VERSION ""

NS_ :

BS_:

BU_: VCM TCM OBDScanT2 ECM

BO_ 1059 VMCU_BB2_55P: 8 VCM
 SG_ BatteryCurrent : 16|16@1+ (0.05,-1600) [-1600|1676.75] "A"  ECM

BO_ 1240 VMCU_BB2_29P: 8 VCM
 SG_ FrontAxle2Load : 16|16@1+ (0.5,0) [0|32767.5] "kg"  TCM
 SG_ FrontAxle1Load : 0|16@1+ (0.5,0) [0|32767.5] "kg"  TCM

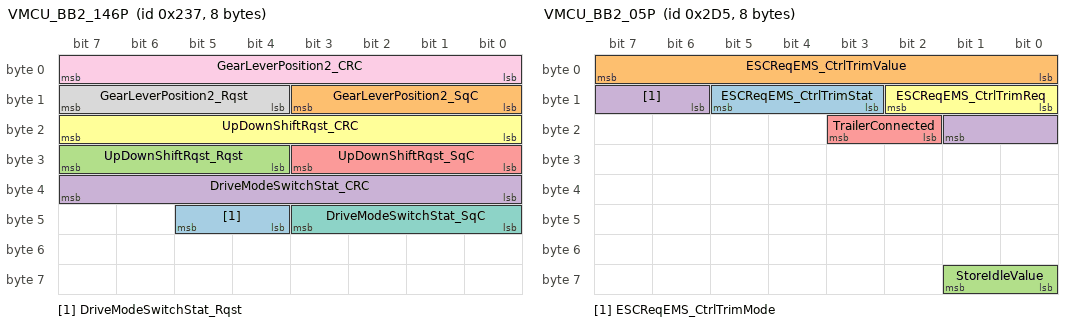
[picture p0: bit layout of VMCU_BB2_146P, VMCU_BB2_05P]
BO_ 567 VMCU_BB2_146P: 8 VCM
 SG_ DriveModeSwitchStat_Rqst : 44|2@1+ (1,0) [0|0] ""  TCM
 SG_ GearLeverPosition2_SqC : 8|4@1+ (1,0) [0|14] "NotApplicable"  TCM
 SG_ UpDownShiftRqst_Rqst : 28|4@1+ (1,0) [0|0] ""  TCM
 SG_ DriveModeSwitchStat_CRC : 32|8@1+ (1,0) [0|255] ""  TCM
 SG_ UpDownShiftRqst_SqC : 24|4@1+ (1,0) [0|14] "NotApplicable"  TCM
 SG_ UpDownShiftRqst_CRC : 16|8@1+ (1,0) [0|255] ""  TCM
 SG_ DriveModeSwitchStat_SqC : 40|4@1+ (1,0) [0|14] "NotApplicable"  TCM
 SG_ GearLeverPosition2_Rqst : 12|4@1+ (1,0) [0|0] ""  TCM
 SG_ GearLeverPosition2_CRC : 0|8@1+ (1,0) [0|255] ""  TCM

BO_ 725 VMCU_BB2_05P: 8 VCM
 SG_ ESCReqEMS_CtrlTrimStat : 11|3@1+ (1,0) [0|0] ""  ECM,TCM
 SG_ ESCReqEMS_CtrlTrimValue : 0|8@1+ (10,0) [0|2550] ""  ECM,TCM
 SG_ StoreIdleValue : 56|2@1+ (1,0) [0|0] ""  ECM
 SG_ ESCReqEMS_CtrlTrimMode : 14|4@1+ (1,0) [0|0] ""  TCM,ECM
 SG_ TrailerConnected : 18|2@1+ (1,0) [0|0] ""  ECM,TCM
 SG_ ESCReqEMS_CtrlTrimReq : 8|3@1+ (1,0) [0|0] ""  ECM,TCM

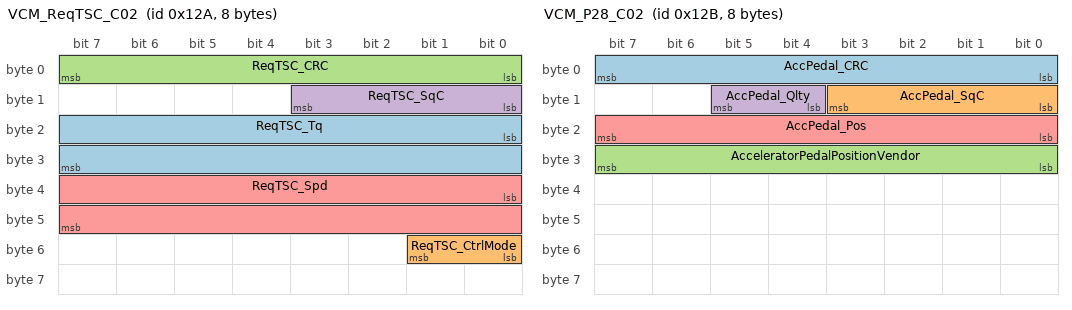
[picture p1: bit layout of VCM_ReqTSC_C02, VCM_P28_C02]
BO_ 298 VCM_ReqTSC_C02: 8 VCM
 SG_ ReqTSC_Tq : 16|16@1+ (1,-32128) [-32128|33407] "Nm"  TCM,ECM
 SG_ ReqTSC_CtrlMode : 48|2@1+ (1,0) [0|0] ""  ECM,TCM
 SG_ ReqTSC_CRC : 0|8@1+ (1,0) [0|255] ""  ECM,TCM
 SG_ ReqTSC_SqC : 8|4@1+ (1,0) [0|14] "NotApplicable"  TCM,ECM
 SG_ ReqTSC_Spd : 32|16@1+ (0.5,-16024) [-16024|16743.5] "rpm"  ECM,TCM

BO_ 299 VCM_P28_C02: 8 VCM
 SG_ AccPedal_CRC : 0|8@1+ (1,0) [0|255] ""  TCM,ECM
 SG_ AccPedal_SqC : 8|4@1+ (1,0) [0|14] "NotApplicable"  ECM,TCM
 SG_ AcceleratorPedalPositionVendor : 24|8@1+ (0.4,0) [0|102] "Percent"  TCM
 SG_ AccPedal_Qlty : 12|2@1+ (1,0) [0|0] ""  TCM,ECM
 SG_ AccPedal_Pos : 16|8@1+ (0.4,0) [0|102] "Percent"  ECM,TCM

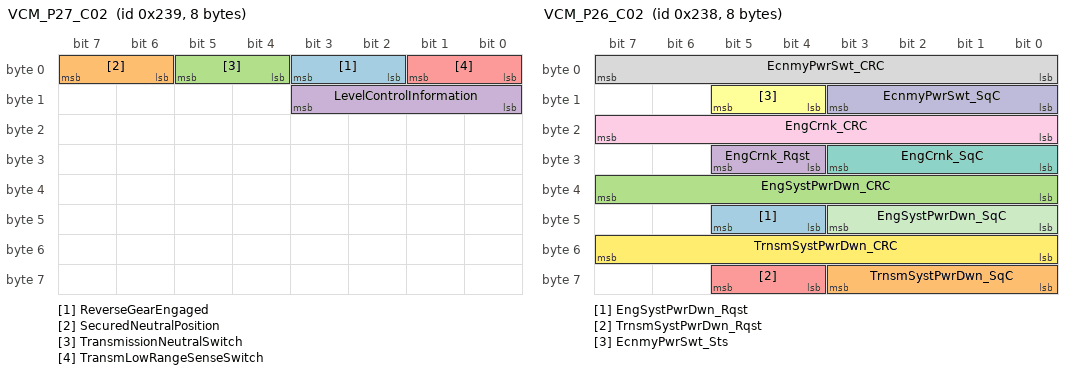
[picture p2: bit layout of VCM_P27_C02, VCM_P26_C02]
BO_ 569 VCM_P27_C02: 8 VCM
 SG_ ReverseGearEngaged : 2|2@1+ (1,0) [0|0] ""  ECM
 SG_ SecuredNeutralPosition : 6|2@1+ (1,0) [0|0] ""  ECM
 SG_ TransmissionNeutralSwitch : 4|2@1+ (1,0) [0|0] ""  ECM
 SG_ LevelControlInformation : 8|4@1+ (1,0) [0|0] ""  TCM
 SG_ TransmLowRangeSenseSwitch : 0|2@1+ (1,0) [0|0] ""  ECM

BO_ 568 VCM_P26_C02: 8 VCM
 SG_ EngSystPwrDwn_Rqst : 44|2@1+ (1,0) [0|0] ""  ECM
 SG_ TrnsmSystPwrDwn_SqC : 56|4@1+ (1,0) [0|14] "NotApplicable"  TCM
 SG_ EngSystPwrDwn_CRC : 32|8@1+ (1,0) [0|255] ""  ECM
 SG_ EngCrnk_Rqst : 28|2@1+ (1,0) [0|0] ""  ECM
 SG_ TrnsmSystPwrDwn_Rqst : 60|2@1+ (1,0) [0|0] ""  TCM
 SG_ EcnmyPwrSwt_Sts : 12|2@1+ (1,0) [0|0] ""  TCM
 SG_ EngCrnk_SqC : 24|4@1+ (1,0) [0|14] "NotApplicable"  ECM
 SG_ EcnmyPwrSwt_CRC : 0|8@1+ (1,0) [0|255] ""  TCM
 SG_ EngCrnk_CRC : 16|8@1+ (1,0) [0|255] ""  ECM
 SG_ EcnmyPwrSwt_SqC : 8|4@1+ (1,0) [0|14] "NotApplicable"  TCM
 SG_ EngSystPwrDwn_SqC : 40|4@1+ (1,0) [0|14] "NotApplicable"  ECM
 SG_ TrnsmSystPwrDwn_CRC : 48|8@1+ (1,0) [0|255] ""  TCM

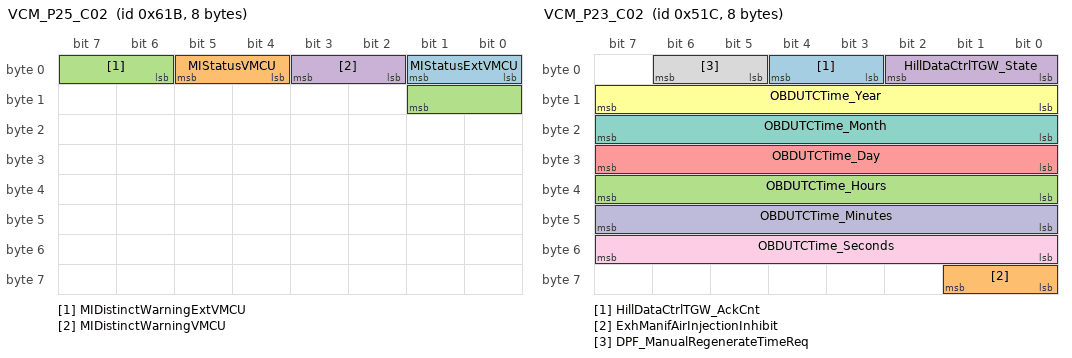
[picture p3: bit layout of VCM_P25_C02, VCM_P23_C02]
BO_ 1563 VCM_P25_C02: 8 VCM
 SG_ MIStatusExtVMCU : 0|2@1+ (1,0) [0|0] ""  ECM
 SG_ MIStatusVMCU : 4|2@1+ (1,0) [0|0] ""  ECM
 SG_ MIDistinctWarningExtVMCU : 6|4@1+ (1,0) [0|0] ""  ECM
 SG_ MIDistinctWarningVMCU : 2|2@1+ (1,0) [0|0] ""  ECM

BO_ 1310 VCM_P24_C02_FCM: 8 TCM
 SG_ VCM_P24_C02_FCS : 0|64@1+ (1,0) [0|0] ""  VCM

BO_ 1309 VCM_P24_C02: 284 VCM
 SG_ HillDataPkgTGW : 0|2272@1+ (1,0) [0|0] ""  TCM

BO_ 1308 VCM_P23_C02: 8 VCM
 SG_ HillDataCtrlTGW_AckCnt : 3|2@1+ (1,0) [0|3] ""  TCM
 SG_ ExhManifAirInjectionInhibit : 56|2@1+ (1,0) [0|0] ""  ECM
 SG_ OBDUTCTime_Hours : 32|8@1+ (1,0) [0|255] "h"  ECM
 SG_ HillDataCtrlTGW_State : 0|3@1+ (1,0) [0|0] ""  TCM
 SG_ OBDUTCTime_Day : 24|8@1+ (0.25,0) [0|63.75] "Days"  ECM
 SG_ OBDUTCTime_Year : 8|8@1+ (1,1985) [1985|2240] "Years"  ECM
 SG_ OBDUTCTime_Month : 16|8@1+ (1,0) [0|255] "Months"  ECM
 SG_ DPF_ManualRegenerateTimeReq : 5|2@1+ (1,0) [0|0] ""  ECM
 SG_ OBDUTCTime_Seconds : 48|8@1+ (0.25,0) [0|63.75] "s"  ECM
 SG_ OBDUTCTime_Minutes : 40|8@1+ (1,0) [0|255] "min"  ECM

BO_ 1307 VCM_P22_C02: 8 VCM
 SG_ OBD_Timestamp : 0|32@1+ (1,0) [0|4294967295] "s"  ECM

BO_ 1241 VCM_P21_C02: 8 VCM
 SG_ PwtCCUnderSpeedRequest : 8|16@1+ (0.00390625,0) [0|255.99609375] "Km_per_h"  TCM
 SG_ StarterMotorReset_rqst : 0|2@1+ (1,0) [0|0] ""  ECM

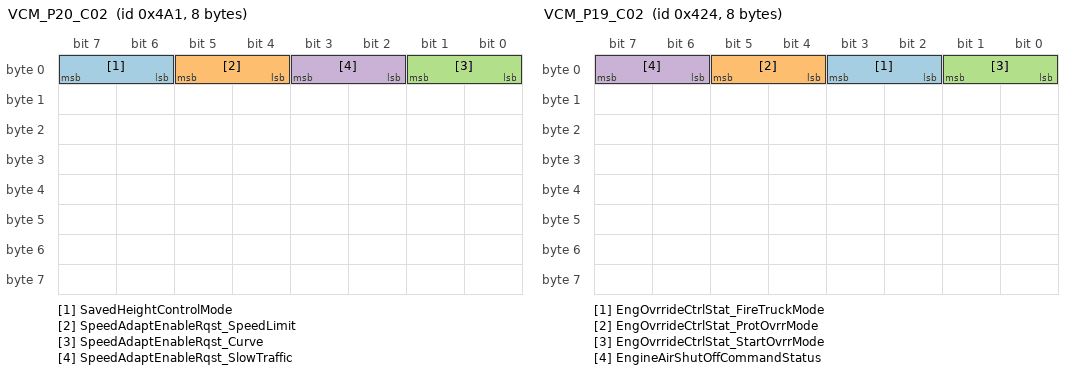
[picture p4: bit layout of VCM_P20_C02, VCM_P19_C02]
BO_ 1185 VCM_P20_C02: 8 VCM
 SG_ SavedHeightControlMode : 6|2@1+ (1,0) [0|0] ""  TCM
 SG_ SpeedAdaptEnableRqst_SpeedLimit : 4|2@1+ (1,0) [0|0] ""  TCM
 SG_ SpeedAdaptEnableRqst_Curve : 0|2@1+ (1,0) [0|0] ""  TCM
 SG_ SpeedAdaptEnableRqst_SlowTraffic : 2|2@1+ (1,0) [0|0] ""  TCM

BO_ 1060 VCM_P19_C02: 8 VCM
 SG_ EngOvrrideCtrlStat_FireTruckMode : 2|2@1+ (1,0) [0|0] ""  ECM
 SG_ EngOvrrideCtrlStat_ProtOvrrMode : 4|2@1+ (1,0) [0|0] ""  ECM
 SG_ EngOvrrideCtrlStat_StartOvrrMode : 0|2@1+ (1,0) [0|0] ""  ECM
 SG_ EngineAirShutOffCommandStatus : 6|2@1+ (1,0) [0|0] ""  ECM

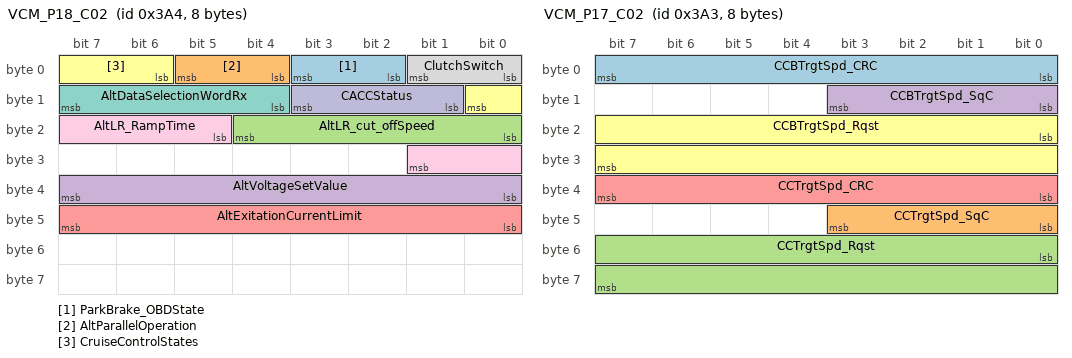
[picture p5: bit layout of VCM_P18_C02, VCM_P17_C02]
BO_ 932 VCM_P18_C02: 8 VCM
 SG_ ParkBrake_OBDState : 2|2@1+ (1,0) [0|0] ""  ECM
 SG_ AltParallelOperation : 4|2@1+ (1,0) [0|0] ""  ECM
 SG_ AltLR_cut_offSpeed : 16|5@1+ (1,0) [0|0] ""  ECM
 SG_ AltVoltageSetValue : 32|8@1+ (0.1,22) [22|47.5] "V"  ECM
 SG_ AltExitationCurrentLimit : 40|8@1+ (0.1,0) [0|25.5] "A"  ECM
 SG_ CruiseControlStates : 6|3@1+ (1,0) [0|0] ""  ECM,TCM
 SG_ AltDataSelectionWordRx : 12|4@1+ (1,0) [0|0] ""  ECM
 SG_ ClutchSwitch : 0|2@1+ (1,0) [0|0] ""  ECM
 SG_ AltLR_RampTime : 21|5@1+ (1,0) [0|0] ""  ECM
 SG_ CACCStatus : 9|3@1+ (1,0) [0|0] ""  TCM

BO_ 931 VCM_P17_C02: 8 VCM
 SG_ CCBTrgtSpd_CRC : 0|8@1+ (1,0) [0|255] ""  ECM,TCM
 SG_ CCTrgtSpd_SqC : 40|4@1+ (1,0) [0|14] "NotApplicable"  ECM,TCM
 SG_ CCTrgtSpd_Rqst : 48|16@1+ (0.00390625,0) [0|255.99609375] "Km_per_h"  ECM,TCM
 SG_ CCBTrgtSpd_SqC : 8|4@1+ (1,0) [0|14] "NotApplicable"  ECM,TCM
 SG_ CCTrgtSpd_CRC : 32|8@1+ (1,0) [0|255] ""  ECM,TCM
 SG_ CCBTrgtSpd_Rqst : 16|16@1+ (0.00390625,0) [0|255.99609375] "Km_per_h"  TCM,ECM

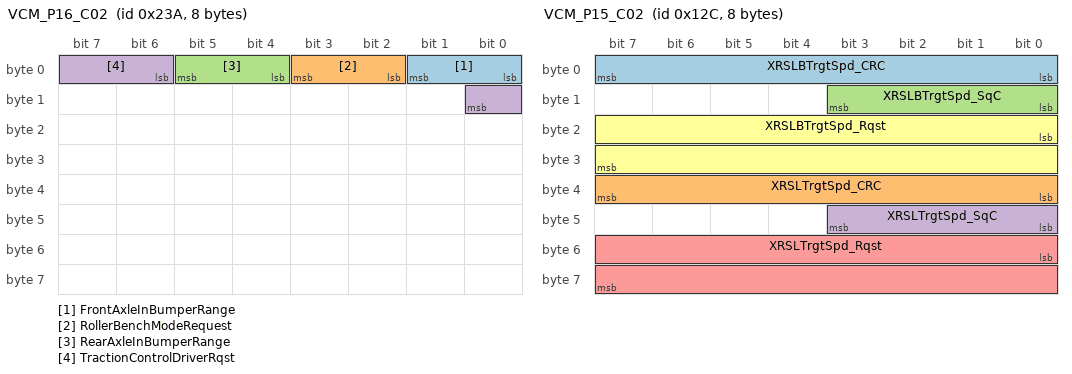
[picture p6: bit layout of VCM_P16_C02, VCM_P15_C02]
BO_ 570 VCM_P16_C02: 8 VCM
 SG_ FrontAxleInBumperRange : 0|2@1+ (1,0) [0|0] ""  TCM
 SG_ RollerBenchModeRequest : 2|2@1+ (1,0) [0|0] ""  ECM
 SG_ RearAxleInBumperRange : 4|2@1+ (1,0) [0|0] ""  TCM
 SG_ TractionControlDriverRqst : 6|3@1+ (1,0) [0|0] ""  ECM

BO_ 300 VCM_P15_C02: 8 VCM
 SG_ XRSLBTrgtSpd_CRC : 0|8@1+ (1,0) [0|255] ""  TCM,ECM
 SG_ XRSLTrgtSpd_CRC : 32|8@1+ (1,0) [0|255] ""  ECM
 SG_ XRSLBTrgtSpd_SqC : 8|4@1+ (1,0) [0|14] "NotApplicable"  TCM,ECM
 SG_ XRSLTrgtSpd_SqC : 40|4@1+ (1,0) [0|14] "NotApplicable"  ECM
 SG_ XRSLTrgtSpd_Rqst : 48|16@1+ (0.00390625,0) [0|255.99609375] "Km_per_h"  ECM
 SG_ XRSLBTrgtSpd_Rqst : 16|16@1+ (0.00390625,0) [0|255.99609375] "Km_per_h"  ECM,TCM

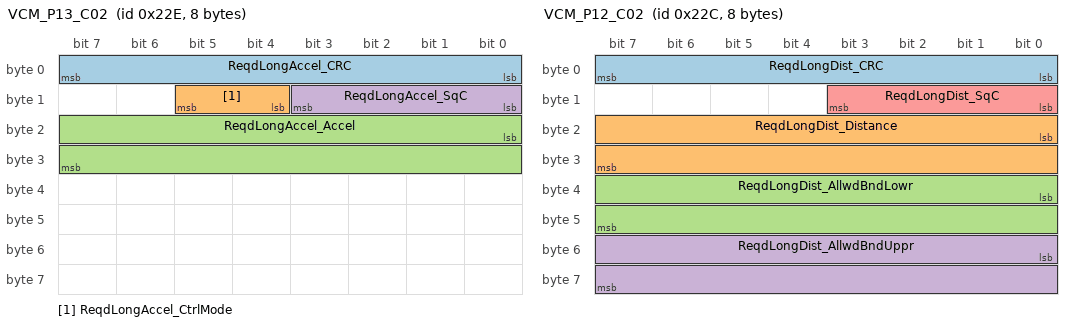
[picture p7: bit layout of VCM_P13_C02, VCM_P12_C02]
BO_ 558 VCM_P13_C02: 8 VCM
 SG_ ReqdLongAccel_CRC : 0|8@1+ (1,0) [0|255] ""  ECM,TCM
 SG_ ReqdLongAccel_CtrlMode : 12|2@1+ (1,0) [0|0] ""  TCM,ECM
 SG_ ReqdLongAccel_Accel : 16|16@1+ (0.00048828125,-15.687) [-15.687|16.31251171875] "m_per_s_squared"  ECM,TCM
 SG_ ReqdLongAccel_SqC : 8|4@1+ (1,0) [0|14] "NotApplicable"  TCM,ECM

BO_ 556 VCM_P12_C02: 8 VCM
 SG_ ReqdLongDist_CRC : 0|8@1+ (1,0) [0|255] ""  TCM
 SG_ ReqdLongDist_Distance : 16|16@1+ (0.01,0) [0|655.35] "m"  TCM
 SG_ ReqdLongDist_AllwdBndLowr : 32|16@1+ (0.01,0) [0|655.35] "m"  TCM
 SG_ ReqdLongDist_AllwdBndUppr : 48|16@1+ (0.01,0) [0|655.35] "m"  TCM
 SG_ ReqdLongDist_SqC : 8|4@1+ (1,0) [0|14] "NotApplicable"  TCM

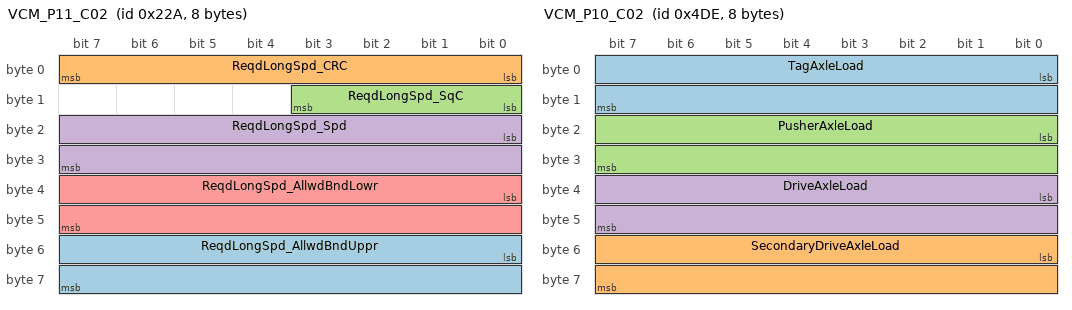
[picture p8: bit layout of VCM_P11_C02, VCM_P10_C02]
BO_ 554 VCM_P11_C02: 8 VCM
 SG_ ReqdLongSpd_AllwdBndUppr : 48|16@1+ (0.00390625,0) [0|255.99609375] "Km_per_h"  ECM,TCM
 SG_ ReqdLongSpd_CRC : 0|8@1+ (1,0) [0|255] ""  TCM,ECM
 SG_ ReqdLongSpd_SqC : 8|4@1+ (1,0) [0|14] "NotApplicable"  TCM,ECM
 SG_ ReqdLongSpd_Spd : 16|16@1+ (0.00390625,0) [0|255.99609375] "Km_per_h"  TCM,ECM
 SG_ ReqdLongSpd_AllwdBndLowr : 32|16@1+ (0.00390625,0) [0|255.99609375] "Km_per_h"  TCM,ECM

BO_ 1246 VCM_P10_C02: 8 VCM
 SG_ TagAxleLoad : 0|16@1+ (0.5,0) [0|32767.5] "kg"  TCM
 SG_ SecondaryDriveAxleLoad : 48|16@1+ (0.5,0) [0|32767.5] "kg"  ECM,TCM
 SG_ PusherAxleLoad : 16|16@1+ (0.5,0) [0|32767.5] "kg"  TCM
 SG_ DriveAxleLoad : 32|16@1+ (0.5,0) [0|32767.5] "kg"  TCM

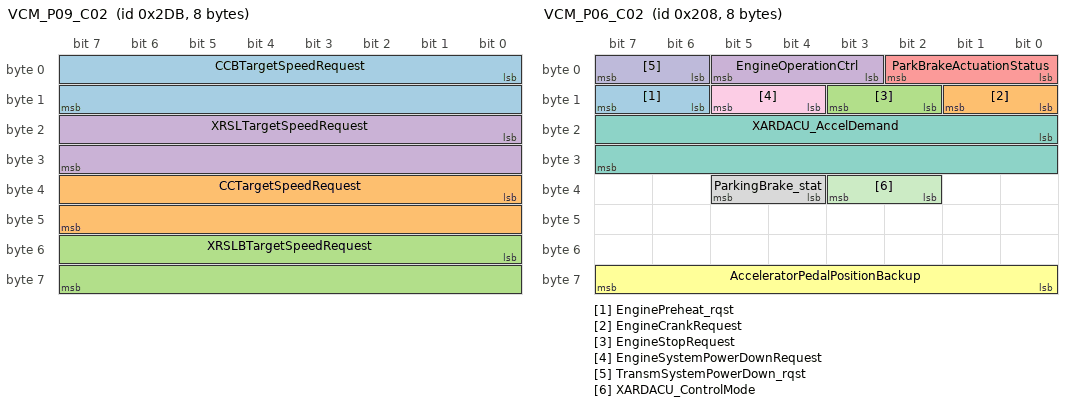
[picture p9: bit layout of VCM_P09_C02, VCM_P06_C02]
BO_ 731 VCM_P09_C02: 8 VCM
 SG_ CCBTargetSpeedRequest : 0|16@1+ (0.00390625,0) [0|255.99609375] "Km_per_h"  TCM,ECM
 SG_ CCTargetSpeedRequest : 32|16@1+ (0.00390625,0) [0|255.99609375] "Km_per_h"  TCM,ECM
 SG_ XRSLBTargetSpeedRequest : 48|16@1+ (0.00390625,0) [0|255.99609375] "Km_per_h"  TCM,ECM
 SG_ XRSLTargetSpeedRequest : 16|16@1+ (0.00390625,0) [0|255.99609375] "Km_per_h"  ECM

BO_ 742 VCM_P08_C02: 8 VCM
 SG_ CCBSetSpeed : 0|16@1+ (0.00390625,0) [0|255.99609375] "Km_per_h"  TCM
 SG_ CCSetSpeed : 16|16@1+ (0.00390625,0) [0|255.99609375] "Km_per_h"  TCM

BO_ 746 VCM_P07_C02: 8 VCM
 SG_ Pto1ConsentRequest : 24|2@1+ (1,0) [0|0] ""  TCM
 SG_ SecondThrottle : 34|2@1+ (1,0) [0|0] ""  ECM
 SG_ TransferCaseOrSplitboxPTOMode : 26|2@1+ (1,0) [0|0] ""  TCM
 SG_ PtosStatus : 36|2@1+ (1,0) [0|0] ""  ECM
 SG_ ConstructionSwitch_stat : 4|2@1+ (1,0) [0|0] ""  TCM
 SG_ RegenInhibitVehicleHeight : 16|2@1+ (1,0) [0|0] ""  ECM
 SG_ PtoRequest : 18|2@1+ (1,0) [0|0] ""  ECM
 SG_ Pto2Status : 22|2@1+ (1,0) [0|0] ""  TCM
 SG_ WarmUp_Request : 42|2@1+ (1,0) [0|0] ""  ECM
 SG_ ParkBrakeReleasePossible_stat : 14|2@1+ (1,0) [0|0] ""  TCM
 SG_ AC_CompressorClutchCmd : 0|2@1+ (1,0) [0|0] ""  ECM
 SG_ Pto1Status : 20|2@1+ (1,0) [0|0] ""  TCM
 SG_ CtaGcAlternativeGearStarter : 6|2@1+ (1,0) [0|0] ""  TCM
 SG_ Pto2ConsentRequest : 32|2@1+ (1,0) [0|0] ""  TCM
 SG_ EngPtoConsumesTorque : 12|2@1+ (1,0) [0|0] ""  TCM
 SG_ TrailerABSStatus : 40|2@1+ (1,0) [0|0] ""  ECM,TCM
 SG_ CtaGcInhibitGearEngaged : 8|2@1+ (1,0) [0|0] ""  TCM
 SG_ RearEndPositionStatus : 28|3@1+ (1,0) [0|0] ""  TCM
 SG_ CtaGcReverseInhibit : 10|2@1+ (1,0) [0|0] ""  TCM
 SG_ AirCompressorStatus : 2|2@1+ (1,0) [0|0] ""  ECM

BO_ 520 VCM_P06_C02: 8 VCM
 SG_ EnginePreheat_rqst : 14|2@1+ (1,0) [0|0] ""  ECM
 SG_ EngineCrankRequest : 8|2@1+ (1,0) [0|0] ""  ECM
 SG_ EngineStopRequest : 10|2@1+ (1,0) [0|0] ""  ECM
 SG_ EngineOperationCtrl : 3|3@1+ (1,0) [0|0] ""  TCM,ECM
 SG_ ParkBrakeActuationStatus : 0|3@1+ (1,0) [0|0] ""  TCM
 SG_ AcceleratorPedalPositionBackup : 56|8@1+ (0.4,0) [0|102] "Percent"  TCM,ECM
 SG_ XARDACU_AccelDemand : 16|16@1+ (0.00048828125,-15.687) [-15.687|16.31251171875] "m_per_s_squared"  ECM,TCM
 SG_ ParkingBrake_stat : 36|2@1+ (1,0) [0|0] ""  TCM,ECM
 SG_ EngineSystemPowerDownRequest : 12|2@1+ (1,0) [0|0] ""  ECM
 SG_ TransmSystemPowerDown_rqst : 6|2@1+ (1,0) [0|0] ""  TCM
 SG_ XARDACU_ControlMode : 34|2@1+ (1,0) [0|0] ""  ECM,TCM

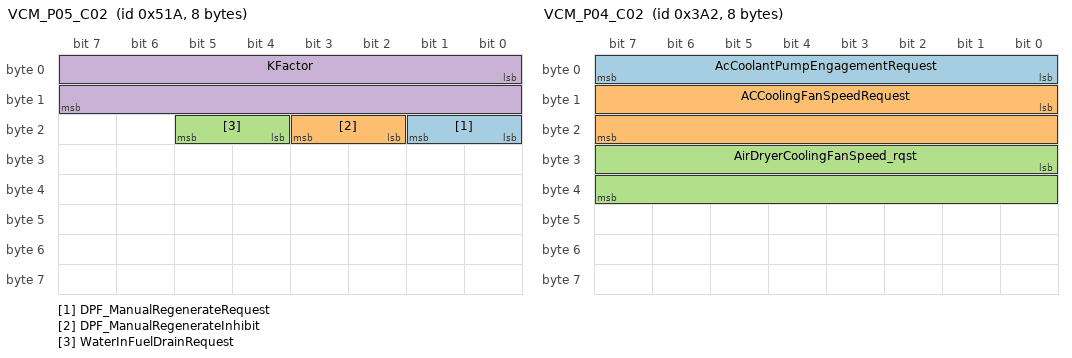
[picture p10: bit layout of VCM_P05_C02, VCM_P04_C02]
BO_ 1306 VCM_P05_C02: 8 VCM
 SG_ DPF_ManualRegenerateRequest : 16|2@1+ (1,0) [0|0] ""  ECM
 SG_ DPF_ManualRegenerateInhibit : 18|2@1+ (1,0) [0|0] ""  ECM
 SG_ WaterInFuelDrainRequest : 20|2@1+ (1,0) [0|0] ""  ECM
 SG_ KFactor : 0|16@1+ (1,0) [0|65535] "NotApplicable"  TCM,ECM

BO_ 930 VCM_P04_C02: 8 VCM
 SG_ AcCoolantPumpEngagementRequest : 0|8@1+ (0.4,0) [0|102] "Percent"  ECM
 SG_ ACCoolingFanSpeedRequest : 8|16@1+ (1,0) [0|65535] "rpm"  ECM
 SG_ AirDryerCoolingFanSpeed_rqst : 24|16@1+ (1,0) [0|65535] "rpm"  ECM

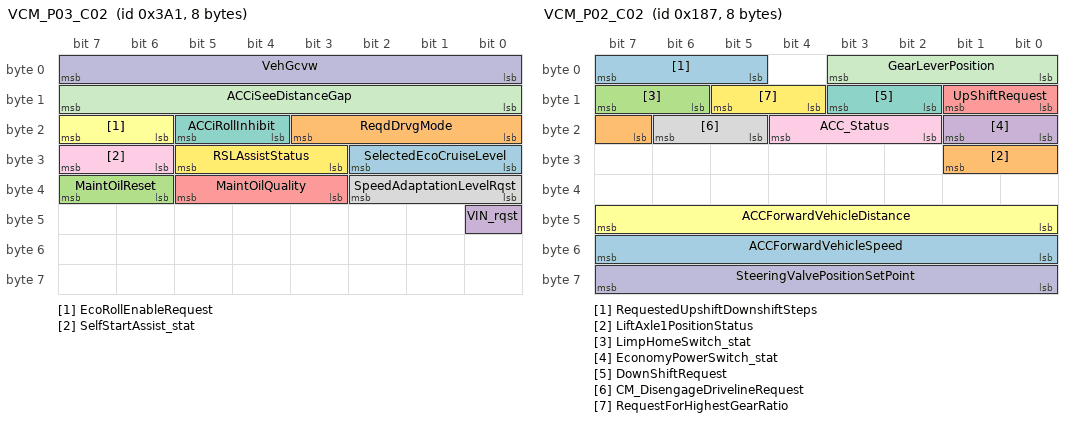
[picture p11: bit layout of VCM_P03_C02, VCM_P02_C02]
BO_ 929 VCM_P03_C02: 8 VCM
 SG_ SelectedEcoCruiseLevel : 24|3@1+ (1,0) [0|0] ""  ECM,TCM
 SG_ ReqdDrvgMode : 16|4@1+ (1,0) [0|0] ""  TCM
 SG_ MaintOilReset : 38|2@1+ (1,0) [0|0] ""  ECM
 SG_ VIN_rqst : 40|1@1+ (1,0) [0|0] ""  ECM,TCM
 SG_ MaintOilQuality : 35|3@1+ (1,0) [0|0] ""  ECM
 SG_ EcoRollEnableRequest : 22|2@1+ (1,0) [0|0] ""  TCM
 SG_ ACCiRollInhibit : 20|2@1+ (1,0) [0|0] ""  TCM
 SG_ SpeedAdaptationLevelRqst : 32|3@1+ (1,0) [0|0] ""  TCM
 SG_ SelfStartAssist_stat : 30|2@1+ (1,0) [0|0] ""  ECM
 SG_ VehGcvw : 0|8@1+ (1000,0) [0|255000] "kg"  TCM,ECM
 SG_ ACCiSeeDistanceGap : 8|8@1+ (1,-127) [-127|128] "m"  TCM
 SG_ RSLAssistStatus : 27|3@1+ (1,0) [0|0] ""  TCM

BO_ 391 VCM_P02_C02: 8 VCM
 SG_ RequestedUpshiftDownshiftSteps : 5|3@1+ (1,0) [0|0] ""  TCM
 SG_ LiftAxle1PositionStatus : 23|3@1+ (1,0) [0|0] ""  TCM
 SG_ LimpHomeSwitch_stat : 14|2@1+ (1,0) [0|0] ""  TCM
 SG_ EconomyPowerSwitch_stat : 16|2@1+ (1,0) [0|0] ""  TCM
 SG_ UpShiftRequest : 8|2@1+ (1,0) [0|0] ""  ECM,TCM
 SG_ ACCForwardVehicleDistance : 40|8@1+ (1,0) [0|255] "m"  TCM
 SG_ DownShiftRequest : 10|2@1+ (1,0) [0|0] ""  ECM,TCM
 SG_ CM_DisengageDrivelineRequest : 21|2@1+ (1,0) [0|0] ""  TCM
 SG_ ACC_Status : 18|3@1+ (1,0) [0|0] ""  TCM
 SG_ SteeringValvePositionSetPoint : 56|8@1+ (1,0) [0|255] "Percent"  ECM
 SG_ GearLeverPosition : 0|4@1+ (1,0) [0|0] ""  ECM,TCM
 SG_ RequestForHighestGearRatio : 12|2@1+ (1,0) [0|0] ""  TCM
 SG_ ACCForwardVehicleSpeed : 48|8@1+ (1,0) [0|255] "Km_per_h"  TCM

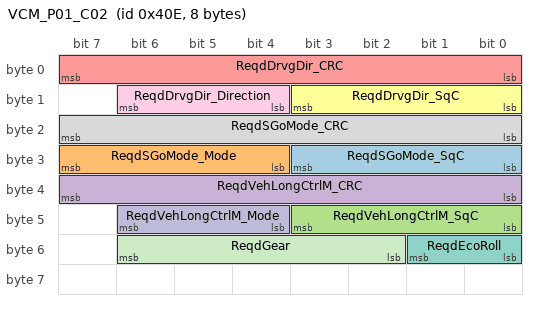
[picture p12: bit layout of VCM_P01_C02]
BO_ 1038 VCM_P01_C02: 8 VCM
 SG_ ReqdSGoMode_SqC : 24|4@1+ (1,0) [0|14] "NotApplicable"  ECM,TCM
 SG_ ReqdSGoMode_Mode : 28|4@1+ (1,0) [0|0] ""  ECM,TCM
 SG_ ReqdVehLongCtrlM_SqC : 40|4@1+ (1,0) [0|14] "NotApplicable"  ECM,TCM
 SG_ ReqdVehLongCtrlM_CRC : 32|8@1+ (1,0) [0|255] ""  TCM,ECM
 SG_ ReqdDrvgDir_CRC : 0|8@1+ (1,0) [0|255] ""  TCM
 SG_ ReqdDrvgDir_SqC : 8|4@1+ (1,0) [0|14] "NotApplicable"  TCM
 SG_ ReqdEcoRoll : 48|2@1+ (1,0) [0|0] ""  TCM
 SG_ ReqdSGoMode_CRC : 16|8@1+ (1,0) [0|255] ""  ECM,TCM
 SG_ ReqdDrvgDir_Direction : 12|3@1+ (1,0) [0|0] ""  TCM
 SG_ ReqdVehLongCtrlM_Mode : 44|3@1+ (1,0) [0|0] ""  TCM,ECM
 SG_ ReqdGear : 50|5@1+ (1,-12) [-12|19] "NotApplicable"  TCM

BO_ 531 VCM_HorizonData_C02: 8 VCM
 SG_ HorizonData : 7|64@0+ (1,0) [0|0] ""  TCM

BO_ 2671902706 TesterFuncDiagMsg_C02: 8 VCM
 SG_ FuncDiagDataTester : 0|64@1+ (1,0) [0|0] ""  TCM,ECM

BO_ 2671902708 TesterFuncDiagMsgF4_C02: 8 VCM
 SG_ FuncDiagDataIntTesterF4 : 0|64@1+ (1,0) [0|0] ""  ECM,TCM

BO_ 1252 TECU_BB2_11P_FCM: 8 VCM
 SG_ TECU_BB2_11P_FCS : 0|64@1+ (1,0) [0|0] ""  TCM

BO_ 1251 TECU_BB2_11P: 284 TCM
 SG_ HillDataPkgTECU : 0|2272@1+ (1,0) [0|0] ""  VCM

BO_ 1250 TECU_BB2_10P: 8 TCM
 SG_ HillDataCtrlTECU_State : 0|3@1+ (1,0) [0|0] ""  VCM
 SG_ HillDataCtrlTECU_AckCnt : 3|2@1+ (1,0) [0|3] ""  VCM

BO_ 1046 TECU_BB2_09P: 8 TCM
 SG_ DriveModeSwitchUserOverride : 0|3@1+ (1,0) [0|0] ""  VCM

CM_ "COM_MATRIX_T3_1.9.0";
CM_ BU_ VCM "Vehicle Control Module";
CM_ BU_ TCM "Transmission Control Module";
CM_ BU_ ECM "Engine Control Module";
CM_ SG_ 725 ESCReqEMS_CtrlTrimValue "254 Error ; 255 Not available";
CM_ SG_ 520 XARDACU_AccelDemand "65024 - 65279 Error ; 65280 - 65535 Not available";
BA_DEF_ BO_  "GenMsgStartDelayTime" INT 0 0;
BA_DEF_ BO_  "GenMsgDelayTime" INT 0 0;
BA_DEF_ BO_  "GenMsgCycleTime" INT 0 0;
BA_DEF_ BO_  "GenMsgSendType" ENUM  "Cyclic","NotUsed","NotUsed","NotUsed","NotUsed","NotUsed","NotUsed","IfActive","NoMsgSendType","NotUsed";
BA_DEF_ SG_  "GenSigStartValue" INT 0 0;
BA_DEF_ SG_  "GenSigCycleTimeActive" INT 0 0;
BA_DEF_ SG_  "GenSigCycleTime" INT 0 0;
BA_DEF_ SG_  "GenSigSendType" ENUM  "Cyclic","OnWrite","OnWriteWithRepetition","OnChange","OnChangeWithRepetition","IfActive","IfActiveWithRepetition","NoSigSendType","NotUsed","NotUsed","NotUsed","NotUsed","NotUsed";
BA_DEF_  "Baudrate" INT 0 1000000;
BA_DEF_  "NmType" STRING ;
BA_DEF_  "Manufacturer" STRING ;
BA_DEF_  "VersionYear" INT 0 99;
BA_DEF_  "VersionNumber" INT 0 99;
BA_DEF_  "VersionMonth" INT 1 12;
BA_DEF_  "VersionDay" INT 1 31;
BA_DEF_ BO_  "VFrameFormat" ENUM  "StandardCAN","ExtendedCAN","reserved","J1939PG","reserved","reserved","reserved","reserved","reserved","reserved","reserved","reserved","reserved","reserved","StandardCAN_FD","ExtendedCAN_FD";
BA_DEF_ BU_  "TpOwnSystemEcuNumber" HEX 0 255;
BA_DEF_ SG_  "SigType" ENUM  "Default","Range","RangeSigned","ASCII","Discrete","Control","ReferencePGN","DTC","StringDelimiter","StringLength","StringLengthControl";
BA_DEF_ SG_  "SeToolVersion_SIGNAL" STRING ;
BA_DEF_ SG_  "SeToolUniqueID_SIGNAL" STRING ;
BA_DEF_ SG_  "SeToolOwnerSigGroup_SIGNAL" STRING ;
BA_DEF_ SG_  "SeToolOwnerSigGroupID_SIGNAL" STRING ;
BA_DEF_ SG_  "SeToolName_SIGNAL" STRING ;
BA_DEF_ SG_  "SeToolItemID_SIGNAL" STRING ;
BA_DEF_ SG_  "SeToolAncestorID_SIGNAL" STRING ;
BA_DEF_ SG_  "Platform_VMCU1_Sig" ENUM  "No","Yes";
BA_DEF_ BU_  "NmStationAddress" INT 0 255;
BA_DEF_  "NmAsrWaitBusSleepTime" INT 0 65535;
BA_DEF_  "NmAsrTimeoutTime" INT 0 65535;
BA_DEF_  "NmAsrRepeatMessageTime" INT 0 65535;
BA_DEF_ BU_  "NmAsrNodeIdentifier" HEX 0 253;
BA_DEF_ BU_  "NmAsrNode" ENUM  "No","Yes";
BA_DEF_  "NmAsrMessageCount" INT 1 256;
BA_DEF_ BO_  "NmAsrMessage" ENUM  "No","Yes";
BA_DEF_  "NmAsrCanMsgCycleTime" INT 0 65535;
BA_DEF_  "NmAsrBaseAddress" HEX 0 536870911;
BA_DEF_ SG_  "MmAnSignal" ENUM  "No","Yes";
BA_DEF_ BU_  "IsOBDrelevant" ENUM  "No","Yes";
BA_DEF_ SG_  "GenSigMaxLatency" INT 0 65535;
BA_DEF_ SG_  "GenSigILSupport" ENUM  "Yes","No";
BA_DEF_ BO_  "GenMsgILSupport" ENUM  "No","Yes";
BA_DEF_ SG_  "E2EProfile" STRING ;
BA_DEF_  "E2EP05WindowSize" INT 0 65535;
BA_DEF_  "E2EP05ProfileName" STRING ;
BA_DEF_  "E2EP05MinOkStateValid" INT 0 65535;
BA_DEF_  "E2EP05MinOkStateInvalid" INT 0 65535;
BA_DEF_  "E2EP05MinOkStateInit" INT 0 65535;
BA_DEF_  "E2EP05MaxErrorStateValid" INT 0 65535;
BA_DEF_  "E2EP05MaxErrorStateInvalid" INT 0 65535;
BA_DEF_  "E2EP05MaxErrorStateInit" INT 0 65535;
BA_DEF_  "E2EP05MaxDeltaCounter" INT 0 65535;
BA_DEF_  "E2EP01WindowSize" INT 0 65535;
BA_DEF_  "E2EP01SyncCounterInit" INT 0 65535;
BA_DEF_  "E2EP01ProfileName" STRING ;
BA_DEF_  "E2EP01MinOkStateValid" INT 0 65535;
BA_DEF_  "E2EP01MinOkStateInvalid" INT 0 65535;
BA_DEF_  "E2EP01MinOkStateInit" INT 0 65535;
BA_DEF_  "E2EP01MaxNoNewOrRepeatedData" INT 0 65535;
BA_DEF_  "E2EP01MaxErrorStateValid" INT 0 65535;
BA_DEF_  "E2EP01MaxErrorStateInvalid" INT 0 65535;
BA_DEF_  "E2EP01MaxErrorStateInit" INT 0 65535;
BA_DEF_  "E2EP01MaxDeltaCounter" INT 0 65535;
BA_DEF_  "E2EP01DataIdMode" ENUM  "all16Bit","alternating8Bit","lower12Bit","lower8Bit";
BA_DEF_  "E2EP01CounterOffset" INT 0 65535;
BA_DEF_ SG_  "E2EDataLength" INT 0 65535;
BA_DEF_ SG_  "E2EDataId" INT 0 65535;
BA_DEF_ BU_  "DiagnosticClientAddress" HEX 0 255;
BA_DEF_ BO_  "DiagUUDTResponse" ENUM  "No","Yes";
BA_DEF_ BO_  "DiagState" ENUM  "No","Yes";
BA_DEF_ BU_  "DiagRole" ENUM  "None","OBDTester","ExternalTester","InternalTester";
BA_DEF_ BO_  "DiagResponse" ENUM  "No","Yes";
BA_DEF_ BO_  "DiagRequest" ENUM  "No","Yes";
BA_DEF_ BO_  "DiagConnection" HEX 0 65535;
BA_DEF_  "DBName" STRING ;
BA_DEF_ BO_  "CanTpFcFrameId" HEX 0 2147483647;
BA_DEF_ BO_  "CanTpBs" INT 0 255;
BA_DEF_ BO_  "CANFD_BRS" ENUM  "0","1";
BA_DEF_  "BusType" STRING ;
BA_DEF_REL_ BU_SG_REL_  "GenSigTimeoutTime" INT 0 65535;
BA_DEF_REL_ BU_SG_REL_  "GenSigFirstTimeoutTime" INT 0 65535;
BA_DEF_DEF_  "GenMsgStartDelayTime" 0;
BA_DEF_DEF_  "GenMsgDelayTime" 0;
BA_DEF_DEF_  "GenMsgCycleTime" 0;
BA_DEF_DEF_  "GenMsgSendType" "Cyclic";
BA_DEF_DEF_  "GenSigStartValue" 0;
BA_DEF_DEF_  "GenSigCycleTimeActive" 0;
BA_DEF_DEF_  "GenSigCycleTime" 0;
BA_DEF_DEF_  "GenSigSendType" "Cyclic";
BA_DEF_DEF_  "Baudrate" 500000;
BA_DEF_DEF_  "NmType" "";
BA_DEF_DEF_  "Manufacturer" "VOLVO_AB";
BA_DEF_DEF_  "VersionYear" 0;
BA_DEF_DEF_  "VersionNumber" 0;
BA_DEF_DEF_  "VersionMonth" 1;
BA_DEF_DEF_  "VersionDay" 1;
BA_DEF_DEF_  "VFrameFormat" "ExtendedCAN";
BA_DEF_DEF_  "TpOwnSystemEcuNumber" 0;
BA_DEF_DEF_  "SigType" "Default";
BA_DEF_DEF_  "SeToolVersion_SIGNAL" "";
BA_DEF_DEF_  "SeToolUniqueID_SIGNAL" "";
BA_DEF_DEF_  "SeToolOwnerSigGroup_SIGNAL" "";
BA_DEF_DEF_  "SeToolOwnerSigGroupID_SIGNAL" "";
BA_DEF_DEF_  "SeToolName_SIGNAL" "";
BA_DEF_DEF_  "SeToolItemID_SIGNAL" "";
BA_DEF_DEF_  "SeToolAncestorID_SIGNAL" "";
BA_DEF_DEF_  "Platform_VMCU1_Sig" "No";
BA_DEF_DEF_  "NmStationAddress" 254;
BA_DEF_DEF_  "NmAsrWaitBusSleepTime" 750;
BA_DEF_DEF_  "NmAsrTimeoutTime" 5000;
BA_DEF_DEF_  "NmAsrRepeatMessageTime" 300;
BA_DEF_DEF_  "NmAsrNodeIdentifier" 0;
BA_DEF_DEF_  "NmAsrNode" "Yes";
BA_DEF_DEF_  "NmAsrMessageCount" 256;
BA_DEF_DEF_  "NmAsrMessage" "No";
BA_DEF_DEF_  "NmAsrCanMsgCycleTime" 200;
BA_DEF_DEF_  "NmAsrBaseAddress" 486506496;
BA_DEF_DEF_  "MmAnSignal" "No";
BA_DEF_DEF_  "IsOBDrelevant" "No";
BA_DEF_DEF_  "GenSigMaxLatency" 0;
BA_DEF_DEF_  "GenSigILSupport" "Yes";
BA_DEF_DEF_  "GenMsgILSupport" "Yes";
BA_DEF_DEF_  "E2EProfile" "none";
BA_DEF_DEF_  "E2EP05WindowSize" 5;
BA_DEF_DEF_  "E2EP05ProfileName" "PROFILE_05";
BA_DEF_DEF_  "E2EP05MinOkStateValid" 1;
BA_DEF_DEF_  "E2EP05MinOkStateInvalid" 3;
BA_DEF_DEF_  "E2EP05MinOkStateInit" 1;
BA_DEF_DEF_  "E2EP05MaxErrorStateValid" 3;
BA_DEF_DEF_  "E2EP05MaxErrorStateInvalid" 1;
BA_DEF_DEF_  "E2EP05MaxErrorStateInit" 2;
BA_DEF_DEF_  "E2EP05MaxDeltaCounter" 1;
BA_DEF_DEF_  "E2EP01WindowSize" 5;
BA_DEF_DEF_  "E2EP01SyncCounterInit" 1;
BA_DEF_DEF_  "E2EP01ProfileName" "PROFILE_01";
BA_DEF_DEF_  "E2EP01MinOkStateValid" 1;
BA_DEF_DEF_  "E2EP01MinOkStateInvalid" 3;
BA_DEF_DEF_  "E2EP01MinOkStateInit" 1;
BA_DEF_DEF_  "E2EP01MaxNoNewOrRepeatedData" 5;
BA_DEF_DEF_  "E2EP01MaxErrorStateValid" 3;
BA_DEF_DEF_  "E2EP01MaxErrorStateInvalid" 1;
BA_DEF_DEF_  "E2EP01MaxErrorStateInit" 2;
BA_DEF_DEF_  "E2EP01MaxDeltaCounter" 1;
BA_DEF_DEF_  "E2EP01DataIdMode" "all16Bit";
BA_DEF_DEF_  "E2EP01CounterOffset" 8;
BA_DEF_DEF_  "E2EDataLength" 0;
BA_DEF_DEF_  "E2EDataId" 0;
BA_DEF_DEF_  "DiagnosticClientAddress" 0;
BA_DEF_DEF_  "DiagUUDTResponse" "No";
BA_DEF_DEF_  "DiagState" "No";
BA_DEF_DEF_  "DiagRole" "None";
BA_DEF_DEF_  "DiagResponse" "No";
BA_DEF_DEF_  "DiagRequest" "No";
BA_DEF_DEF_  "DiagConnection" 0;
BA_DEF_DEF_  "DBName" "";
BA_DEF_DEF_  "CanTpFcFrameId" 2147483647;
BA_DEF_DEF_  "CanTpBs" 255;
BA_DEF_DEF_  "CANFD_BRS" "0";
BA_DEF_DEF_  "BusType" "";
BA_DEF_DEF_REL_ "GenSigTimeoutTime" 0;
BA_DEF_DEF_REL_ "GenSigFirstTimeoutTime" 0;
BA_ "NmType" "NmAsr";
BA_ "BusType" "CAN";
BA_ "VersionDay" 24;
BA_ "VersionMonth" 2;
BA_ "VersionNumber" 1;
BA_ "VersionYear" 22;
BA_ "DBName" "CAN02";
BA_ "DiagRole" BU_ VCM 3;
BA_ "DiagnosticClientAddress" BU_ VCM 244;
BA_ "IsOBDrelevant" BU_ VCM 1;
BA_ "TpOwnSystemEcuNumber" BU_ VCM 36;
BA_ "NmAsrNodeIdentifier" BU_ VCM 36;
BA_ "TpOwnSystemEcuNumber" BU_ TCM 24;
BA_ "NmAsrNodeIdentifier" BU_ TCM 24;
BA_ "NmAsrNode" BU_ OBDScanT2 0;
BA_ "IsOBDrelevant" BU_ ECM 1;
BA_ "TpOwnSystemEcuNumber" BU_ ECM 16;
BA_ "NmAsrNodeIdentifier" BU_ ECM 16;
BA_ "VFrameFormat" BO_ 1059 0;
BA_ "GenMsgCycleTime" BO_ 1059 150;
BA_ "GenMsgStartDelayTime" BO_ 1059 95;
BA_ "VFrameFormat" BO_ 1240 0;
BA_ "GenMsgCycleTime" BO_ 1240 250;
BA_ "GenMsgStartDelayTime" BO_ 1240 25;
BA_ "VFrameFormat" BO_ 567 0;
BA_ "GenMsgCycleTime" BO_ 567 20;
BA_ "GenMsgStartDelayTime" BO_ 567 15;
BA_ "VFrameFormat" BO_ 725 0;
BA_ "GenMsgCycleTime" BO_ 725 50;
BA_ "GenMsgStartDelayTime" BO_ 725 10;
BA_ "VFrameFormat" BO_ 298 0;
BA_ "GenMsgCycleTime" BO_ 298 10;
BA_ "VFrameFormat" BO_ 299 0;
BA_ "GenMsgCycleTime" BO_ 299 10;
BA_ "GenMsgStartDelayTime" BO_ 299 5;
BA_ "VFrameFormat" BO_ 569 0;
BA_ "GenMsgCycleTime" BO_ 569 20;
BA_ "GenMsgStartDelayTime" BO_ 569 10;
BA_ "VFrameFormat" BO_ 568 0;
BA_ "GenMsgCycleTime" BO_ 568 20;
BA_ "GenMsgStartDelayTime" BO_ 568 15;
BA_ "VFrameFormat" BO_ 1563 0;
BA_ "GenMsgCycleTime" BO_ 1563 1000;
BA_ "GenMsgStartDelayTime" BO_ 1563 50;
BA_ "GenMsgILSupport" BO_ 1310 0;
BA_ "VFrameFormat" BO_ 1310 0;
BA_ "GenMsgSendType" BO_ 1310 8;
BA_ "CanTpFcFrameId" BO_ 1309 1310;
BA_ "VFrameFormat" BO_ 1309 0;
BA_ "GenMsgSendType" BO_ 1309 8;
BA_ "GenMsgDelayTime" BO_ 1309 500;
BA_ "GenMsgStartDelayTime" BO_ 1309 50;
BA_ "VFrameFormat" BO_ 1308 0;
BA_ "GenMsgCycleTime" BO_ 1308 500;
BA_ "GenMsgStartDelayTime" BO_ 1308 205;
BA_ "VFrameFormat" BO_ 1307 0;
BA_ "GenMsgCycleTime" BO_ 1307 500;
BA_ "GenMsgStartDelayTime" BO_ 1307 280;
BA_ "VFrameFormat" BO_ 1241 0;
BA_ "GenMsgCycleTime" BO_ 1241 250;
BA_ "GenMsgStartDelayTime" BO_ 1241 50;
BA_ "VFrameFormat" BO_ 1185 0;
BA_ "GenMsgCycleTime" BO_ 1185 200;
BA_ "GenMsgStartDelayTime" BO_ 1185 25;
BA_ "VFrameFormat" BO_ 1060 0;
BA_ "GenMsgCycleTime" BO_ 1060 150;
BA_ "GenMsgStartDelayTime" BO_ 1060 50;
BA_ "VFrameFormat" BO_ 932 0;
BA_ "GenMsgCycleTime" BO_ 932 100;
BA_ "GenMsgStartDelayTime" BO_ 932 50;
BA_ "VFrameFormat" BO_ 931 0;
BA_ "GenMsgCycleTime" BO_ 931 100;
BA_ "GenMsgStartDelayTime" BO_ 931 60;
BA_ "VFrameFormat" BO_ 570 0;
BA_ "GenMsgCycleTime" BO_ 570 20;
BA_ "VFrameFormat" BO_ 300 0;
BA_ "GenMsgCycleTime" BO_ 300 10;
BA_ "VFrameFormat" BO_ 558 0;
BA_ "GenMsgCycleTime" BO_ 558 20;
BA_ "GenMsgStartDelayTime" BO_ 558 10;
BA_ "VFrameFormat" BO_ 556 0;
BA_ "GenMsgCycleTime" BO_ 556 20;
BA_ "VFrameFormat" BO_ 554 0;
BA_ "GenMsgCycleTime" BO_ 554 20;
BA_ "GenMsgStartDelayTime" BO_ 554 5;
BA_ "VFrameFormat" BO_ 1246 0;
BA_ "GenMsgCycleTime" BO_ 1246 250;
BA_ "GenMsgStartDelayTime" BO_ 1246 105;
BA_ "VFrameFormat" BO_ 731 0;
BA_ "GenMsgCycleTime" BO_ 731 50;
BA_ "GenMsgStartDelayTime" BO_ 731 5;
BA_ "VFrameFormat" BO_ 742 0;
BA_ "GenMsgCycleTime" BO_ 742 50;
BA_ "GenMsgStartDelayTime" BO_ 742 15;
BA_ "VFrameFormat" BO_ 746 0;
BA_ "GenMsgCycleTime" BO_ 746 50;
BA_ "GenMsgStartDelayTime" BO_ 746 25;
BA_ "VFrameFormat" BO_ 520 0;
BA_ "GenMsgCycleTime" BO_ 520 20;
BA_ "VFrameFormat" BO_ 1306 0;
BA_ "GenMsgCycleTime" BO_ 1306 500;
BA_ "GenMsgStartDelayTime" BO_ 1306 140;
BA_ "VFrameFormat" BO_ 930 0;
BA_ "GenMsgCycleTime" BO_ 930 100;
BA_ "GenMsgStartDelayTime" BO_ 930 40;
BA_ "VFrameFormat" BO_ 929 0;
BA_ "GenMsgCycleTime" BO_ 929 100;
BA_ "GenMsgStartDelayTime" BO_ 929 75;
BA_ "VFrameFormat" BO_ 391 0;
BA_ "GenMsgCycleTime" BO_ 391 20;
BA_ "GenMsgStartDelayTime" BO_ 391 5;
BA_ "VFrameFormat" BO_ 1038 0;
BA_ "GenMsgCycleTime" BO_ 1038 100;
BA_ "GenMsgStartDelayTime" BO_ 1038 15;
BA_ "CANFD_BRS" BO_ 531 1;
BA_ "VFrameFormat" BO_ 531 0;
BA_ "GenMsgSendType" BO_ 531 8;
BA_ "GenMsgDelayTime" BO_ 531 10;
BA_ "DiagConnection" BO_ 2671902706 61976;
BA_ "DiagState" BO_ 2671902706 1;
BA_ "GenMsgILSupport" BO_ 2671902706 0;
BA_ "GenMsgSendType" BO_ 2671902706 8;
BA_ "DiagConnection" BO_ 2671902708 62719;
BA_ "DiagState" BO_ 2671902708 1;
BA_ "GenMsgILSupport" BO_ 2671902708 0;
BA_ "GenMsgSendType" BO_ 2671902708 8;
BA_ "GenMsgILSupport" BO_ 1252 0;
BA_ "VFrameFormat" BO_ 1252 0;
BA_ "GenMsgSendType" BO_ 1252 8;
BA_ "CanTpFcFrameId" BO_ 1251 1252;
BA_ "VFrameFormat" BO_ 1251 0;
BA_ "GenMsgSendType" BO_ 1251 8;
BA_ "GenMsgDelayTime" BO_ 1251 500;
BA_ "GenMsgStartDelayTime" BO_ 1251 50;
BA_ "VFrameFormat" BO_ 1250 0;
BA_ "GenMsgCycleTime" BO_ 1250 500;
BA_ "GenMsgStartDelayTime" BO_ 1250 50;
BA_ "VFrameFormat" BO_ 1046 0;
BA_ "GenMsgCycleTime" BO_ 1046 100;
BA_ "GenMsgStartDelayTime" BO_ 1046 50;
BA_ "GenSigCycleTime" SG_ 1059 BatteryCurrent 100;
BA_ "GenSigCycleTimeActive" SG_ 1059 BatteryCurrent 100;
BA_ "GenSigStartValue" SG_ 1059 BatteryCurrent 65535;
BA_ "GenSigCycleTime" SG_ 1240 FrontAxle2Load 100;
BA_ "GenSigCycleTimeActive" SG_ 1240 FrontAxle2Load 100;
BA_ "GenSigStartValue" SG_ 1240 FrontAxle2Load 65535;
BA_ "GenSigCycleTime" SG_ 1240 FrontAxle1Load 100;
BA_ "GenSigCycleTimeActive" SG_ 1240 FrontAxle1Load 100;
BA_ "GenSigStartValue" SG_ 1240 FrontAxle1Load 65535;
BA_ "GenSigCycleTime" SG_ 567 DriveModeSwitchStat_Rqst 100;
BA_ "GenSigCycleTimeActive" SG_ 567 DriveModeSwitchStat_Rqst 100;
BA_ "GenSigStartValue" SG_ 567 DriveModeSwitchStat_Rqst 3;
BA_ "GenSigCycleTime" SG_ 567 GearLeverPosition2_SqC 100;
BA_ "GenSigCycleTimeActive" SG_ 567 GearLeverPosition2_SqC 100;
BA_ "GenSigCycleTime" SG_ 567 UpDownShiftRqst_Rqst 100;
BA_ "GenSigCycleTimeActive" SG_ 567 UpDownShiftRqst_Rqst 100;
BA_ "GenSigStartValue" SG_ 567 UpDownShiftRqst_Rqst 15;
BA_ "GenSigCycleTime" SG_ 567 DriveModeSwitchStat_CRC 100;
BA_ "GenSigCycleTimeActive" SG_ 567 DriveModeSwitchStat_CRC 100;
BA_ "E2EDataId" SG_ 567 DriveModeSwitchStat_CRC 11;
BA_ "E2EDataLength" SG_ 567 DriveModeSwitchStat_CRC 16;
BA_ "E2EProfile" SG_ 567 DriveModeSwitchStat_CRC "P01";
BA_ "GenSigCycleTime" SG_ 567 UpDownShiftRqst_SqC 100;
BA_ "GenSigCycleTimeActive" SG_ 567 UpDownShiftRqst_SqC 100;
BA_ "GenSigCycleTime" SG_ 567 UpDownShiftRqst_CRC 100;
BA_ "GenSigCycleTimeActive" SG_ 567 UpDownShiftRqst_CRC 100;
BA_ "E2EDataId" SG_ 567 UpDownShiftRqst_CRC 14;
BA_ "E2EDataLength" SG_ 567 UpDownShiftRqst_CRC 16;
BA_ "E2EProfile" SG_ 567 UpDownShiftRqst_CRC "P01";
BA_ "GenSigCycleTime" SG_ 567 DriveModeSwitchStat_SqC 100;
BA_ "GenSigCycleTimeActive" SG_ 567 DriveModeSwitchStat_SqC 100;
BA_ "GenSigCycleTime" SG_ 567 GearLeverPosition2_Rqst 100;
BA_ "GenSigCycleTimeActive" SG_ 567 GearLeverPosition2_Rqst 100;
BA_ "GenSigStartValue" SG_ 567 GearLeverPosition2_Rqst 15;
BA_ "GenSigCycleTime" SG_ 567 GearLeverPosition2_CRC 100;
BA_ "GenSigCycleTimeActive" SG_ 567 GearLeverPosition2_CRC 100;
BA_ "E2EDataId" SG_ 567 GearLeverPosition2_CRC 13;
BA_ "E2EDataLength" SG_ 567 GearLeverPosition2_CRC 16;
BA_ "E2EProfile" SG_ 567 GearLeverPosition2_CRC "P01";
BA_ "GenSigCycleTime" SG_ 725 ESCReqEMS_CtrlTrimStat 100;
BA_ "GenSigCycleTimeActive" SG_ 725 ESCReqEMS_CtrlTrimStat 100;
BA_ "GenSigStartValue" SG_ 725 ESCReqEMS_CtrlTrimStat 7;
BA_ "GenSigMaxLatency" SG_ 725 ESCReqEMS_CtrlTrimStat 50;
BA_ "SeToolAncestorID_SIGNAL" SG_ 725 ESCReqEMS_CtrlTrimStat "x0000001D042A710D";
BA_ "SeToolItemID_SIGNAL" SG_ 725 ESCReqEMS_CtrlTrimStat "x0000001D042A710D";
BA_ "SeToolName_SIGNAL" SG_ 725 ESCReqEMS_CtrlTrimStat "CtrlTrimStat";
BA_ "SeToolOwnerSigGroupID_SIGNAL" SG_ 725 ESCReqEMS_CtrlTrimStat "x0000001D043D5DDC";
BA_ "SeToolOwnerSigGroup_SIGNAL" SG_ 725 ESCReqEMS_CtrlTrimStat "ESCReqEMS";
BA_ "SeToolVersion_SIGNAL" SG_ 725 ESCReqEMS_CtrlTrimStat "1";
BA_ "GenSigCycleTime" SG_ 725 ESCReqEMS_CtrlTrimValue 100;
BA_ "GenSigCycleTimeActive" SG_ 725 ESCReqEMS_CtrlTrimValue 100;
BA_ "GenSigStartValue" SG_ 725 ESCReqEMS_CtrlTrimValue 255;
BA_ "GenSigMaxLatency" SG_ 725 ESCReqEMS_CtrlTrimValue 50;
BA_ "SeToolAncestorID_SIGNAL" SG_ 725 ESCReqEMS_CtrlTrimValue "x0000001D042A7114";
BA_ "SeToolItemID_SIGNAL" SG_ 725 ESCReqEMS_CtrlTrimValue "x0000001D042A7114";
BA_ "SeToolName_SIGNAL" SG_ 725 ESCReqEMS_CtrlTrimValue "CtrlTrimValue";
BA_ "SeToolOwnerSigGroupID_SIGNAL" SG_ 725 ESCReqEMS_CtrlTrimValue "x0000001D043D5DDC";
BA_ "SeToolOwnerSigGroup_SIGNAL" SG_ 725 ESCReqEMS_CtrlTrimValue "ESCReqEMS";
BA_ "SeToolVersion_SIGNAL" SG_ 725 ESCReqEMS_CtrlTrimValue "1";
BA_ "GenSigCycleTime" SG_ 725 StoreIdleValue 100;
BA_ "GenSigCycleTimeActive" SG_ 725 StoreIdleValue 100;
BA_ "GenSigStartValue" SG_ 725 StoreIdleValue 3;
BA_ "GenSigCycleTime" SG_ 725 ESCReqEMS_CtrlTrimMode 100;
BA_ "GenSigCycleTimeActive" SG_ 725 ESCReqEMS_CtrlTrimMode 100;
BA_ "GenSigStartValue" SG_ 725 ESCReqEMS_CtrlTrimMode 15;
BA_ "GenSigMaxLatency" SG_ 725 ESCReqEMS_CtrlTrimMode 50;
BA_ "SeToolAncestorID_SIGNAL" SG_ 725 ESCReqEMS_CtrlTrimMode "x0000001D042A710F";
BA_ "SeToolItemID_SIGNAL" SG_ 725 ESCReqEMS_CtrlTrimMode "x0000001D042A710F";
BA_ "SeToolName_SIGNAL" SG_ 725 ESCReqEMS_CtrlTrimMode "CtrlTrimMode";
BA_ "SeToolOwnerSigGroupID_SIGNAL" SG_ 725 ESCReqEMS_CtrlTrimMode "x0000001D043D5DDC";
BA_ "SeToolOwnerSigGroup_SIGNAL" SG_ 725 ESCReqEMS_CtrlTrimMode "ESCReqEMS";
BA_ "SeToolVersion_SIGNAL" SG_ 725 ESCReqEMS_CtrlTrimMode "1";
BA_ "GenSigCycleTime" SG_ 725 TrailerConnected 100;
BA_ "GenSigCycleTimeActive" SG_ 725 TrailerConnected 100;
BA_ "GenSigStartValue" SG_ 725 TrailerConnected 3;
BA_ "GenSigMaxLatency" SG_ 725 TrailerConnected 50;
BA_ "GenSigCycleTime" SG_ 725 ESCReqEMS_CtrlTrimReq 100;
BA_ "GenSigCycleTimeActive" SG_ 725 ESCReqEMS_CtrlTrimReq 100;
BA_ "GenSigStartValue" SG_ 725 ESCReqEMS_CtrlTrimReq 7;
BA_ "GenSigMaxLatency" SG_ 725 ESCReqEMS_CtrlTrimReq 50;
BA_ "SeToolAncestorID_SIGNAL" SG_ 725 ESCReqEMS_CtrlTrimReq "x0000001D042A710B";
BA_ "SeToolItemID_SIGNAL" SG_ 725 ESCReqEMS_CtrlTrimReq "x0000001D042A710B";
BA_ "SeToolName_SIGNAL" SG_ 725 ESCReqEMS_CtrlTrimReq "CtrlTrimReq";
BA_ "SeToolOwnerSigGroupID_SIGNAL" SG_ 725 ESCReqEMS_CtrlTrimReq "x0000001D043D5DDC";
BA_ "SeToolOwnerSigGroup_SIGNAL" SG_ 725 ESCReqEMS_CtrlTrimReq "ESCReqEMS";
BA_ "SeToolVersion_SIGNAL" SG_ 725 ESCReqEMS_CtrlTrimReq "1";
BA_ "GenSigCycleTime" SG_ 298 ReqTSC_Tq 100;
BA_ "GenSigCycleTimeActive" SG_ 298 ReqTSC_Tq 100;
BA_ "GenSigStartValue" SG_ 298 ReqTSC_Tq 65535;
BA_ "GenSigCycleTime" SG_ 298 ReqTSC_CtrlMode 100;
BA_ "GenSigCycleTimeActive" SG_ 298 ReqTSC_CtrlMode 100;
BA_ "GenSigCycleTime" SG_ 298 ReqTSC_CRC 100;
BA_ "GenSigCycleTimeActive" SG_ 298 ReqTSC_CRC 100;
BA_ "GenSigStartValue" SG_ 298 ReqTSC_CRC 255;
BA_ "E2EDataId" SG_ 298 ReqTSC_CRC 156;
BA_ "E2EDataLength" SG_ 298 ReqTSC_CRC 48;
BA_ "E2EProfile" SG_ 298 ReqTSC_CRC "P01";
BA_ "GenSigCycleTime" SG_ 298 ReqTSC_SqC 100;
BA_ "GenSigCycleTimeActive" SG_ 298 ReqTSC_SqC 100;
BA_ "GenSigStartValue" SG_ 298 ReqTSC_SqC 14;
BA_ "GenSigCycleTime" SG_ 298 ReqTSC_Spd 100;
BA_ "GenSigCycleTimeActive" SG_ 298 ReqTSC_Spd 100;
BA_ "GenSigStartValue" SG_ 298 ReqTSC_Spd 65535;
BA_ "GenSigCycleTime" SG_ 299 AccPedal_CRC 100;
BA_ "GenSigCycleTimeActive" SG_ 299 AccPedal_CRC 100;
BA_ "GenSigStartValue" SG_ 299 AccPedal_CRC 255;
BA_ "GenSigMaxLatency" SG_ 299 AccPedal_CRC 10;
BA_ "E2EDataId" SG_ 299 AccPedal_CRC 166;
BA_ "E2EDataLength" SG_ 299 AccPedal_CRC 24;
BA_ "E2EProfile" SG_ 299 AccPedal_CRC "P01";
BA_ "GenSigCycleTime" SG_ 299 AccPedal_SqC 100;
BA_ "GenSigCycleTimeActive" SG_ 299 AccPedal_SqC 100;
BA_ "GenSigStartValue" SG_ 299 AccPedal_SqC 14;
BA_ "GenSigMaxLatency" SG_ 299 AccPedal_SqC 10;
BA_ "GenSigCycleTime" SG_ 299 AcceleratorPedalPositionVendor 100;
BA_ "GenSigCycleTimeActive" SG_ 299 AcceleratorPedalPositionVendor 100;
BA_ "GenSigStartValue" SG_ 299 AcceleratorPedalPositionVendor 255;
BA_ "GenSigMaxLatency" SG_ 299 AcceleratorPedalPositionVendor 10;
BA_ "GenSigCycleTime" SG_ 299 AccPedal_Qlty 100;
BA_ "GenSigCycleTimeActive" SG_ 299 AccPedal_Qlty 100;
BA_ "GenSigStartValue" SG_ 299 AccPedal_Qlty 3;
BA_ "GenSigMaxLatency" SG_ 299 AccPedal_Qlty 10;
BA_ "GenSigCycleTime" SG_ 299 AccPedal_Pos 100;
BA_ "GenSigCycleTimeActive" SG_ 299 AccPedal_Pos 100;
BA_ "GenSigStartValue" SG_ 299 AccPedal_Pos 255;
BA_ "GenSigMaxLatency" SG_ 299 AccPedal_Pos 10;
BA_ "GenSigCycleTime" SG_ 569 ReverseGearEngaged 100;
BA_ "GenSigCycleTimeActive" SG_ 569 ReverseGearEngaged 100;
BA_ "GenSigStartValue" SG_ 569 ReverseGearEngaged 3;
BA_ "GenSigMaxLatency" SG_ 569 ReverseGearEngaged 20;
BA_ "GenSigCycleTime" SG_ 569 SecuredNeutralPosition 100;
BA_ "GenSigCycleTimeActive" SG_ 569 SecuredNeutralPosition 100;
BA_ "GenSigStartValue" SG_ 569 SecuredNeutralPosition 3;
BA_ "GenSigMaxLatency" SG_ 569 SecuredNeutralPosition 20;
BA_ "GenSigCycleTime" SG_ 569 TransmissionNeutralSwitch 100;
BA_ "GenSigCycleTimeActive" SG_ 569 TransmissionNeutralSwitch 100;
BA_ "GenSigStartValue" SG_ 569 TransmissionNeutralSwitch 3;
BA_ "GenSigMaxLatency" SG_ 569 TransmissionNeutralSwitch 20;
BA_ "GenSigCycleTime" SG_ 569 LevelControlInformation 100;
BA_ "GenSigCycleTimeActive" SG_ 569 LevelControlInformation 100;
BA_ "GenSigStartValue" SG_ 569 LevelControlInformation 15;
BA_ "GenSigMaxLatency" SG_ 569 LevelControlInformation 20;
BA_ "GenSigCycleTime" SG_ 569 TransmLowRangeSenseSwitch 100;
BA_ "GenSigCycleTimeActive" SG_ 569 TransmLowRangeSenseSwitch 100;
BA_ "GenSigStartValue" SG_ 569 TransmLowRangeSenseSwitch 3;
BA_ "GenSigMaxLatency" SG_ 569 TransmLowRangeSenseSwitch 20;
BA_ "GenSigCycleTime" SG_ 568 EngSystPwrDwn_Rqst 100;
BA_ "GenSigCycleTimeActive" SG_ 568 EngSystPwrDwn_Rqst 100;
BA_ "GenSigStartValue" SG_ 568 EngSystPwrDwn_Rqst 3;
BA_ "GenSigMaxLatency" SG_ 568 EngSystPwrDwn_Rqst 20;
BA_ "GenSigCycleTime" SG_ 568 TrnsmSystPwrDwn_SqC 100;
BA_ "GenSigCycleTimeActive" SG_ 568 TrnsmSystPwrDwn_SqC 100;
BA_ "GenSigStartValue" SG_ 568 TrnsmSystPwrDwn_SqC 14;
BA_ "GenSigMaxLatency" SG_ 568 TrnsmSystPwrDwn_SqC 20;
BA_ "GenSigCycleTime" SG_ 568 EngSystPwrDwn_CRC 100;
BA_ "GenSigCycleTimeActive" SG_ 568 EngSystPwrDwn_CRC 100;
BA_ "GenSigStartValue" SG_ 568 EngSystPwrDwn_CRC 255;
BA_ "GenSigMaxLatency" SG_ 568 EngSystPwrDwn_CRC 20;
BA_ "E2EDataId" SG_ 568 EngSystPwrDwn_CRC 173;
BA_ "E2EDataLength" SG_ 568 EngSystPwrDwn_CRC 16;
BA_ "E2EProfile" SG_ 568 EngSystPwrDwn_CRC "P01";
BA_ "GenSigCycleTime" SG_ 568 EngCrnk_Rqst 100;
BA_ "GenSigCycleTimeActive" SG_ 568 EngCrnk_Rqst 100;
BA_ "GenSigStartValue" SG_ 568 EngCrnk_Rqst 3;
BA_ "GenSigMaxLatency" SG_ 568 EngCrnk_Rqst 20;
BA_ "GenSigCycleTime" SG_ 568 TrnsmSystPwrDwn_Rqst 100;
BA_ "GenSigCycleTimeActive" SG_ 568 TrnsmSystPwrDwn_Rqst 100;
BA_ "GenSigStartValue" SG_ 568 TrnsmSystPwrDwn_Rqst 3;
BA_ "GenSigMaxLatency" SG_ 568 TrnsmSystPwrDwn_Rqst 20;
BA_ "GenSigCycleTime" SG_ 568 EcnmyPwrSwt_Sts 100;
BA_ "GenSigCycleTimeActive" SG_ 568 EcnmyPwrSwt_Sts 100;
BA_ "GenSigStartValue" SG_ 568 EcnmyPwrSwt_Sts 3;
BA_ "GenSigMaxLatency" SG_ 568 EcnmyPwrSwt_Sts 20;
BA_ "GenSigCycleTime" SG_ 568 EngCrnk_SqC 100;
BA_ "GenSigCycleTimeActive" SG_ 568 EngCrnk_SqC 100;
BA_ "GenSigStartValue" SG_ 568 EngCrnk_SqC 14;
BA_ "GenSigMaxLatency" SG_ 568 EngCrnk_SqC 20;
BA_ "GenSigCycleTime" SG_ 568 EcnmyPwrSwt_CRC 100;
BA_ "GenSigCycleTimeActive" SG_ 568 EcnmyPwrSwt_CRC 100;
BA_ "GenSigStartValue" SG_ 568 EcnmyPwrSwt_CRC 255;
BA_ "GenSigMaxLatency" SG_ 568 EcnmyPwrSwt_CRC 20;
BA_ "E2EDataId" SG_ 568 EcnmyPwrSwt_CRC 171;
BA_ "E2EDataLength" SG_ 568 EcnmyPwrSwt_CRC 16;
BA_ "E2EProfile" SG_ 568 EcnmyPwrSwt_CRC "P01";
BA_ "GenSigCycleTime" SG_ 568 EngCrnk_CRC 100;
BA_ "GenSigCycleTimeActive" SG_ 568 EngCrnk_CRC 100;
BA_ "GenSigStartValue" SG_ 568 EngCrnk_CRC 255;
BA_ "GenSigMaxLatency" SG_ 568 EngCrnk_CRC 20;
BA_ "E2EDataId" SG_ 568 EngCrnk_CRC 174;
BA_ "E2EDataLength" SG_ 568 EngCrnk_CRC 16;
BA_ "E2EProfile" SG_ 568 EngCrnk_CRC "P01";
BA_ "GenSigCycleTime" SG_ 568 EcnmyPwrSwt_SqC 100;
BA_ "GenSigCycleTimeActive" SG_ 568 EcnmyPwrSwt_SqC 100;
BA_ "GenSigStartValue" SG_ 568 EcnmyPwrSwt_SqC 14;
BA_ "GenSigMaxLatency" SG_ 568 EcnmyPwrSwt_SqC 20;
BA_ "GenSigCycleTime" SG_ 568 EngSystPwrDwn_SqC 100;
BA_ "GenSigCycleTimeActive" SG_ 568 EngSystPwrDwn_SqC 100;
BA_ "GenSigStartValue" SG_ 568 EngSystPwrDwn_SqC 14;
BA_ "GenSigMaxLatency" SG_ 568 EngSystPwrDwn_SqC 20;
BA_ "GenSigCycleTime" SG_ 568 TrnsmSystPwrDwn_CRC 100;
BA_ "GenSigCycleTimeActive" SG_ 568 TrnsmSystPwrDwn_CRC 100;
BA_ "GenSigStartValue" SG_ 568 TrnsmSystPwrDwn_CRC 255;
BA_ "GenSigMaxLatency" SG_ 568 TrnsmSystPwrDwn_CRC 20;
BA_ "E2EDataId" SG_ 568 TrnsmSystPwrDwn_CRC 172;
BA_ "E2EDataLength" SG_ 568 TrnsmSystPwrDwn_CRC 16;
BA_ "E2EProfile" SG_ 568 TrnsmSystPwrDwn_CRC "P01";
BA_ "GenSigCycleTime" SG_ 1563 MIStatusExtVMCU 100;
BA_ "GenSigCycleTimeActive" SG_ 1563 MIStatusExtVMCU 100;
BA_ "GenSigStartValue" SG_ 1563 MIStatusExtVMCU 3;
BA_ "GenSigMaxLatency" SG_ 1563 MIStatusExtVMCU 1000;
BA_ "GenSigCycleTime" SG_ 1563 MIStatusVMCU 100;
BA_ "GenSigCycleTimeActive" SG_ 1563 MIStatusVMCU 100;
BA_ "GenSigStartValue" SG_ 1563 MIStatusVMCU 3;
BA_ "GenSigMaxLatency" SG_ 1563 MIStatusVMCU 1000;
BA_ "GenSigCycleTime" SG_ 1563 MIDistinctWarningExtVMCU 100;
BA_ "GenSigCycleTimeActive" SG_ 1563 MIDistinctWarningExtVMCU 100;
BA_ "GenSigStartValue" SG_ 1563 MIDistinctWarningExtVMCU 15;
BA_ "GenSigMaxLatency" SG_ 1563 MIDistinctWarningExtVMCU 1000;
BA_ "GenSigCycleTime" SG_ 1563 MIDistinctWarningVMCU 100;
BA_ "GenSigCycleTimeActive" SG_ 1563 MIDistinctWarningVMCU 100;
BA_ "GenSigStartValue" SG_ 1563 MIDistinctWarningVMCU 3;
BA_ "GenSigMaxLatency" SG_ 1563 MIDistinctWarningVMCU 1000;
BA_ "GenSigSendType" SG_ 1310 VCM_P24_C02_FCS 7;
BA_ "GenSigSendType" SG_ 1309 HillDataPkgTGW 1;
BA_ "GenSigMaxLatency" SG_ 1309 HillDataPkgTGW 500;
BA_ "GenSigCycleTime" SG_ 1308 HillDataCtrlTGW_AckCnt 100;
BA_ "GenSigCycleTimeActive" SG_ 1308 HillDataCtrlTGW_AckCnt 100;
BA_ "GenSigStartValue" SG_ 1308 HillDataCtrlTGW_AckCnt 3;
BA_ "GenSigMaxLatency" SG_ 1308 HillDataCtrlTGW_AckCnt 500;
BA_ "GenSigCycleTime" SG_ 1308 ExhManifAirInjectionInhibit 100;
BA_ "GenSigCycleTimeActive" SG_ 1308 ExhManifAirInjectionInhibit 100;
BA_ "GenSigStartValue" SG_ 1308 ExhManifAirInjectionInhibit 3;
BA_ "GenSigMaxLatency" SG_ 1308 ExhManifAirInjectionInhibit 500;
BA_ "GenSigCycleTime" SG_ 1308 OBDUTCTime_Hours 100;
BA_ "GenSigCycleTimeActive" SG_ 1308 OBDUTCTime_Hours 100;
BA_ "GenSigStartValue" SG_ 1308 OBDUTCTime_Hours 255;
BA_ "GenSigMaxLatency" SG_ 1308 OBDUTCTime_Hours 500;
BA_ "GenSigCycleTime" SG_ 1308 HillDataCtrlTGW_State 100;
BA_ "GenSigCycleTimeActive" SG_ 1308 HillDataCtrlTGW_State 100;
BA_ "GenSigStartValue" SG_ 1308 HillDataCtrlTGW_State 7;
BA_ "GenSigMaxLatency" SG_ 1308 HillDataCtrlTGW_State 500;
BA_ "GenSigCycleTime" SG_ 1308 OBDUTCTime_Day 100;
BA_ "GenSigCycleTimeActive" SG_ 1308 OBDUTCTime_Day 100;
BA_ "GenSigStartValue" SG_ 1308 OBDUTCTime_Day 255;
BA_ "GenSigMaxLatency" SG_ 1308 OBDUTCTime_Day 500;
BA_ "GenSigCycleTime" SG_ 1308 OBDUTCTime_Year 100;
BA_ "GenSigCycleTimeActive" SG_ 1308 OBDUTCTime_Year 100;
BA_ "GenSigStartValue" SG_ 1308 OBDUTCTime_Year 255;
BA_ "GenSigMaxLatency" SG_ 1308 OBDUTCTime_Year 500;
BA_ "GenSigCycleTime" SG_ 1308 OBDUTCTime_Month 100;
BA_ "GenSigCycleTimeActive" SG_ 1308 OBDUTCTime_Month 100;
BA_ "GenSigStartValue" SG_ 1308 OBDUTCTime_Month 255;
BA_ "GenSigMaxLatency" SG_ 1308 OBDUTCTime_Month 500;
BA_ "GenSigCycleTime" SG_ 1308 DPF_ManualRegenerateTimeReq 100;
BA_ "GenSigCycleTimeActive" SG_ 1308 DPF_ManualRegenerateTimeReq 100;
BA_ "GenSigStartValue" SG_ 1308 DPF_ManualRegenerateTimeReq 3;
BA_ "GenSigMaxLatency" SG_ 1308 DPF_ManualRegenerateTimeReq 500;
BA_ "GenSigCycleTime" SG_ 1308 OBDUTCTime_Seconds 100;
BA_ "GenSigCycleTimeActive" SG_ 1308 OBDUTCTime_Seconds 100;
BA_ "GenSigStartValue" SG_ 1308 OBDUTCTime_Seconds 255;
BA_ "GenSigMaxLatency" SG_ 1308 OBDUTCTime_Seconds 500;
BA_ "GenSigCycleTime" SG_ 1308 OBDUTCTime_Minutes 100;
BA_ "GenSigCycleTimeActive" SG_ 1308 OBDUTCTime_Minutes 100;
BA_ "GenSigStartValue" SG_ 1308 OBDUTCTime_Minutes 255;
BA_ "GenSigMaxLatency" SG_ 1308 OBDUTCTime_Minutes 500;
BA_ "GenSigCycleTime" SG_ 1307 OBD_Timestamp 100;
BA_ "GenSigCycleTimeActive" SG_ 1307 OBD_Timestamp 100;
BA_ "GenSigStartValue" SG_ 1307 OBD_Timestamp 4294967295;
BA_ "GenSigMaxLatency" SG_ 1307 OBD_Timestamp 500;
BA_ "GenSigCycleTime" SG_ 1241 PwtCCUnderSpeedRequest 100;
BA_ "GenSigCycleTimeActive" SG_ 1241 PwtCCUnderSpeedRequest 100;
BA_ "GenSigStartValue" SG_ 1241 PwtCCUnderSpeedRequest 65535;
BA_ "GenSigMaxLatency" SG_ 1241 PwtCCUnderSpeedRequest 250;
BA_ "GenSigCycleTime" SG_ 1241 StarterMotorReset_rqst 100;
BA_ "GenSigCycleTimeActive" SG_ 1241 StarterMotorReset_rqst 100;
BA_ "GenSigStartValue" SG_ 1241 StarterMotorReset_rqst 3;
BA_ "GenSigMaxLatency" SG_ 1241 StarterMotorReset_rqst 250;
BA_ "GenSigCycleTime" SG_ 1185 SavedHeightControlMode 100;
BA_ "GenSigCycleTimeActive" SG_ 1185 SavedHeightControlMode 100;
BA_ "GenSigStartValue" SG_ 1185 SavedHeightControlMode 3;
BA_ "GenSigMaxLatency" SG_ 1185 SavedHeightControlMode 200;
BA_ "GenSigCycleTime" SG_ 1185 SpeedAdaptEnableRqst_SpeedLimit 100;
BA_ "GenSigCycleTimeActive" SG_ 1185 SpeedAdaptEnableRqst_SpeedLimit 100;
BA_ "GenSigStartValue" SG_ 1185 SpeedAdaptEnableRqst_SpeedLimit 3;
BA_ "GenSigMaxLatency" SG_ 1185 SpeedAdaptEnableRqst_SpeedLimit 200;
BA_ "GenSigCycleTime" SG_ 1185 SpeedAdaptEnableRqst_Curve 100;
BA_ "GenSigCycleTimeActive" SG_ 1185 SpeedAdaptEnableRqst_Curve 100;
BA_ "GenSigStartValue" SG_ 1185 SpeedAdaptEnableRqst_Curve 3;
BA_ "GenSigMaxLatency" SG_ 1185 SpeedAdaptEnableRqst_Curve 200;
BA_ "GenSigCycleTime" SG_ 1185 SpeedAdaptEnableRqst_SlowTraffic 100;
BA_ "GenSigCycleTimeActive" SG_ 1185 SpeedAdaptEnableRqst_SlowTraffic 100;
BA_ "GenSigStartValue" SG_ 1185 SpeedAdaptEnableRqst_SlowTraffic 3;
BA_ "GenSigMaxLatency" SG_ 1185 SpeedAdaptEnableRqst_SlowTraffic 200;
BA_ "GenSigCycleTime" SG_ 1060 EngOvrrideCtrlStat_FireTruckMode 100;
BA_ "GenSigCycleTimeActive" SG_ 1060 EngOvrrideCtrlStat_FireTruckMode 100;
BA_ "GenSigStartValue" SG_ 1060 EngOvrrideCtrlStat_FireTruckMode 3;
BA_ "GenSigMaxLatency" SG_ 1060 EngOvrrideCtrlStat_FireTruckMode 150;
BA_ "GenSigCycleTime" SG_ 1060 EngOvrrideCtrlStat_ProtOvrrMode 100;
BA_ "GenSigCycleTimeActive" SG_ 1060 EngOvrrideCtrlStat_ProtOvrrMode 100;
BA_ "GenSigStartValue" SG_ 1060 EngOvrrideCtrlStat_ProtOvrrMode 3;
BA_ "GenSigMaxLatency" SG_ 1060 EngOvrrideCtrlStat_ProtOvrrMode 150;
BA_ "GenSigCycleTime" SG_ 1060 EngOvrrideCtrlStat_StartOvrrMode 100;
BA_ "GenSigCycleTimeActive" SG_ 1060 EngOvrrideCtrlStat_StartOvrrMode 100;
BA_ "GenSigStartValue" SG_ 1060 EngOvrrideCtrlStat_StartOvrrMode 3;
BA_ "GenSigMaxLatency" SG_ 1060 EngOvrrideCtrlStat_StartOvrrMode 150;
BA_ "GenSigCycleTime" SG_ 1060 EngineAirShutOffCommandStatus 100;
BA_ "GenSigCycleTimeActive" SG_ 1060 EngineAirShutOffCommandStatus 100;
BA_ "GenSigStartValue" SG_ 1060 EngineAirShutOffCommandStatus 3;
BA_ "GenSigMaxLatency" SG_ 1060 EngineAirShutOffCommandStatus 150;
BA_ "GenSigCycleTime" SG_ 932 ParkBrake_OBDState 100;
BA_ "GenSigCycleTimeActive" SG_ 932 ParkBrake_OBDState 100;
BA_ "GenSigStartValue" SG_ 932 ParkBrake_OBDState 3;
BA_ "GenSigMaxLatency" SG_ 932 ParkBrake_OBDState 100;
BA_ "GenSigCycleTime" SG_ 932 AltParallelOperation 100;
BA_ "GenSigCycleTimeActive" SG_ 932 AltParallelOperation 100;
BA_ "GenSigStartValue" SG_ 932 AltParallelOperation 3;
BA_ "GenSigMaxLatency" SG_ 932 AltParallelOperation 100;
BA_ "GenSigCycleTime" SG_ 932 AltLR_cut_offSpeed 100;
BA_ "GenSigCycleTimeActive" SG_ 932 AltLR_cut_offSpeed 100;
BA_ "GenSigStartValue" SG_ 932 AltLR_cut_offSpeed 31;
BA_ "GenSigMaxLatency" SG_ 932 AltLR_cut_offSpeed 100;
BA_ "GenSigCycleTime" SG_ 932 AltVoltageSetValue 100;
BA_ "GenSigCycleTimeActive" SG_ 932 AltVoltageSetValue 100;
BA_ "GenSigStartValue" SG_ 932 AltVoltageSetValue 255;
BA_ "GenSigMaxLatency" SG_ 932 AltVoltageSetValue 100;
BA_ "GenSigCycleTime" SG_ 932 AltExitationCurrentLimit 100;
BA_ "GenSigCycleTimeActive" SG_ 932 AltExitationCurrentLimit 100;
BA_ "GenSigStartValue" SG_ 932 AltExitationCurrentLimit 255;
BA_ "GenSigMaxLatency" SG_ 932 AltExitationCurrentLimit 100;
BA_ "GenSigCycleTime" SG_ 932 CruiseControlStates 100;
BA_ "GenSigCycleTimeActive" SG_ 932 CruiseControlStates 100;
BA_ "GenSigStartValue" SG_ 932 CruiseControlStates 7;
BA_ "GenSigMaxLatency" SG_ 932 CruiseControlStates 100;
BA_ "GenSigCycleTime" SG_ 932 AltDataSelectionWordRx 100;
BA_ "GenSigCycleTimeActive" SG_ 932 AltDataSelectionWordRx 100;
BA_ "GenSigStartValue" SG_ 932 AltDataSelectionWordRx 15;
BA_ "GenSigMaxLatency" SG_ 932 AltDataSelectionWordRx 100;
BA_ "GenSigCycleTime" SG_ 932 ClutchSwitch 100;
BA_ "GenSigCycleTimeActive" SG_ 932 ClutchSwitch 100;
BA_ "GenSigStartValue" SG_ 932 ClutchSwitch 3;
BA_ "GenSigMaxLatency" SG_ 932 ClutchSwitch 100;
BA_ "GenSigCycleTime" SG_ 932 AltLR_RampTime 100;
BA_ "GenSigCycleTimeActive" SG_ 932 AltLR_RampTime 100;
BA_ "GenSigStartValue" SG_ 932 AltLR_RampTime 31;
BA_ "GenSigMaxLatency" SG_ 932 AltLR_RampTime 100;
BA_ "GenSigCycleTime" SG_ 932 CACCStatus 100;
BA_ "GenSigCycleTimeActive" SG_ 932 CACCStatus 100;
BA_ "GenSigStartValue" SG_ 932 CACCStatus 7;
BA_ "GenSigMaxLatency" SG_ 932 CACCStatus 100;
BA_ "GenSigCycleTime" SG_ 931 CCBTrgtSpd_CRC 100;
BA_ "GenSigCycleTimeActive" SG_ 931 CCBTrgtSpd_CRC 100;
BA_ "GenSigStartValue" SG_ 931 CCBTrgtSpd_CRC 255;
BA_ "GenSigMaxLatency" SG_ 931 CCBTrgtSpd_CRC 100;
BA_ "E2EDataId" SG_ 931 CCBTrgtSpd_CRC 168;
BA_ "E2EDataLength" SG_ 931 CCBTrgtSpd_CRC 32;
BA_ "E2EProfile" SG_ 931 CCBTrgtSpd_CRC "P01";
BA_ "GenSigCycleTime" SG_ 931 CCTrgtSpd_SqC 100;
BA_ "GenSigCycleTimeActive" SG_ 931 CCTrgtSpd_SqC 100;
BA_ "GenSigStartValue" SG_ 931 CCTrgtSpd_SqC 14;
BA_ "GenSigMaxLatency" SG_ 931 CCTrgtSpd_SqC 100;
BA_ "GenSigCycleTime" SG_ 931 CCTrgtSpd_Rqst 100;
BA_ "GenSigCycleTimeActive" SG_ 931 CCTrgtSpd_Rqst 100;
BA_ "GenSigStartValue" SG_ 931 CCTrgtSpd_Rqst 65535;
BA_ "GenSigMaxLatency" SG_ 931 CCTrgtSpd_Rqst 100;
BA_ "GenSigCycleTime" SG_ 931 CCBTrgtSpd_SqC 100;
BA_ "GenSigCycleTimeActive" SG_ 931 CCBTrgtSpd_SqC 100;
BA_ "GenSigStartValue" SG_ 931 CCBTrgtSpd_SqC 14;
BA_ "GenSigMaxLatency" SG_ 931 CCBTrgtSpd_SqC 100;
BA_ "GenSigCycleTime" SG_ 931 CCTrgtSpd_CRC 100;
BA_ "GenSigCycleTimeActive" SG_ 931 CCTrgtSpd_CRC 100;
BA_ "GenSigStartValue" SG_ 931 CCTrgtSpd_CRC 255;
BA_ "GenSigMaxLatency" SG_ 931 CCTrgtSpd_CRC 100;
BA_ "E2EDataId" SG_ 931 CCTrgtSpd_CRC 167;
BA_ "E2EDataLength" SG_ 931 CCTrgtSpd_CRC 32;
BA_ "E2EProfile" SG_ 931 CCTrgtSpd_CRC "P01";
BA_ "GenSigCycleTime" SG_ 931 CCBTrgtSpd_Rqst 100;
BA_ "GenSigCycleTimeActive" SG_ 931 CCBTrgtSpd_Rqst 100;
BA_ "GenSigStartValue" SG_ 931 CCBTrgtSpd_Rqst 65535;
BA_ "GenSigMaxLatency" SG_ 931 CCBTrgtSpd_Rqst 100;
BA_ "GenSigCycleTime" SG_ 570 FrontAxleInBumperRange 100;
BA_ "GenSigCycleTimeActive" SG_ 570 FrontAxleInBumperRange 100;
BA_ "GenSigStartValue" SG_ 570 FrontAxleInBumperRange 3;
BA_ "GenSigMaxLatency" SG_ 570 FrontAxleInBumperRange 50;
BA_ "GenSigCycleTime" SG_ 570 RollerBenchModeRequest 100;
BA_ "GenSigCycleTimeActive" SG_ 570 RollerBenchModeRequest 100;
BA_ "GenSigStartValue" SG_ 570 RollerBenchModeRequest 3;
BA_ "GenSigMaxLatency" SG_ 570 RollerBenchModeRequest 50;
BA_ "GenSigCycleTime" SG_ 570 RearAxleInBumperRange 100;
BA_ "GenSigCycleTimeActive" SG_ 570 RearAxleInBumperRange 100;
BA_ "GenSigStartValue" SG_ 570 RearAxleInBumperRange 3;
BA_ "GenSigMaxLatency" SG_ 570 RearAxleInBumperRange 50;
BA_ "GenSigCycleTime" SG_ 570 TractionControlDriverRqst 100;
BA_ "GenSigCycleTimeActive" SG_ 570 TractionControlDriverRqst 100;
BA_ "GenSigStartValue" SG_ 570 TractionControlDriverRqst 7;
BA_ "GenSigMaxLatency" SG_ 570 TractionControlDriverRqst 50;
BA_ "GenSigCycleTime" SG_ 300 XRSLBTrgtSpd_CRC 100;
BA_ "GenSigCycleTimeActive" SG_ 300 XRSLBTrgtSpd_CRC 100;
BA_ "GenSigStartValue" SG_ 300 XRSLBTrgtSpd_CRC 255;
BA_ "GenSigMaxLatency" SG_ 300 XRSLBTrgtSpd_CRC 45;
BA_ "E2EDataId" SG_ 300 XRSLBTrgtSpd_CRC 170;
BA_ "E2EDataLength" SG_ 300 XRSLBTrgtSpd_CRC 32;
BA_ "E2EProfile" SG_ 300 XRSLBTrgtSpd_CRC "P01";
BA_ "GenSigCycleTime" SG_ 300 XRSLTrgtSpd_CRC 100;
BA_ "GenSigCycleTimeActive" SG_ 300 XRSLTrgtSpd_CRC 100;
BA_ "GenSigStartValue" SG_ 300 XRSLTrgtSpd_CRC 255;
BA_ "GenSigMaxLatency" SG_ 300 XRSLTrgtSpd_CRC 45;
BA_ "E2EDataId" SG_ 300 XRSLTrgtSpd_CRC 169;
BA_ "E2EDataLength" SG_ 300 XRSLTrgtSpd_CRC 32;
BA_ "E2EProfile" SG_ 300 XRSLTrgtSpd_CRC "P01";
BA_ "GenSigCycleTime" SG_ 300 XRSLBTrgtSpd_SqC 100;
BA_ "GenSigCycleTimeActive" SG_ 300 XRSLBTrgtSpd_SqC 100;
BA_ "GenSigStartValue" SG_ 300 XRSLBTrgtSpd_SqC 14;
BA_ "GenSigMaxLatency" SG_ 300 XRSLBTrgtSpd_SqC 45;
BA_ "GenSigCycleTime" SG_ 300 XRSLTrgtSpd_SqC 100;
BA_ "GenSigCycleTimeActive" SG_ 300 XRSLTrgtSpd_SqC 100;
BA_ "GenSigStartValue" SG_ 300 XRSLTrgtSpd_SqC 14;
BA_ "GenSigMaxLatency" SG_ 300 XRSLTrgtSpd_SqC 45;
BA_ "GenSigCycleTime" SG_ 300 XRSLTrgtSpd_Rqst 100;
BA_ "GenSigCycleTimeActive" SG_ 300 XRSLTrgtSpd_Rqst 100;
BA_ "GenSigStartValue" SG_ 300 XRSLTrgtSpd_Rqst 65535;
BA_ "GenSigMaxLatency" SG_ 300 XRSLTrgtSpd_Rqst 45;
BA_ "GenSigCycleTime" SG_ 300 XRSLBTrgtSpd_Rqst 100;
BA_ "GenSigCycleTimeActive" SG_ 300 XRSLBTrgtSpd_Rqst 100;
BA_ "GenSigStartValue" SG_ 300 XRSLBTrgtSpd_Rqst 65535;
BA_ "GenSigMaxLatency" SG_ 300 XRSLBTrgtSpd_Rqst 45;
BA_ "GenSigCycleTime" SG_ 558 ReqdLongAccel_CRC 100;
BA_ "GenSigCycleTimeActive" SG_ 558 ReqdLongAccel_CRC 100;
BA_ "GenSigStartValue" SG_ 558 ReqdLongAccel_CRC 255;
BA_ "E2EDataId" SG_ 558 ReqdLongAccel_CRC 150;
BA_ "E2EDataLength" SG_ 558 ReqdLongAccel_CRC 32;
BA_ "E2EProfile" SG_ 558 ReqdLongAccel_CRC "P01";
BA_ "GenSigCycleTime" SG_ 558 ReqdLongAccel_CtrlMode 100;
BA_ "GenSigCycleTimeActive" SG_ 558 ReqdLongAccel_CtrlMode 100;
BA_ "GenSigStartValue" SG_ 558 ReqdLongAccel_CtrlMode 3;
BA_ "GenSigCycleTime" SG_ 558 ReqdLongAccel_Accel 100;
BA_ "GenSigCycleTimeActive" SG_ 558 ReqdLongAccel_Accel 100;
BA_ "GenSigStartValue" SG_ 558 ReqdLongAccel_Accel 65535;
BA_ "GenSigCycleTime" SG_ 558 ReqdLongAccel_SqC 100;
BA_ "GenSigCycleTimeActive" SG_ 558 ReqdLongAccel_SqC 100;
BA_ "GenSigStartValue" SG_ 558 ReqdLongAccel_SqC 14;
BA_ "GenSigCycleTime" SG_ 556 ReqdLongDist_CRC 100;
BA_ "GenSigCycleTimeActive" SG_ 556 ReqdLongDist_CRC 100;
BA_ "GenSigStartValue" SG_ 556 ReqdLongDist_CRC 255;
BA_ "E2EDataId" SG_ 556 ReqdLongDist_CRC 154;
BA_ "E2EDataLength" SG_ 556 ReqdLongDist_CRC 64;
BA_ "E2EProfile" SG_ 556 ReqdLongDist_CRC "P01";
BA_ "GenSigCycleTime" SG_ 556 ReqdLongDist_Distance 100;
BA_ "GenSigCycleTimeActive" SG_ 556 ReqdLongDist_Distance 100;
BA_ "GenSigStartValue" SG_ 556 ReqdLongDist_Distance 65535;
BA_ "GenSigCycleTime" SG_ 556 ReqdLongDist_AllwdBndLowr 100;
BA_ "GenSigCycleTimeActive" SG_ 556 ReqdLongDist_AllwdBndLowr 100;
BA_ "GenSigStartValue" SG_ 556 ReqdLongDist_AllwdBndLowr 65535;
BA_ "GenSigCycleTime" SG_ 556 ReqdLongDist_AllwdBndUppr 100;
BA_ "GenSigCycleTimeActive" SG_ 556 ReqdLongDist_AllwdBndUppr 100;
BA_ "GenSigStartValue" SG_ 556 ReqdLongDist_AllwdBndUppr 65535;
BA_ "GenSigCycleTime" SG_ 556 ReqdLongDist_SqC 100;
BA_ "GenSigCycleTimeActive" SG_ 556 ReqdLongDist_SqC 100;
BA_ "GenSigStartValue" SG_ 556 ReqdLongDist_SqC 14;
BA_ "GenSigCycleTime" SG_ 554 ReqdLongSpd_AllwdBndUppr 100;
BA_ "GenSigCycleTimeActive" SG_ 554 ReqdLongSpd_AllwdBndUppr 100;
BA_ "GenSigStartValue" SG_ 554 ReqdLongSpd_AllwdBndUppr 65535;
BA_ "GenSigCycleTime" SG_ 554 ReqdLongSpd_CRC 100;
BA_ "GenSigCycleTimeActive" SG_ 554 ReqdLongSpd_CRC 100;
BA_ "GenSigStartValue" SG_ 554 ReqdLongSpd_CRC 255;
BA_ "E2EDataId" SG_ 554 ReqdLongSpd_CRC 153;
BA_ "E2EDataLength" SG_ 554 ReqdLongSpd_CRC 64;
BA_ "E2EProfile" SG_ 554 ReqdLongSpd_CRC "P01";
BA_ "GenSigCycleTime" SG_ 554 ReqdLongSpd_SqC 100;
BA_ "GenSigCycleTimeActive" SG_ 554 ReqdLongSpd_SqC 100;
BA_ "GenSigStartValue" SG_ 554 ReqdLongSpd_SqC 14;
BA_ "GenSigCycleTime" SG_ 554 ReqdLongSpd_Spd 100;
BA_ "GenSigCycleTimeActive" SG_ 554 ReqdLongSpd_Spd 100;
BA_ "GenSigStartValue" SG_ 554 ReqdLongSpd_Spd 65535;
BA_ "GenSigCycleTime" SG_ 554 ReqdLongSpd_AllwdBndLowr 100;
BA_ "GenSigCycleTimeActive" SG_ 554 ReqdLongSpd_AllwdBndLowr 100;
BA_ "GenSigStartValue" SG_ 554 ReqdLongSpd_AllwdBndLowr 65535;
BA_ "GenSigCycleTime" SG_ 1246 TagAxleLoad 100;
BA_ "GenSigCycleTimeActive" SG_ 1246 TagAxleLoad 100;
BA_ "GenSigStartValue" SG_ 1246 TagAxleLoad 65535;
BA_ "GenSigMaxLatency" SG_ 1246 TagAxleLoad 250;
BA_ "GenSigCycleTime" SG_ 1246 SecondaryDriveAxleLoad 100;
BA_ "GenSigCycleTimeActive" SG_ 1246 SecondaryDriveAxleLoad 100;
BA_ "GenSigStartValue" SG_ 1246 SecondaryDriveAxleLoad 65535;
BA_ "GenSigMaxLatency" SG_ 1246 SecondaryDriveAxleLoad 250;
BA_ "GenSigCycleTime" SG_ 1246 PusherAxleLoad 100;
BA_ "GenSigCycleTimeActive" SG_ 1246 PusherAxleLoad 100;
BA_ "GenSigStartValue" SG_ 1246 PusherAxleLoad 65535;
BA_ "GenSigMaxLatency" SG_ 1246 PusherAxleLoad 250;
BA_ "GenSigCycleTime" SG_ 1246 DriveAxleLoad 100;
BA_ "GenSigCycleTimeActive" SG_ 1246 DriveAxleLoad 100;
BA_ "GenSigStartValue" SG_ 1246 DriveAxleLoad 65535;
BA_ "GenSigMaxLatency" SG_ 1246 DriveAxleLoad 250;
BA_ "GenSigCycleTime" SG_ 731 CCBTargetSpeedRequest 100;
BA_ "GenSigCycleTimeActive" SG_ 731 CCBTargetSpeedRequest 100;
BA_ "GenSigStartValue" SG_ 731 CCBTargetSpeedRequest 65535;
BA_ "GenSigMaxLatency" SG_ 731 CCBTargetSpeedRequest 50;
BA_ "GenSigCycleTime" SG_ 731 CCTargetSpeedRequest 100;
BA_ "GenSigCycleTimeActive" SG_ 731 CCTargetSpeedRequest 100;
BA_ "GenSigStartValue" SG_ 731 CCTargetSpeedRequest 65535;
BA_ "GenSigMaxLatency" SG_ 731 CCTargetSpeedRequest 50;
BA_ "GenSigCycleTime" SG_ 731 XRSLBTargetSpeedRequest 100;
BA_ "GenSigCycleTimeActive" SG_ 731 XRSLBTargetSpeedRequest 100;
BA_ "GenSigStartValue" SG_ 731 XRSLBTargetSpeedRequest 65535;
BA_ "GenSigMaxLatency" SG_ 731 XRSLBTargetSpeedRequest 150;
BA_ "GenSigCycleTime" SG_ 731 XRSLTargetSpeedRequest 100;
BA_ "GenSigCycleTimeActive" SG_ 731 XRSLTargetSpeedRequest 100;
BA_ "GenSigStartValue" SG_ 731 XRSLTargetSpeedRequest 65535;
BA_ "GenSigMaxLatency" SG_ 731 XRSLTargetSpeedRequest 50;
BA_ "GenSigCycleTime" SG_ 742 CCBSetSpeed 100;
BA_ "GenSigCycleTimeActive" SG_ 742 CCBSetSpeed 100;
BA_ "GenSigStartValue" SG_ 742 CCBSetSpeed 65535;
BA_ "GenSigMaxLatency" SG_ 742 CCBSetSpeed 30;
BA_ "GenSigCycleTime" SG_ 742 CCSetSpeed 100;
BA_ "GenSigCycleTimeActive" SG_ 742 CCSetSpeed 100;
BA_ "GenSigStartValue" SG_ 742 CCSetSpeed 65535;
BA_ "GenSigMaxLatency" SG_ 742 CCSetSpeed 35;
BA_ "GenSigCycleTime" SG_ 746 Pto1ConsentRequest 100;
BA_ "GenSigCycleTimeActive" SG_ 746 Pto1ConsentRequest 100;
BA_ "GenSigStartValue" SG_ 746 Pto1ConsentRequest 3;
BA_ "GenSigMaxLatency" SG_ 746 Pto1ConsentRequest 75;
BA_ "GenSigCycleTime" SG_ 746 SecondThrottle 100;
BA_ "GenSigCycleTimeActive" SG_ 746 SecondThrottle 100;
BA_ "GenSigStartValue" SG_ 746 SecondThrottle 3;
BA_ "GenSigMaxLatency" SG_ 746 SecondThrottle 50;
BA_ "GenSigCycleTime" SG_ 746 TransferCaseOrSplitboxPTOMode 100;
BA_ "GenSigCycleTimeActive" SG_ 746 TransferCaseOrSplitboxPTOMode 100;
BA_ "GenSigStartValue" SG_ 746 TransferCaseOrSplitboxPTOMode 3;
BA_ "GenSigMaxLatency" SG_ 746 TransferCaseOrSplitboxPTOMode 75;
BA_ "GenSigCycleTime" SG_ 746 PtosStatus 100;
BA_ "GenSigCycleTimeActive" SG_ 746 PtosStatus 100;
BA_ "GenSigStartValue" SG_ 746 PtosStatus 3;
BA_ "GenSigMaxLatency" SG_ 746 PtosStatus 75;
BA_ "GenSigCycleTime" SG_ 746 ConstructionSwitch_stat 100;
BA_ "GenSigCycleTimeActive" SG_ 746 ConstructionSwitch_stat 100;
BA_ "GenSigStartValue" SG_ 746 ConstructionSwitch_stat 3;
BA_ "GenSigMaxLatency" SG_ 746 ConstructionSwitch_stat 50;
BA_ "GenSigCycleTime" SG_ 746 RegenInhibitVehicleHeight 100;
BA_ "GenSigCycleTimeActive" SG_ 746 RegenInhibitVehicleHeight 100;
BA_ "GenSigStartValue" SG_ 746 RegenInhibitVehicleHeight 3;
BA_ "GenSigMaxLatency" SG_ 746 RegenInhibitVehicleHeight 50;
BA_ "GenSigCycleTime" SG_ 746 PtoRequest 100;
BA_ "GenSigCycleTimeActive" SG_ 746 PtoRequest 100;
BA_ "GenSigStartValue" SG_ 746 PtoRequest 3;
BA_ "GenSigMaxLatency" SG_ 746 PtoRequest 75;
BA_ "GenSigCycleTime" SG_ 746 Pto2Status 100;
BA_ "GenSigCycleTimeActive" SG_ 746 Pto2Status 100;
BA_ "GenSigStartValue" SG_ 746 Pto2Status 3;
BA_ "GenSigMaxLatency" SG_ 746 Pto2Status 75;
BA_ "GenSigCycleTime" SG_ 746 WarmUp_Request 100;
BA_ "GenSigCycleTimeActive" SG_ 746 WarmUp_Request 100;
BA_ "GenSigStartValue" SG_ 746 WarmUp_Request 3;
BA_ "GenSigMaxLatency" SG_ 746 WarmUp_Request 50;
BA_ "GenSigCycleTime" SG_ 746 ParkBrakeReleasePossible_stat 100;
BA_ "GenSigCycleTimeActive" SG_ 746 ParkBrakeReleasePossible_stat 100;
BA_ "GenSigStartValue" SG_ 746 ParkBrakeReleasePossible_stat 3;
BA_ "GenSigMaxLatency" SG_ 746 ParkBrakeReleasePossible_stat 50;
BA_ "GenSigCycleTime" SG_ 746 AC_CompressorClutchCmd 100;
BA_ "GenSigCycleTimeActive" SG_ 746 AC_CompressorClutchCmd 100;
BA_ "GenSigStartValue" SG_ 746 AC_CompressorClutchCmd 3;
BA_ "GenSigMaxLatency" SG_ 746 AC_CompressorClutchCmd 50;
BA_ "GenSigCycleTime" SG_ 746 Pto1Status 100;
BA_ "GenSigCycleTimeActive" SG_ 746 Pto1Status 100;
BA_ "GenSigStartValue" SG_ 746 Pto1Status 3;
BA_ "GenSigMaxLatency" SG_ 746 Pto1Status 75;
BA_ "GenSigCycleTime" SG_ 746 CtaGcAlternativeGearStarter 100;
BA_ "GenSigCycleTimeActive" SG_ 746 CtaGcAlternativeGearStarter 100;
BA_ "GenSigStartValue" SG_ 746 CtaGcAlternativeGearStarter 3;
BA_ "GenSigMaxLatency" SG_ 746 CtaGcAlternativeGearStarter 50;
BA_ "GenSigCycleTime" SG_ 746 Pto2ConsentRequest 100;
BA_ "GenSigCycleTimeActive" SG_ 746 Pto2ConsentRequest 100;
BA_ "GenSigStartValue" SG_ 746 Pto2ConsentRequest 3;
BA_ "GenSigMaxLatency" SG_ 746 Pto2ConsentRequest 75;
BA_ "GenSigCycleTime" SG_ 746 EngPtoConsumesTorque 100;
BA_ "GenSigCycleTimeActive" SG_ 746 EngPtoConsumesTorque 100;
BA_ "GenSigStartValue" SG_ 746 EngPtoConsumesTorque 3;
BA_ "GenSigMaxLatency" SG_ 746 EngPtoConsumesTorque 50;
BA_ "GenSigCycleTime" SG_ 746 TrailerABSStatus 100;
BA_ "GenSigCycleTimeActive" SG_ 746 TrailerABSStatus 100;
BA_ "GenSigStartValue" SG_ 746 TrailerABSStatus 3;
BA_ "GenSigMaxLatency" SG_ 746 TrailerABSStatus 50;
BA_ "GenSigCycleTime" SG_ 746 CtaGcInhibitGearEngaged 100;
BA_ "GenSigCycleTimeActive" SG_ 746 CtaGcInhibitGearEngaged 100;
BA_ "GenSigStartValue" SG_ 746 CtaGcInhibitGearEngaged 3;
BA_ "GenSigMaxLatency" SG_ 746 CtaGcInhibitGearEngaged 50;
BA_ "GenSigCycleTime" SG_ 746 RearEndPositionStatus 100;
BA_ "GenSigCycleTimeActive" SG_ 746 RearEndPositionStatus 100;
BA_ "GenSigStartValue" SG_ 746 RearEndPositionStatus 7;
BA_ "GenSigMaxLatency" SG_ 746 RearEndPositionStatus 50;
BA_ "GenSigCycleTime" SG_ 746 CtaGcReverseInhibit 100;
BA_ "GenSigCycleTimeActive" SG_ 746 CtaGcReverseInhibit 100;
BA_ "GenSigStartValue" SG_ 746 CtaGcReverseInhibit 3;
BA_ "GenSigMaxLatency" SG_ 746 CtaGcReverseInhibit 50;
BA_ "GenSigCycleTime" SG_ 746 AirCompressorStatus 100;
BA_ "GenSigCycleTimeActive" SG_ 746 AirCompressorStatus 100;
BA_ "GenSigStartValue" SG_ 746 AirCompressorStatus 3;
BA_ "GenSigMaxLatency" SG_ 746 AirCompressorStatus 50;
BA_ "GenSigCycleTime" SG_ 520 EnginePreheat_rqst 100;
BA_ "GenSigCycleTimeActive" SG_ 520 EnginePreheat_rqst 100;
BA_ "GenSigStartValue" SG_ 520 EnginePreheat_rqst 3;
BA_ "GenSigMaxLatency" SG_ 520 EnginePreheat_rqst 20;
BA_ "GenSigCycleTime" SG_ 520 EngineCrankRequest 100;
BA_ "GenSigCycleTimeActive" SG_ 520 EngineCrankRequest 100;
BA_ "GenSigStartValue" SG_ 520 EngineCrankRequest 3;
BA_ "GenSigMaxLatency" SG_ 520 EngineCrankRequest 20;
BA_ "GenSigCycleTime" SG_ 520 EngineStopRequest 100;
BA_ "GenSigCycleTimeActive" SG_ 520 EngineStopRequest 100;
BA_ "GenSigStartValue" SG_ 520 EngineStopRequest 3;
BA_ "GenSigMaxLatency" SG_ 520 EngineStopRequest 20;
BA_ "GenSigCycleTime" SG_ 520 EngineOperationCtrl 100;
BA_ "GenSigCycleTimeActive" SG_ 520 EngineOperationCtrl 100;
BA_ "GenSigStartValue" SG_ 520 EngineOperationCtrl 7;
BA_ "GenSigCycleTime" SG_ 520 ParkBrakeActuationStatus 100;
BA_ "GenSigCycleTimeActive" SG_ 520 ParkBrakeActuationStatus 100;
BA_ "GenSigStartValue" SG_ 520 ParkBrakeActuationStatus 7;
BA_ "GenSigCycleTime" SG_ 520 AcceleratorPedalPositionBackup 100;
BA_ "GenSigCycleTimeActive" SG_ 520 AcceleratorPedalPositionBackup 100;
BA_ "GenSigStartValue" SG_ 520 AcceleratorPedalPositionBackup 255;
BA_ "GenSigCycleTime" SG_ 520 XARDACU_AccelDemand 100;
BA_ "GenSigCycleTimeActive" SG_ 520 XARDACU_AccelDemand 100;
BA_ "GenSigStartValue" SG_ 520 XARDACU_AccelDemand 65535;
BA_ "GenSigMaxLatency" SG_ 520 XARDACU_AccelDemand 40;
BA_ "SeToolAncestorID_SIGNAL" SG_ 520 XARDACU_AccelDemand "x0000001D04254042";
BA_ "SeToolItemID_SIGNAL" SG_ 520 XARDACU_AccelDemand "x0000001D04254042";
BA_ "SeToolName_SIGNAL" SG_ 520 XARDACU_AccelDemand "AccelDemand";
BA_ "SeToolOwnerSigGroupID_SIGNAL" SG_ 520 XARDACU_AccelDemand "x0000001D043FB722";
BA_ "SeToolOwnerSigGroup_SIGNAL" SG_ 520 XARDACU_AccelDemand "XARDACU";
BA_ "SeToolVersion_SIGNAL" SG_ 520 XARDACU_AccelDemand "1";
BA_ "GenSigCycleTime" SG_ 520 ParkingBrake_stat 100;
BA_ "GenSigCycleTimeActive" SG_ 520 ParkingBrake_stat 100;
BA_ "GenSigStartValue" SG_ 520 ParkingBrake_stat 3;
BA_ "GenSigMaxLatency" SG_ 520 ParkingBrake_stat 25;
BA_ "GenSigCycleTime" SG_ 520 EngineSystemPowerDownRequest 100;
BA_ "GenSigCycleTimeActive" SG_ 520 EngineSystemPowerDownRequest 100;
BA_ "GenSigStartValue" SG_ 520 EngineSystemPowerDownRequest 3;
BA_ "GenSigMaxLatency" SG_ 520 EngineSystemPowerDownRequest 20;
BA_ "GenSigCycleTime" SG_ 520 TransmSystemPowerDown_rqst 100;
BA_ "GenSigCycleTimeActive" SG_ 520 TransmSystemPowerDown_rqst 100;
BA_ "GenSigStartValue" SG_ 520 TransmSystemPowerDown_rqst 3;
BA_ "GenSigMaxLatency" SG_ 520 TransmSystemPowerDown_rqst 20;
BA_ "GenSigCycleTime" SG_ 520 XARDACU_ControlMode 100;
BA_ "GenSigCycleTimeActive" SG_ 520 XARDACU_ControlMode 100;
BA_ "GenSigStartValue" SG_ 520 XARDACU_ControlMode 3;
BA_ "GenSigMaxLatency" SG_ 520 XARDACU_ControlMode 40;
BA_ "SeToolAncestorID_SIGNAL" SG_ 520 XARDACU_ControlMode "x0000001D0425403E";
BA_ "SeToolItemID_SIGNAL" SG_ 520 XARDACU_ControlMode "x0000001D0425403E";
BA_ "SeToolName_SIGNAL" SG_ 520 XARDACU_ControlMode "ControlMode";
BA_ "SeToolOwnerSigGroupID_SIGNAL" SG_ 520 XARDACU_ControlMode "x0000001D043FB722";
BA_ "SeToolOwnerSigGroup_SIGNAL" SG_ 520 XARDACU_ControlMode "XARDACU";
BA_ "SeToolVersion_SIGNAL" SG_ 520 XARDACU_ControlMode "1";
BA_ "GenSigCycleTime" SG_ 1306 DPF_ManualRegenerateRequest 100;
BA_ "GenSigCycleTimeActive" SG_ 1306 DPF_ManualRegenerateRequest 100;
BA_ "GenSigStartValue" SG_ 1306 DPF_ManualRegenerateRequest 3;
BA_ "GenSigMaxLatency" SG_ 1306 DPF_ManualRegenerateRequest 500;
BA_ "GenSigCycleTime" SG_ 1306 DPF_ManualRegenerateInhibit 100;
BA_ "GenSigCycleTimeActive" SG_ 1306 DPF_ManualRegenerateInhibit 100;
BA_ "GenSigStartValue" SG_ 1306 DPF_ManualRegenerateInhibit 3;
BA_ "GenSigMaxLatency" SG_ 1306 DPF_ManualRegenerateInhibit 500;
BA_ "GenSigCycleTime" SG_ 1306 WaterInFuelDrainRequest 100;
BA_ "GenSigCycleTimeActive" SG_ 1306 WaterInFuelDrainRequest 100;
BA_ "GenSigStartValue" SG_ 1306 WaterInFuelDrainRequest 3;
BA_ "GenSigMaxLatency" SG_ 1306 WaterInFuelDrainRequest 200;
BA_ "GenSigCycleTime" SG_ 1306 KFactor 100;
BA_ "GenSigCycleTimeActive" SG_ 1306 KFactor 100;
BA_ "GenSigStartValue" SG_ 1306 KFactor 65535;
BA_ "GenSigMaxLatency" SG_ 1306 KFactor 500;
BA_ "GenSigCycleTime" SG_ 930 AcCoolantPumpEngagementRequest 100;
BA_ "GenSigCycleTimeActive" SG_ 930 AcCoolantPumpEngagementRequest 100;
BA_ "GenSigStartValue" SG_ 930 AcCoolantPumpEngagementRequest 255;
BA_ "GenSigMaxLatency" SG_ 930 AcCoolantPumpEngagementRequest 100;
BA_ "GenSigCycleTime" SG_ 930 ACCoolingFanSpeedRequest 100;
BA_ "GenSigCycleTimeActive" SG_ 930 ACCoolingFanSpeedRequest 100;
BA_ "GenSigStartValue" SG_ 930 ACCoolingFanSpeedRequest 65535;
BA_ "GenSigMaxLatency" SG_ 930 ACCoolingFanSpeedRequest 100;
BA_ "GenSigCycleTime" SG_ 930 AirDryerCoolingFanSpeed_rqst 100;
BA_ "GenSigCycleTimeActive" SG_ 930 AirDryerCoolingFanSpeed_rqst 100;
BA_ "GenSigStartValue" SG_ 930 AirDryerCoolingFanSpeed_rqst 65535;
BA_ "GenSigMaxLatency" SG_ 930 AirDryerCoolingFanSpeed_rqst 100;
BA_ "GenSigCycleTime" SG_ 929 SelectedEcoCruiseLevel 100;
BA_ "GenSigCycleTimeActive" SG_ 929 SelectedEcoCruiseLevel 100;
BA_ "GenSigStartValue" SG_ 929 SelectedEcoCruiseLevel 7;
BA_ "GenSigMaxLatency" SG_ 929 SelectedEcoCruiseLevel 200;
BA_ "GenSigCycleTime" SG_ 929 ReqdDrvgMode 100;
BA_ "GenSigCycleTimeActive" SG_ 929 ReqdDrvgMode 100;
BA_ "GenSigStartValue" SG_ 929 ReqdDrvgMode 15;
BA_ "GenSigCycleTime" SG_ 929 MaintOilReset 100;
BA_ "GenSigCycleTimeActive" SG_ 929 MaintOilReset 100;
BA_ "GenSigStartValue" SG_ 929 MaintOilReset 3;
BA_ "GenSigMaxLatency" SG_ 929 MaintOilReset 100;
BA_ "GenSigCycleTime" SG_ 929 VIN_rqst 100;
BA_ "GenSigCycleTimeActive" SG_ 929 VIN_rqst 100;
BA_ "GenSigMaxLatency" SG_ 929 VIN_rqst 100;
BA_ "GenSigCycleTime" SG_ 929 MaintOilQuality 100;
BA_ "GenSigCycleTimeActive" SG_ 929 MaintOilQuality 100;
BA_ "GenSigStartValue" SG_ 929 MaintOilQuality 7;
BA_ "GenSigMaxLatency" SG_ 929 MaintOilQuality 100;
BA_ "GenSigCycleTime" SG_ 929 EcoRollEnableRequest 100;
BA_ "GenSigCycleTimeActive" SG_ 929 EcoRollEnableRequest 100;
BA_ "GenSigStartValue" SG_ 929 EcoRollEnableRequest 3;
BA_ "GenSigMaxLatency" SG_ 929 EcoRollEnableRequest 200;
BA_ "GenSigCycleTime" SG_ 929 ACCiRollInhibit 100;
BA_ "GenSigCycleTimeActive" SG_ 929 ACCiRollInhibit 100;
BA_ "GenSigStartValue" SG_ 929 ACCiRollInhibit 3;
BA_ "GenSigMaxLatency" SG_ 929 ACCiRollInhibit 40;
BA_ "GenSigCycleTime" SG_ 929 SpeedAdaptationLevelRqst 100;
BA_ "GenSigCycleTimeActive" SG_ 929 SpeedAdaptationLevelRqst 100;
BA_ "GenSigStartValue" SG_ 929 SpeedAdaptationLevelRqst 7;
BA_ "GenSigMaxLatency" SG_ 929 SpeedAdaptationLevelRqst 200;
BA_ "GenSigCycleTime" SG_ 929 SelfStartAssist_stat 100;
BA_ "GenSigCycleTimeActive" SG_ 929 SelfStartAssist_stat 100;
BA_ "GenSigStartValue" SG_ 929 SelfStartAssist_stat 3;
BA_ "GenSigMaxLatency" SG_ 929 SelfStartAssist_stat 250;
BA_ "GenSigCycleTime" SG_ 929 VehGcvw 100;
BA_ "GenSigCycleTimeActive" SG_ 929 VehGcvw 100;
BA_ "GenSigStartValue" SG_ 929 VehGcvw 255;
BA_ "GenSigCycleTime" SG_ 929 ACCiSeeDistanceGap 100;
BA_ "GenSigCycleTimeActive" SG_ 929 ACCiSeeDistanceGap 100;
BA_ "GenSigStartValue" SG_ 929 ACCiSeeDistanceGap 255;
BA_ "GenSigMaxLatency" SG_ 929 ACCiSeeDistanceGap 100;
BA_ "GenSigCycleTime" SG_ 929 RSLAssistStatus 100;
BA_ "GenSigCycleTimeActive" SG_ 929 RSLAssistStatus 100;
BA_ "GenSigStartValue" SG_ 929 RSLAssistStatus 7;
BA_ "GenSigMaxLatency" SG_ 929 RSLAssistStatus 250;
BA_ "GenSigCycleTime" SG_ 391 RequestedUpshiftDownshiftSteps 100;
BA_ "GenSigCycleTimeActive" SG_ 391 RequestedUpshiftDownshiftSteps 100;
BA_ "GenSigStartValue" SG_ 391 RequestedUpshiftDownshiftSteps 7;
BA_ "GenSigMaxLatency" SG_ 391 RequestedUpshiftDownshiftSteps 20;
BA_ "GenSigCycleTime" SG_ 391 LiftAxle1PositionStatus 100;
BA_ "GenSigCycleTimeActive" SG_ 391 LiftAxle1PositionStatus 100;
BA_ "GenSigStartValue" SG_ 391 LiftAxle1PositionStatus 7;
BA_ "GenSigMaxLatency" SG_ 391 LiftAxle1PositionStatus 25;
BA_ "GenSigCycleTime" SG_ 391 LimpHomeSwitch_stat 100;
BA_ "GenSigCycleTimeActive" SG_ 391 LimpHomeSwitch_stat 100;
BA_ "GenSigStartValue" SG_ 391 LimpHomeSwitch_stat 3;
BA_ "GenSigMaxLatency" SG_ 391 LimpHomeSwitch_stat 20;
BA_ "GenSigCycleTime" SG_ 391 EconomyPowerSwitch_stat 100;
BA_ "GenSigCycleTimeActive" SG_ 391 EconomyPowerSwitch_stat 100;
BA_ "GenSigStartValue" SG_ 391 EconomyPowerSwitch_stat 3;
BA_ "GenSigMaxLatency" SG_ 391 EconomyPowerSwitch_stat 20;
BA_ "GenSigCycleTime" SG_ 391 UpShiftRequest 100;
BA_ "GenSigCycleTimeActive" SG_ 391 UpShiftRequest 100;
BA_ "GenSigStartValue" SG_ 391 UpShiftRequest 3;
BA_ "GenSigMaxLatency" SG_ 391 UpShiftRequest 20;
BA_ "GenSigCycleTime" SG_ 391 ACCForwardVehicleDistance 100;
BA_ "GenSigCycleTimeActive" SG_ 391 ACCForwardVehicleDistance 100;
BA_ "GenSigStartValue" SG_ 391 ACCForwardVehicleDistance 255;
BA_ "GenSigMaxLatency" SG_ 391 ACCForwardVehicleDistance 20;
BA_ "GenSigCycleTime" SG_ 391 DownShiftRequest 100;
BA_ "GenSigCycleTimeActive" SG_ 391 DownShiftRequest 100;
BA_ "GenSigStartValue" SG_ 391 DownShiftRequest 3;
BA_ "GenSigMaxLatency" SG_ 391 DownShiftRequest 20;
BA_ "GenSigCycleTime" SG_ 391 CM_DisengageDrivelineRequest 100;
BA_ "GenSigCycleTimeActive" SG_ 391 CM_DisengageDrivelineRequest 100;
BA_ "GenSigStartValue" SG_ 391 CM_DisengageDrivelineRequest 3;
BA_ "GenSigMaxLatency" SG_ 391 CM_DisengageDrivelineRequest 20;
BA_ "GenSigCycleTime" SG_ 391 ACC_Status 100;
BA_ "GenSigCycleTimeActive" SG_ 391 ACC_Status 100;
BA_ "GenSigStartValue" SG_ 391 ACC_Status 7;
BA_ "GenSigMaxLatency" SG_ 391 ACC_Status 20;
BA_ "GenSigCycleTime" SG_ 391 SteeringValvePositionSetPoint 100;
BA_ "GenSigCycleTimeActive" SG_ 391 SteeringValvePositionSetPoint 100;
BA_ "GenSigStartValue" SG_ 391 SteeringValvePositionSetPoint 255;
BA_ "GenSigMaxLatency" SG_ 391 SteeringValvePositionSetPoint 20;
BA_ "GenSigCycleTime" SG_ 391 GearLeverPosition 100;
BA_ "GenSigCycleTimeActive" SG_ 391 GearLeverPosition 100;
BA_ "GenSigStartValue" SG_ 391 GearLeverPosition 15;
BA_ "GenSigMaxLatency" SG_ 391 GearLeverPosition 20;
BA_ "GenSigCycleTime" SG_ 391 RequestForHighestGearRatio 100;
BA_ "GenSigCycleTimeActive" SG_ 391 RequestForHighestGearRatio 100;
BA_ "GenSigStartValue" SG_ 391 RequestForHighestGearRatio 3;
BA_ "GenSigMaxLatency" SG_ 391 RequestForHighestGearRatio 20;
BA_ "GenSigCycleTime" SG_ 391 ACCForwardVehicleSpeed 100;
BA_ "GenSigCycleTimeActive" SG_ 391 ACCForwardVehicleSpeed 100;
BA_ "GenSigStartValue" SG_ 391 ACCForwardVehicleSpeed 255;
BA_ "GenSigMaxLatency" SG_ 391 ACCForwardVehicleSpeed 20;
BA_ "GenSigCycleTime" SG_ 1038 ReqdSGoMode_SqC 100;
BA_ "GenSigCycleTimeActive" SG_ 1038 ReqdSGoMode_SqC 100;
BA_ "GenSigStartValue" SG_ 1038 ReqdSGoMode_SqC 14;
BA_ "GenSigCycleTime" SG_ 1038 ReqdSGoMode_Mode 100;
BA_ "GenSigCycleTimeActive" SG_ 1038 ReqdSGoMode_Mode 100;
BA_ "GenSigStartValue" SG_ 1038 ReqdSGoMode_Mode 15;
BA_ "GenSigCycleTime" SG_ 1038 ReqdVehLongCtrlM_SqC 100;
BA_ "GenSigCycleTimeActive" SG_ 1038 ReqdVehLongCtrlM_SqC 100;
BA_ "GenSigStartValue" SG_ 1038 ReqdVehLongCtrlM_SqC 14;
BA_ "GenSigCycleTime" SG_ 1038 ReqdVehLongCtrlM_CRC 100;
BA_ "GenSigCycleTimeActive" SG_ 1038 ReqdVehLongCtrlM_CRC 100;
BA_ "GenSigStartValue" SG_ 1038 ReqdVehLongCtrlM_CRC 255;
BA_ "E2EDataId" SG_ 1038 ReqdVehLongCtrlM_CRC 151;
BA_ "E2EDataLength" SG_ 1038 ReqdVehLongCtrlM_CRC 16;
BA_ "E2EProfile" SG_ 1038 ReqdVehLongCtrlM_CRC "P01";
BA_ "GenSigCycleTime" SG_ 1038 ReqdDrvgDir_CRC 100;
BA_ "GenSigCycleTimeActive" SG_ 1038 ReqdDrvgDir_CRC 100;
BA_ "GenSigStartValue" SG_ 1038 ReqdDrvgDir_CRC 255;
BA_ "E2EDataId" SG_ 1038 ReqdDrvgDir_CRC 152;
BA_ "E2EDataLength" SG_ 1038 ReqdDrvgDir_CRC 16;
BA_ "E2EProfile" SG_ 1038 ReqdDrvgDir_CRC "P01";
BA_ "GenSigCycleTime" SG_ 1038 ReqdDrvgDir_SqC 100;
BA_ "GenSigCycleTimeActive" SG_ 1038 ReqdDrvgDir_SqC 100;
BA_ "GenSigStartValue" SG_ 1038 ReqdDrvgDir_SqC 14;
BA_ "GenSigCycleTime" SG_ 1038 ReqdEcoRoll 100;
BA_ "GenSigCycleTimeActive" SG_ 1038 ReqdEcoRoll 100;
BA_ "GenSigStartValue" SG_ 1038 ReqdEcoRoll 3;
BA_ "GenSigCycleTime" SG_ 1038 ReqdSGoMode_CRC 100;
BA_ "GenSigCycleTimeActive" SG_ 1038 ReqdSGoMode_CRC 100;
BA_ "GenSigStartValue" SG_ 1038 ReqdSGoMode_CRC 255;
BA_ "E2EDataId" SG_ 1038 ReqdSGoMode_CRC 155;
BA_ "E2EDataLength" SG_ 1038 ReqdSGoMode_CRC 16;
BA_ "E2EProfile" SG_ 1038 ReqdSGoMode_CRC "P01";
BA_ "GenSigCycleTime" SG_ 1038 ReqdDrvgDir_Direction 100;
BA_ "GenSigCycleTimeActive" SG_ 1038 ReqdDrvgDir_Direction 100;
BA_ "GenSigStartValue" SG_ 1038 ReqdDrvgDir_Direction 7;
BA_ "GenSigCycleTime" SG_ 1038 ReqdVehLongCtrlM_Mode 100;
BA_ "GenSigCycleTimeActive" SG_ 1038 ReqdVehLongCtrlM_Mode 100;
BA_ "GenSigStartValue" SG_ 1038 ReqdVehLongCtrlM_Mode 7;
BA_ "GenSigCycleTime" SG_ 1038 ReqdGear 100;
BA_ "GenSigCycleTimeActive" SG_ 1038 ReqdGear 100;
BA_ "GenSigStartValue" SG_ 1038 ReqdGear 31;
BA_ "GenSigSendType" SG_ 531 HorizonData 1;
BA_ "GenSigCycleTime" SG_ 531 HorizonData 100;
BA_ "GenSigCycleTimeActive" SG_ 531 HorizonData 100;
BA_ "GenSigSendType" SG_ 2671902706 FuncDiagDataTester 7;
BA_ "GenSigSendType" SG_ 2671902708 FuncDiagDataIntTesterF4 7;
BA_ "GenSigSendType" SG_ 1252 TECU_BB2_11P_FCS 7;
BA_ "GenSigSendType" SG_ 1251 HillDataPkgTECU 1;
BA_ "GenSigMaxLatency" SG_ 1251 HillDataPkgTECU 500;
BA_ "GenSigCycleTime" SG_ 1250 HillDataCtrlTECU_State 100;
BA_ "GenSigCycleTimeActive" SG_ 1250 HillDataCtrlTECU_State 100;
BA_ "GenSigStartValue" SG_ 1250 HillDataCtrlTECU_State 7;
BA_ "GenSigMaxLatency" SG_ 1250 HillDataCtrlTECU_State 500;
BA_ "GenSigCycleTime" SG_ 1250 HillDataCtrlTECU_AckCnt 100;
BA_ "GenSigCycleTimeActive" SG_ 1250 HillDataCtrlTECU_AckCnt 100;
BA_ "GenSigStartValue" SG_ 1250 HillDataCtrlTECU_AckCnt 3;
BA_ "GenSigMaxLatency" SG_ 1250 HillDataCtrlTECU_AckCnt 500;
BA_ "GenSigCycleTime" SG_ 1046 DriveModeSwitchUserOverride 100;
BA_ "GenSigCycleTimeActive" SG_ 1046 DriveModeSwitchUserOverride 100;
BA_ "GenSigStartValue" SG_ 1046 DriveModeSwitchUserOverride 7;
BA_ "GenSigMaxLatency" SG_ 1046 DriveModeSwitchUserOverride 101;
BA_REL_ "GenSigFirstTimeoutTime" BU_SG_REL_ ECM SG_ 1059 BatteryCurrent 3600;
BA_REL_ "GenSigTimeoutTime" BU_SG_REL_ ECM SG_ 1059 BatteryCurrent 900;
BA_REL_ "GenSigFirstTimeoutTime" BU_SG_REL_ TCM SG_ 1240 FrontAxle2Load 6000;
BA_REL_ "GenSigTimeoutTime" BU_SG_REL_ TCM SG_ 1240 FrontAxle2Load 1500;
BA_REL_ "GenSigFirstTimeoutTime" BU_SG_REL_ TCM SG_ 1240 FrontAxle1Load 6000;
BA_REL_ "GenSigTimeoutTime" BU_SG_REL_ TCM SG_ 1240 FrontAxle1Load 1500;
BA_REL_ "GenSigFirstTimeoutTime" BU_SG_REL_ TCM SG_ 567 DriveModeSwitchStat_Rqst 3000;
BA_REL_ "GenSigTimeoutTime" BU_SG_REL_ TCM SG_ 567 DriveModeSwitchStat_Rqst 120;
BA_REL_ "GenSigFirstTimeoutTime" BU_SG_REL_ TCM SG_ 567 GearLeverPosition2_SqC 3000;
BA_REL_ "GenSigTimeoutTime" BU_SG_REL_ TCM SG_ 567 GearLeverPosition2_SqC 120;
BA_REL_ "GenSigFirstTimeoutTime" BU_SG_REL_ TCM SG_ 567 UpDownShiftRqst_Rqst 3000;
BA_REL_ "GenSigTimeoutTime" BU_SG_REL_ TCM SG_ 567 UpDownShiftRqst_Rqst 120;
BA_REL_ "GenSigFirstTimeoutTime" BU_SG_REL_ TCM SG_ 567 DriveModeSwitchStat_CRC 3000;
BA_REL_ "GenSigTimeoutTime" BU_SG_REL_ TCM SG_ 567 DriveModeSwitchStat_CRC 120;
BA_REL_ "GenSigFirstTimeoutTime" BU_SG_REL_ TCM SG_ 567 UpDownShiftRqst_SqC 3000;
BA_REL_ "GenSigTimeoutTime" BU_SG_REL_ TCM SG_ 567 UpDownShiftRqst_SqC 120;
BA_REL_ "GenSigFirstTimeoutTime" BU_SG_REL_ TCM SG_ 567 UpDownShiftRqst_CRC 3000;
BA_REL_ "GenSigTimeoutTime" BU_SG_REL_ TCM SG_ 567 UpDownShiftRqst_CRC 120;
BA_REL_ "GenSigFirstTimeoutTime" BU_SG_REL_ TCM SG_ 567 DriveModeSwitchStat_SqC 3000;
BA_REL_ "GenSigTimeoutTime" BU_SG_REL_ TCM SG_ 567 DriveModeSwitchStat_SqC 120;
BA_REL_ "GenSigFirstTimeoutTime" BU_SG_REL_ TCM SG_ 567 GearLeverPosition2_Rqst 3000;
BA_REL_ "GenSigTimeoutTime" BU_SG_REL_ TCM SG_ 567 GearLeverPosition2_Rqst 120;
BA_REL_ "GenSigFirstTimeoutTime" BU_SG_REL_ TCM SG_ 567 GearLeverPosition2_CRC 3000;
BA_REL_ "GenSigTimeoutTime" BU_SG_REL_ TCM SG_ 567 GearLeverPosition2_CRC 120;
BA_REL_ "GenSigFirstTimeoutTime" BU_SG_REL_ ECM SG_ 725 ESCReqEMS_CtrlTrimStat 3000;
BA_REL_ "GenSigTimeoutTime" BU_SG_REL_ ECM SG_ 725 ESCReqEMS_CtrlTrimStat 270;
BA_REL_ "GenSigFirstTimeoutTime" BU_SG_REL_ TCM SG_ 725 ESCReqEMS_CtrlTrimStat 3000;
BA_REL_ "GenSigTimeoutTime" BU_SG_REL_ TCM SG_ 725 ESCReqEMS_CtrlTrimStat 300;
BA_REL_ "GenSigFirstTimeoutTime" BU_SG_REL_ ECM SG_ 725 ESCReqEMS_CtrlTrimValue 3000;
BA_REL_ "GenSigTimeoutTime" BU_SG_REL_ ECM SG_ 725 ESCReqEMS_CtrlTrimValue 270;
BA_REL_ "GenSigFirstTimeoutTime" BU_SG_REL_ TCM SG_ 725 ESCReqEMS_CtrlTrimValue 3000;
BA_REL_ "GenSigTimeoutTime" BU_SG_REL_ TCM SG_ 725 ESCReqEMS_CtrlTrimValue 300;
BA_REL_ "GenSigFirstTimeoutTime" BU_SG_REL_ ECM SG_ 725 StoreIdleValue 3000;
BA_REL_ "GenSigTimeoutTime" BU_SG_REL_ ECM SG_ 725 StoreIdleValue 270;
BA_REL_ "GenSigFirstTimeoutTime" BU_SG_REL_ TCM SG_ 725 ESCReqEMS_CtrlTrimMode 3000;
BA_REL_ "GenSigTimeoutTime" BU_SG_REL_ TCM SG_ 725 ESCReqEMS_CtrlTrimMode 300;
BA_REL_ "GenSigFirstTimeoutTime" BU_SG_REL_ ECM SG_ 725 ESCReqEMS_CtrlTrimMode 3000;
BA_REL_ "GenSigTimeoutTime" BU_SG_REL_ ECM SG_ 725 ESCReqEMS_CtrlTrimMode 270;
BA_REL_ "GenSigFirstTimeoutTime" BU_SG_REL_ ECM SG_ 725 TrailerConnected 3000;
BA_REL_ "GenSigTimeoutTime" BU_SG_REL_ ECM SG_ 725 TrailerConnected 500;
BA_REL_ "GenSigFirstTimeoutTime" BU_SG_REL_ TCM SG_ 725 TrailerConnected 3000;
BA_REL_ "GenSigTimeoutTime" BU_SG_REL_ TCM SG_ 725 TrailerConnected 500;
BA_REL_ "GenSigFirstTimeoutTime" BU_SG_REL_ ECM SG_ 725 ESCReqEMS_CtrlTrimReq 3000;
BA_REL_ "GenSigTimeoutTime" BU_SG_REL_ ECM SG_ 725 ESCReqEMS_CtrlTrimReq 270;
BA_REL_ "GenSigFirstTimeoutTime" BU_SG_REL_ TCM SG_ 725 ESCReqEMS_CtrlTrimReq 3000;
BA_REL_ "GenSigTimeoutTime" BU_SG_REL_ TCM SG_ 725 ESCReqEMS_CtrlTrimReq 300;
BA_REL_ "GenSigFirstTimeoutTime" BU_SG_REL_ TCM SG_ 298 ReqTSC_Tq 3000;
BA_REL_ "GenSigTimeoutTime" BU_SG_REL_ TCM SG_ 298 ReqTSC_Tq 60;
BA_REL_ "GenSigFirstTimeoutTime" BU_SG_REL_ ECM SG_ 298 ReqTSC_Tq 3000;
BA_REL_ "GenSigTimeoutTime" BU_SG_REL_ ECM SG_ 298 ReqTSC_Tq 60;
BA_REL_ "GenSigFirstTimeoutTime" BU_SG_REL_ ECM SG_ 298 ReqTSC_CtrlMode 3000;
BA_REL_ "GenSigTimeoutTime" BU_SG_REL_ ECM SG_ 298 ReqTSC_CtrlMode 60;
BA_REL_ "GenSigFirstTimeoutTime" BU_SG_REL_ TCM SG_ 298 ReqTSC_CtrlMode 3000;
BA_REL_ "GenSigTimeoutTime" BU_SG_REL_ TCM SG_ 298 ReqTSC_CtrlMode 60;
BA_REL_ "GenSigFirstTimeoutTime" BU_SG_REL_ ECM SG_ 298 ReqTSC_CRC 3000;
BA_REL_ "GenSigTimeoutTime" BU_SG_REL_ ECM SG_ 298 ReqTSC_CRC 60;
BA_REL_ "GenSigFirstTimeoutTime" BU_SG_REL_ TCM SG_ 298 ReqTSC_CRC 3000;
BA_REL_ "GenSigTimeoutTime" BU_SG_REL_ TCM SG_ 298 ReqTSC_CRC 60;
BA_REL_ "GenSigFirstTimeoutTime" BU_SG_REL_ TCM SG_ 298 ReqTSC_SqC 3000;
BA_REL_ "GenSigTimeoutTime" BU_SG_REL_ TCM SG_ 298 ReqTSC_SqC 60;
BA_REL_ "GenSigFirstTimeoutTime" BU_SG_REL_ ECM SG_ 298 ReqTSC_SqC 3000;
BA_REL_ "GenSigTimeoutTime" BU_SG_REL_ ECM SG_ 298 ReqTSC_SqC 60;
BA_REL_ "GenSigFirstTimeoutTime" BU_SG_REL_ ECM SG_ 298 ReqTSC_Spd 3000;
BA_REL_ "GenSigTimeoutTime" BU_SG_REL_ ECM SG_ 298 ReqTSC_Spd 60;
BA_REL_ "GenSigFirstTimeoutTime" BU_SG_REL_ TCM SG_ 298 ReqTSC_Spd 3000;
BA_REL_ "GenSigTimeoutTime" BU_SG_REL_ TCM SG_ 298 ReqTSC_Spd 60;
BA_REL_ "GenSigFirstTimeoutTime" BU_SG_REL_ TCM SG_ 299 AccPedal_CRC 3000;
BA_REL_ "GenSigTimeoutTime" BU_SG_REL_ TCM SG_ 299 AccPedal_CRC 60;
BA_REL_ "GenSigFirstTimeoutTime" BU_SG_REL_ ECM SG_ 299 AccPedal_CRC 3000;
BA_REL_ "GenSigTimeoutTime" BU_SG_REL_ ECM SG_ 299 AccPedal_CRC 60;
BA_REL_ "GenSigFirstTimeoutTime" BU_SG_REL_ ECM SG_ 299 AccPedal_SqC 3000;
BA_REL_ "GenSigTimeoutTime" BU_SG_REL_ ECM SG_ 299 AccPedal_SqC 60;
BA_REL_ "GenSigFirstTimeoutTime" BU_SG_REL_ TCM SG_ 299 AccPedal_SqC 3000;
BA_REL_ "GenSigTimeoutTime" BU_SG_REL_ TCM SG_ 299 AccPedal_SqC 60;
BA_REL_ "GenSigFirstTimeoutTime" BU_SG_REL_ TCM SG_ 299 AcceleratorPedalPositionVendor 3000;
BA_REL_ "GenSigTimeoutTime" BU_SG_REL_ TCM SG_ 299 AcceleratorPedalPositionVendor 60;
BA_REL_ "GenSigFirstTimeoutTime" BU_SG_REL_ TCM SG_ 299 AccPedal_Qlty 3000;
BA_REL_ "GenSigTimeoutTime" BU_SG_REL_ TCM SG_ 299 AccPedal_Qlty 60;
BA_REL_ "GenSigFirstTimeoutTime" BU_SG_REL_ ECM SG_ 299 AccPedal_Qlty 3000;
BA_REL_ "GenSigTimeoutTime" BU_SG_REL_ ECM SG_ 299 AccPedal_Qlty 60;
BA_REL_ "GenSigFirstTimeoutTime" BU_SG_REL_ ECM SG_ 299 AccPedal_Pos 3000;
BA_REL_ "GenSigTimeoutTime" BU_SG_REL_ ECM SG_ 299 AccPedal_Pos 60;
BA_REL_ "GenSigFirstTimeoutTime" BU_SG_REL_ TCM SG_ 299 AccPedal_Pos 3000;
BA_REL_ "GenSigTimeoutTime" BU_SG_REL_ TCM SG_ 299 AccPedal_Pos 60;
BA_REL_ "GenSigFirstTimeoutTime" BU_SG_REL_ ECM SG_ 569 ReverseGearEngaged 3000;
BA_REL_ "GenSigTimeoutTime" BU_SG_REL_ ECM SG_ 569 ReverseGearEngaged 120;
BA_REL_ "GenSigFirstTimeoutTime" BU_SG_REL_ ECM SG_ 569 SecuredNeutralPosition 3000;
BA_REL_ "GenSigTimeoutTime" BU_SG_REL_ ECM SG_ 569 SecuredNeutralPosition 120;
BA_REL_ "GenSigFirstTimeoutTime" BU_SG_REL_ ECM SG_ 569 TransmissionNeutralSwitch 3000;
BA_REL_ "GenSigTimeoutTime" BU_SG_REL_ ECM SG_ 569 TransmissionNeutralSwitch 120;
BA_REL_ "GenSigFirstTimeoutTime" BU_SG_REL_ TCM SG_ 569 LevelControlInformation 3000;
BA_REL_ "GenSigTimeoutTime" BU_SG_REL_ TCM SG_ 569 LevelControlInformation 120;
BA_REL_ "GenSigFirstTimeoutTime" BU_SG_REL_ ECM SG_ 569 TransmLowRangeSenseSwitch 3000;
BA_REL_ "GenSigTimeoutTime" BU_SG_REL_ ECM SG_ 569 TransmLowRangeSenseSwitch 120;
BA_REL_ "GenSigFirstTimeoutTime" BU_SG_REL_ ECM SG_ 568 EngSystPwrDwn_Rqst 3000;
BA_REL_ "GenSigTimeoutTime" BU_SG_REL_ ECM SG_ 568 EngSystPwrDwn_Rqst 120;
BA_REL_ "GenSigFirstTimeoutTime" BU_SG_REL_ TCM SG_ 568 TrnsmSystPwrDwn_SqC 3000;
BA_REL_ "GenSigTimeoutTime" BU_SG_REL_ TCM SG_ 568 TrnsmSystPwrDwn_SqC 120;
BA_REL_ "GenSigFirstTimeoutTime" BU_SG_REL_ ECM SG_ 568 EngSystPwrDwn_CRC 3000;
BA_REL_ "GenSigTimeoutTime" BU_SG_REL_ ECM SG_ 568 EngSystPwrDwn_CRC 120;
BA_REL_ "GenSigFirstTimeoutTime" BU_SG_REL_ ECM SG_ 568 EngCrnk_Rqst 3000;
BA_REL_ "GenSigTimeoutTime" BU_SG_REL_ ECM SG_ 568 EngCrnk_Rqst 120;
BA_REL_ "GenSigFirstTimeoutTime" BU_SG_REL_ TCM SG_ 568 TrnsmSystPwrDwn_Rqst 3000;
BA_REL_ "GenSigTimeoutTime" BU_SG_REL_ TCM SG_ 568 TrnsmSystPwrDwn_Rqst 120;
BA_REL_ "GenSigFirstTimeoutTime" BU_SG_REL_ TCM SG_ 568 EcnmyPwrSwt_Sts 3000;
BA_REL_ "GenSigTimeoutTime" BU_SG_REL_ TCM SG_ 568 EcnmyPwrSwt_Sts 120;
BA_REL_ "GenSigFirstTimeoutTime" BU_SG_REL_ ECM SG_ 568 EngCrnk_SqC 3000;
BA_REL_ "GenSigTimeoutTime" BU_SG_REL_ ECM SG_ 568 EngCrnk_SqC 120;
BA_REL_ "GenSigFirstTimeoutTime" BU_SG_REL_ TCM SG_ 568 EcnmyPwrSwt_CRC 3000;
BA_REL_ "GenSigTimeoutTime" BU_SG_REL_ TCM SG_ 568 EcnmyPwrSwt_CRC 120;
BA_REL_ "GenSigFirstTimeoutTime" BU_SG_REL_ ECM SG_ 568 EngCrnk_CRC 3000;
BA_REL_ "GenSigTimeoutTime" BU_SG_REL_ ECM SG_ 568 EngCrnk_CRC 120;
BA_REL_ "GenSigFirstTimeoutTime" BU_SG_REL_ TCM SG_ 568 EcnmyPwrSwt_SqC 3000;
BA_REL_ "GenSigTimeoutTime" BU_SG_REL_ TCM SG_ 568 EcnmyPwrSwt_SqC 120;
BA_REL_ "GenSigFirstTimeoutTime" BU_SG_REL_ ECM SG_ 568 EngSystPwrDwn_SqC 3000;
BA_REL_ "GenSigTimeoutTime" BU_SG_REL_ ECM SG_ 568 EngSystPwrDwn_SqC 120;
BA_REL_ "GenSigFirstTimeoutTime" BU_SG_REL_ TCM SG_ 568 TrnsmSystPwrDwn_CRC 3000;
BA_REL_ "GenSigTimeoutTime" BU_SG_REL_ TCM SG_ 568 TrnsmSystPwrDwn_CRC 120;
BA_REL_ "GenSigFirstTimeoutTime" BU_SG_REL_ ECM SG_ 1563 MIStatusExtVMCU 24000;
BA_REL_ "GenSigTimeoutTime" BU_SG_REL_ ECM SG_ 1563 MIStatusExtVMCU 6000;
BA_REL_ "GenSigFirstTimeoutTime" BU_SG_REL_ ECM SG_ 1563 MIStatusVMCU 24000;
BA_REL_ "GenSigTimeoutTime" BU_SG_REL_ ECM SG_ 1563 MIStatusVMCU 6000;
BA_REL_ "GenSigFirstTimeoutTime" BU_SG_REL_ ECM SG_ 1563 MIDistinctWarningExtVMCU 24000;
BA_REL_ "GenSigTimeoutTime" BU_SG_REL_ ECM SG_ 1563 MIDistinctWarningExtVMCU 6000;
BA_REL_ "GenSigFirstTimeoutTime" BU_SG_REL_ ECM SG_ 1563 MIDistinctWarningVMCU 24000;
BA_REL_ "GenSigTimeoutTime" BU_SG_REL_ ECM SG_ 1563 MIDistinctWarningVMCU 6000;
BA_REL_ "GenSigFirstTimeoutTime" BU_SG_REL_ TCM SG_ 1309 HillDataPkgTGW 12000;
BA_REL_ "GenSigTimeoutTime" BU_SG_REL_ TCM SG_ 1309 HillDataPkgTGW 3000;
BA_REL_ "GenSigFirstTimeoutTime" BU_SG_REL_ TCM SG_ 1308 HillDataCtrlTGW_AckCnt 12000;
BA_REL_ "GenSigTimeoutTime" BU_SG_REL_ TCM SG_ 1308 HillDataCtrlTGW_AckCnt 3000;
BA_REL_ "GenSigFirstTimeoutTime" BU_SG_REL_ ECM SG_ 1308 ExhManifAirInjectionInhibit 12000;
BA_REL_ "GenSigTimeoutTime" BU_SG_REL_ ECM SG_ 1308 ExhManifAirInjectionInhibit 3000;
BA_REL_ "GenSigFirstTimeoutTime" BU_SG_REL_ ECM SG_ 1308 OBDUTCTime_Hours 12000;
BA_REL_ "GenSigTimeoutTime" BU_SG_REL_ ECM SG_ 1308 OBDUTCTime_Hours 3000;
BA_REL_ "GenSigFirstTimeoutTime" BU_SG_REL_ TCM SG_ 1308 HillDataCtrlTGW_State 12000;
BA_REL_ "GenSigTimeoutTime" BU_SG_REL_ TCM SG_ 1308 HillDataCtrlTGW_State 3000;
BA_REL_ "GenSigFirstTimeoutTime" BU_SG_REL_ ECM SG_ 1308 OBDUTCTime_Day 12000;
BA_REL_ "GenSigTimeoutTime" BU_SG_REL_ ECM SG_ 1308 OBDUTCTime_Day 3000;
BA_REL_ "GenSigFirstTimeoutTime" BU_SG_REL_ ECM SG_ 1308 OBDUTCTime_Year 12000;
BA_REL_ "GenSigTimeoutTime" BU_SG_REL_ ECM SG_ 1308 OBDUTCTime_Year 3000;
BA_REL_ "GenSigFirstTimeoutTime" BU_SG_REL_ ECM SG_ 1308 OBDUTCTime_Month 12000;
BA_REL_ "GenSigTimeoutTime" BU_SG_REL_ ECM SG_ 1308 OBDUTCTime_Month 3000;
BA_REL_ "GenSigFirstTimeoutTime" BU_SG_REL_ ECM SG_ 1308 DPF_ManualRegenerateTimeReq 12000;
BA_REL_ "GenSigTimeoutTime" BU_SG_REL_ ECM SG_ 1308 DPF_ManualRegenerateTimeReq 3000;
BA_REL_ "GenSigFirstTimeoutTime" BU_SG_REL_ ECM SG_ 1308 OBDUTCTime_Seconds 12000;
BA_REL_ "GenSigTimeoutTime" BU_SG_REL_ ECM SG_ 1308 OBDUTCTime_Seconds 3000;
BA_REL_ "GenSigFirstTimeoutTime" BU_SG_REL_ ECM SG_ 1308 OBDUTCTime_Minutes 12000;
BA_REL_ "GenSigTimeoutTime" BU_SG_REL_ ECM SG_ 1308 OBDUTCTime_Minutes 3000;
BA_REL_ "GenSigFirstTimeoutTime" BU_SG_REL_ ECM SG_ 1307 OBD_Timestamp 12000;
BA_REL_ "GenSigTimeoutTime" BU_SG_REL_ ECM SG_ 1307 OBD_Timestamp 3000;
BA_REL_ "GenSigFirstTimeoutTime" BU_SG_REL_ TCM SG_ 1241 PwtCCUnderSpeedRequest 6000;
BA_REL_ "GenSigTimeoutTime" BU_SG_REL_ TCM SG_ 1241 PwtCCUnderSpeedRequest 1500;
BA_REL_ "GenSigFirstTimeoutTime" BU_SG_REL_ ECM SG_ 1241 StarterMotorReset_rqst 6000;
BA_REL_ "GenSigTimeoutTime" BU_SG_REL_ ECM SG_ 1241 StarterMotorReset_rqst 1500;
BA_REL_ "GenSigFirstTimeoutTime" BU_SG_REL_ TCM SG_ 1185 SavedHeightControlMode 4800;
BA_REL_ "GenSigTimeoutTime" BU_SG_REL_ TCM SG_ 1185 SavedHeightControlMode 1200;
BA_REL_ "GenSigFirstTimeoutTime" BU_SG_REL_ TCM SG_ 1185 SpeedAdaptEnableRqst_SpeedLimit 4800;
BA_REL_ "GenSigTimeoutTime" BU_SG_REL_ TCM SG_ 1185 SpeedAdaptEnableRqst_SpeedLimit 1200;
BA_REL_ "GenSigFirstTimeoutTime" BU_SG_REL_ TCM SG_ 1185 SpeedAdaptEnableRqst_Curve 4800;
BA_REL_ "GenSigTimeoutTime" BU_SG_REL_ TCM SG_ 1185 SpeedAdaptEnableRqst_Curve 1200;
BA_REL_ "GenSigFirstTimeoutTime" BU_SG_REL_ TCM SG_ 1185 SpeedAdaptEnableRqst_SlowTraffic 4800;
BA_REL_ "GenSigTimeoutTime" BU_SG_REL_ TCM SG_ 1185 SpeedAdaptEnableRqst_SlowTraffic 1200;
BA_REL_ "GenSigFirstTimeoutTime" BU_SG_REL_ ECM SG_ 1060 EngOvrrideCtrlStat_FireTruckMode 3600;
BA_REL_ "GenSigTimeoutTime" BU_SG_REL_ ECM SG_ 1060 EngOvrrideCtrlStat_FireTruckMode 900;
BA_REL_ "GenSigFirstTimeoutTime" BU_SG_REL_ ECM SG_ 1060 EngOvrrideCtrlStat_ProtOvrrMode 3600;
BA_REL_ "GenSigTimeoutTime" BU_SG_REL_ ECM SG_ 1060 EngOvrrideCtrlStat_ProtOvrrMode 900;
BA_REL_ "GenSigFirstTimeoutTime" BU_SG_REL_ ECM SG_ 1060 EngOvrrideCtrlStat_StartOvrrMode 3600;
BA_REL_ "GenSigTimeoutTime" BU_SG_REL_ ECM SG_ 1060 EngOvrrideCtrlStat_StartOvrrMode 900;
BA_REL_ "GenSigFirstTimeoutTime" BU_SG_REL_ ECM SG_ 1060 EngineAirShutOffCommandStatus 3600;
BA_REL_ "GenSigTimeoutTime" BU_SG_REL_ ECM SG_ 1060 EngineAirShutOffCommandStatus 900;
BA_REL_ "GenSigFirstTimeoutTime" BU_SG_REL_ ECM SG_ 932 ParkBrake_OBDState 3000;
BA_REL_ "GenSigTimeoutTime" BU_SG_REL_ ECM SG_ 932 ParkBrake_OBDState 600;
BA_REL_ "GenSigFirstTimeoutTime" BU_SG_REL_ ECM SG_ 932 AltParallelOperation 3000;
BA_REL_ "GenSigTimeoutTime" BU_SG_REL_ ECM SG_ 932 AltParallelOperation 600;
BA_REL_ "GenSigFirstTimeoutTime" BU_SG_REL_ ECM SG_ 932 AltLR_cut_offSpeed 3000;
BA_REL_ "GenSigTimeoutTime" BU_SG_REL_ ECM SG_ 932 AltLR_cut_offSpeed 600;
BA_REL_ "GenSigFirstTimeoutTime" BU_SG_REL_ ECM SG_ 932 AltVoltageSetValue 3000;
BA_REL_ "GenSigTimeoutTime" BU_SG_REL_ ECM SG_ 932 AltVoltageSetValue 600;
BA_REL_ "GenSigFirstTimeoutTime" BU_SG_REL_ ECM SG_ 932 AltExitationCurrentLimit 3000;
BA_REL_ "GenSigTimeoutTime" BU_SG_REL_ ECM SG_ 932 AltExitationCurrentLimit 600;
BA_REL_ "GenSigFirstTimeoutTime" BU_SG_REL_ ECM SG_ 932 CruiseControlStates 3000;
BA_REL_ "GenSigTimeoutTime" BU_SG_REL_ ECM SG_ 932 CruiseControlStates 600;
BA_REL_ "GenSigFirstTimeoutTime" BU_SG_REL_ TCM SG_ 932 CruiseControlStates 3000;
BA_REL_ "GenSigTimeoutTime" BU_SG_REL_ TCM SG_ 932 CruiseControlStates 600;
BA_REL_ "GenSigFirstTimeoutTime" BU_SG_REL_ ECM SG_ 932 AltDataSelectionWordRx 3000;
BA_REL_ "GenSigTimeoutTime" BU_SG_REL_ ECM SG_ 932 AltDataSelectionWordRx 600;
BA_REL_ "GenSigFirstTimeoutTime" BU_SG_REL_ ECM SG_ 932 ClutchSwitch 3000;
BA_REL_ "GenSigTimeoutTime" BU_SG_REL_ ECM SG_ 932 ClutchSwitch 600;
BA_REL_ "GenSigFirstTimeoutTime" BU_SG_REL_ ECM SG_ 932 AltLR_RampTime 3000;
BA_REL_ "GenSigTimeoutTime" BU_SG_REL_ ECM SG_ 932 AltLR_RampTime 600;
BA_REL_ "GenSigFirstTimeoutTime" BU_SG_REL_ TCM SG_ 932 CACCStatus 3000;
BA_REL_ "GenSigTimeoutTime" BU_SG_REL_ TCM SG_ 932 CACCStatus 600;
BA_REL_ "GenSigFirstTimeoutTime" BU_SG_REL_ ECM SG_ 931 CCBTrgtSpd_CRC 3000;
BA_REL_ "GenSigTimeoutTime" BU_SG_REL_ ECM SG_ 931 CCBTrgtSpd_CRC 600;
BA_REL_ "GenSigFirstTimeoutTime" BU_SG_REL_ TCM SG_ 931 CCBTrgtSpd_CRC 3000;
BA_REL_ "GenSigTimeoutTime" BU_SG_REL_ TCM SG_ 931 CCBTrgtSpd_CRC 600;
BA_REL_ "GenSigFirstTimeoutTime" BU_SG_REL_ ECM SG_ 931 CCTrgtSpd_SqC 3000;
BA_REL_ "GenSigTimeoutTime" BU_SG_REL_ ECM SG_ 931 CCTrgtSpd_SqC 600;
BA_REL_ "GenSigFirstTimeoutTime" BU_SG_REL_ TCM SG_ 931 CCTrgtSpd_SqC 3000;
BA_REL_ "GenSigTimeoutTime" BU_SG_REL_ TCM SG_ 931 CCTrgtSpd_SqC 600;
BA_REL_ "GenSigFirstTimeoutTime" BU_SG_REL_ ECM SG_ 931 CCTrgtSpd_Rqst 3000;
BA_REL_ "GenSigTimeoutTime" BU_SG_REL_ ECM SG_ 931 CCTrgtSpd_Rqst 600;
BA_REL_ "GenSigFirstTimeoutTime" BU_SG_REL_ TCM SG_ 931 CCTrgtSpd_Rqst 3000;
BA_REL_ "GenSigTimeoutTime" BU_SG_REL_ TCM SG_ 931 CCTrgtSpd_Rqst 600;
BA_REL_ "GenSigFirstTimeoutTime" BU_SG_REL_ ECM SG_ 931 CCBTrgtSpd_SqC 3000;
BA_REL_ "GenSigTimeoutTime" BU_SG_REL_ ECM SG_ 931 CCBTrgtSpd_SqC 600;
BA_REL_ "GenSigFirstTimeoutTime" BU_SG_REL_ TCM SG_ 931 CCBTrgtSpd_SqC 3000;
BA_REL_ "GenSigTimeoutTime" BU_SG_REL_ TCM SG_ 931 CCBTrgtSpd_SqC 600;
BA_REL_ "GenSigFirstTimeoutTime" BU_SG_REL_ ECM SG_ 931 CCTrgtSpd_CRC 3000;
BA_REL_ "GenSigTimeoutTime" BU_SG_REL_ ECM SG_ 931 CCTrgtSpd_CRC 600;
BA_REL_ "GenSigFirstTimeoutTime" BU_SG_REL_ TCM SG_ 931 CCTrgtSpd_CRC 3000;
BA_REL_ "GenSigTimeoutTime" BU_SG_REL_ TCM SG_ 931 CCTrgtSpd_CRC 600;
BA_REL_ "GenSigFirstTimeoutTime" BU_SG_REL_ TCM SG_ 931 CCBTrgtSpd_Rqst 3000;
BA_REL_ "GenSigTimeoutTime" BU_SG_REL_ TCM SG_ 931 CCBTrgtSpd_Rqst 600;
BA_REL_ "GenSigFirstTimeoutTime" BU_SG_REL_ ECM SG_ 931 CCBTrgtSpd_Rqst 3000;
BA_REL_ "GenSigTimeoutTime" BU_SG_REL_ ECM SG_ 931 CCBTrgtSpd_Rqst 600;
BA_REL_ "GenSigFirstTimeoutTime" BU_SG_REL_ TCM SG_ 570 FrontAxleInBumperRange 3000;
BA_REL_ "GenSigTimeoutTime" BU_SG_REL_ TCM SG_ 570 FrontAxleInBumperRange 120;
BA_REL_ "GenSigFirstTimeoutTime" BU_SG_REL_ ECM SG_ 570 RollerBenchModeRequest 3000;
BA_REL_ "GenSigTimeoutTime" BU_SG_REL_ ECM SG_ 570 RollerBenchModeRequest 120;
BA_REL_ "GenSigFirstTimeoutTime" BU_SG_REL_ TCM SG_ 570 RearAxleInBumperRange 3000;
BA_REL_ "GenSigTimeoutTime" BU_SG_REL_ TCM SG_ 570 RearAxleInBumperRange 120;
BA_REL_ "GenSigFirstTimeoutTime" BU_SG_REL_ ECM SG_ 570 TractionControlDriverRqst 3000;
BA_REL_ "GenSigTimeoutTime" BU_SG_REL_ ECM SG_ 570 TractionControlDriverRqst 120;
BA_REL_ "GenSigFirstTimeoutTime" BU_SG_REL_ TCM SG_ 300 XRSLBTrgtSpd_CRC 3000;
BA_REL_ "GenSigTimeoutTime" BU_SG_REL_ TCM SG_ 300 XRSLBTrgtSpd_CRC 60;
BA_REL_ "GenSigFirstTimeoutTime" BU_SG_REL_ ECM SG_ 300 XRSLBTrgtSpd_CRC 3000;
BA_REL_ "GenSigTimeoutTime" BU_SG_REL_ ECM SG_ 300 XRSLBTrgtSpd_CRC 60;
BA_REL_ "GenSigFirstTimeoutTime" BU_SG_REL_ ECM SG_ 300 XRSLTrgtSpd_CRC 3000;
BA_REL_ "GenSigTimeoutTime" BU_SG_REL_ ECM SG_ 300 XRSLTrgtSpd_CRC 60;
BA_REL_ "GenSigFirstTimeoutTime" BU_SG_REL_ TCM SG_ 300 XRSLBTrgtSpd_SqC 3000;
BA_REL_ "GenSigTimeoutTime" BU_SG_REL_ TCM SG_ 300 XRSLBTrgtSpd_SqC 60;
BA_REL_ "GenSigFirstTimeoutTime" BU_SG_REL_ ECM SG_ 300 XRSLBTrgtSpd_SqC 3000;
BA_REL_ "GenSigTimeoutTime" BU_SG_REL_ ECM SG_ 300 XRSLBTrgtSpd_SqC 60;
BA_REL_ "GenSigFirstTimeoutTime" BU_SG_REL_ ECM SG_ 300 XRSLTrgtSpd_SqC 3000;
BA_REL_ "GenSigTimeoutTime" BU_SG_REL_ ECM SG_ 300 XRSLTrgtSpd_SqC 60;
BA_REL_ "GenSigFirstTimeoutTime" BU_SG_REL_ ECM SG_ 300 XRSLTrgtSpd_Rqst 3000;
BA_REL_ "GenSigTimeoutTime" BU_SG_REL_ ECM SG_ 300 XRSLTrgtSpd_Rqst 60;
BA_REL_ "GenSigFirstTimeoutTime" BU_SG_REL_ ECM SG_ 300 XRSLBTrgtSpd_Rqst 3000;
BA_REL_ "GenSigTimeoutTime" BU_SG_REL_ ECM SG_ 300 XRSLBTrgtSpd_Rqst 60;
BA_REL_ "GenSigFirstTimeoutTime" BU_SG_REL_ TCM SG_ 300 XRSLBTrgtSpd_Rqst 3000;
BA_REL_ "GenSigTimeoutTime" BU_SG_REL_ TCM SG_ 300 XRSLBTrgtSpd_Rqst 60;
BA_REL_ "GenSigFirstTimeoutTime" BU_SG_REL_ ECM SG_ 558 ReqdLongAccel_CRC 3000;
BA_REL_ "GenSigTimeoutTime" BU_SG_REL_ ECM SG_ 558 ReqdLongAccel_CRC 120;
BA_REL_ "GenSigFirstTimeoutTime" BU_SG_REL_ TCM SG_ 558 ReqdLongAccel_CRC 3000;
BA_REL_ "GenSigTimeoutTime" BU_SG_REL_ TCM SG_ 558 ReqdLongAccel_CRC 120;
BA_REL_ "GenSigFirstTimeoutTime" BU_SG_REL_ TCM SG_ 558 ReqdLongAccel_CtrlMode 3000;
BA_REL_ "GenSigTimeoutTime" BU_SG_REL_ TCM SG_ 558 ReqdLongAccel_CtrlMode 120;
BA_REL_ "GenSigFirstTimeoutTime" BU_SG_REL_ ECM SG_ 558 ReqdLongAccel_CtrlMode 3000;
BA_REL_ "GenSigTimeoutTime" BU_SG_REL_ ECM SG_ 558 ReqdLongAccel_CtrlMode 120;
BA_REL_ "GenSigFirstTimeoutTime" BU_SG_REL_ ECM SG_ 558 ReqdLongAccel_Accel 3000;
BA_REL_ "GenSigTimeoutTime" BU_SG_REL_ ECM SG_ 558 ReqdLongAccel_Accel 120;
BA_REL_ "GenSigFirstTimeoutTime" BU_SG_REL_ TCM SG_ 558 ReqdLongAccel_Accel 3000;
BA_REL_ "GenSigTimeoutTime" BU_SG_REL_ TCM SG_ 558 ReqdLongAccel_Accel 120;
BA_REL_ "GenSigFirstTimeoutTime" BU_SG_REL_ TCM SG_ 558 ReqdLongAccel_SqC 3000;
BA_REL_ "GenSigTimeoutTime" BU_SG_REL_ TCM SG_ 558 ReqdLongAccel_SqC 120;
BA_REL_ "GenSigFirstTimeoutTime" BU_SG_REL_ ECM SG_ 558 ReqdLongAccel_SqC 3000;
BA_REL_ "GenSigTimeoutTime" BU_SG_REL_ ECM SG_ 558 ReqdLongAccel_SqC 120;
BA_REL_ "GenSigFirstTimeoutTime" BU_SG_REL_ TCM SG_ 556 ReqdLongDist_CRC 3000;
BA_REL_ "GenSigTimeoutTime" BU_SG_REL_ TCM SG_ 556 ReqdLongDist_CRC 120;
BA_REL_ "GenSigFirstTimeoutTime" BU_SG_REL_ TCM SG_ 556 ReqdLongDist_Distance 3000;
BA_REL_ "GenSigTimeoutTime" BU_SG_REL_ TCM SG_ 556 ReqdLongDist_Distance 120;
BA_REL_ "GenSigFirstTimeoutTime" BU_SG_REL_ TCM SG_ 556 ReqdLongDist_AllwdBndLowr 3000;
BA_REL_ "GenSigTimeoutTime" BU_SG_REL_ TCM SG_ 556 ReqdLongDist_AllwdBndLowr 120;
BA_REL_ "GenSigFirstTimeoutTime" BU_SG_REL_ TCM SG_ 556 ReqdLongDist_AllwdBndUppr 3000;
BA_REL_ "GenSigTimeoutTime" BU_SG_REL_ TCM SG_ 556 ReqdLongDist_AllwdBndUppr 120;
BA_REL_ "GenSigFirstTimeoutTime" BU_SG_REL_ TCM SG_ 556 ReqdLongDist_SqC 3000;
BA_REL_ "GenSigTimeoutTime" BU_SG_REL_ TCM SG_ 556 ReqdLongDist_SqC 120;
BA_REL_ "GenSigFirstTimeoutTime" BU_SG_REL_ ECM SG_ 554 ReqdLongSpd_AllwdBndUppr 3000;
BA_REL_ "GenSigTimeoutTime" BU_SG_REL_ ECM SG_ 554 ReqdLongSpd_AllwdBndUppr 120;
BA_REL_ "GenSigFirstTimeoutTime" BU_SG_REL_ TCM SG_ 554 ReqdLongSpd_AllwdBndUppr 3000;
BA_REL_ "GenSigTimeoutTime" BU_SG_REL_ TCM SG_ 554 ReqdLongSpd_AllwdBndUppr 120;
BA_REL_ "GenSigFirstTimeoutTime" BU_SG_REL_ TCM SG_ 554 ReqdLongSpd_CRC 3000;
BA_REL_ "GenSigTimeoutTime" BU_SG_REL_ TCM SG_ 554 ReqdLongSpd_CRC 120;
BA_REL_ "GenSigFirstTimeoutTime" BU_SG_REL_ ECM SG_ 554 ReqdLongSpd_CRC 3000;
BA_REL_ "GenSigTimeoutTime" BU_SG_REL_ ECM SG_ 554 ReqdLongSpd_CRC 120;
BA_REL_ "GenSigFirstTimeoutTime" BU_SG_REL_ TCM SG_ 554 ReqdLongSpd_SqC 3000;
BA_REL_ "GenSigTimeoutTime" BU_SG_REL_ TCM SG_ 554 ReqdLongSpd_SqC 120;
BA_REL_ "GenSigFirstTimeoutTime" BU_SG_REL_ ECM SG_ 554 ReqdLongSpd_SqC 3000;
BA_REL_ "GenSigTimeoutTime" BU_SG_REL_ ECM SG_ 554 ReqdLongSpd_SqC 120;
BA_REL_ "GenSigFirstTimeoutTime" BU_SG_REL_ TCM SG_ 554 ReqdLongSpd_Spd 3000;
BA_REL_ "GenSigTimeoutTime" BU_SG_REL_ TCM SG_ 554 ReqdLongSpd_Spd 120;
BA_REL_ "GenSigFirstTimeoutTime" BU_SG_REL_ ECM SG_ 554 ReqdLongSpd_Spd 3000;
BA_REL_ "GenSigTimeoutTime" BU_SG_REL_ ECM SG_ 554 ReqdLongSpd_Spd 120;
BA_REL_ "GenSigFirstTimeoutTime" BU_SG_REL_ TCM SG_ 554 ReqdLongSpd_AllwdBndLowr 3000;
BA_REL_ "GenSigTimeoutTime" BU_SG_REL_ TCM SG_ 554 ReqdLongSpd_AllwdBndLowr 120;
BA_REL_ "GenSigFirstTimeoutTime" BU_SG_REL_ ECM SG_ 554 ReqdLongSpd_AllwdBndLowr 3000;
BA_REL_ "GenSigTimeoutTime" BU_SG_REL_ ECM SG_ 554 ReqdLongSpd_AllwdBndLowr 120;
BA_REL_ "GenSigFirstTimeoutTime" BU_SG_REL_ TCM SG_ 1246 TagAxleLoad 6000;
BA_REL_ "GenSigTimeoutTime" BU_SG_REL_ TCM SG_ 1246 TagAxleLoad 1500;
BA_REL_ "GenSigFirstTimeoutTime" BU_SG_REL_ TCM SG_ 1246 SecondaryDriveAxleLoad 6000;
BA_REL_ "GenSigTimeoutTime" BU_SG_REL_ TCM SG_ 1246 SecondaryDriveAxleLoad 1500;
BA_REL_ "GenSigFirstTimeoutTime" BU_SG_REL_ TCM SG_ 1246 PusherAxleLoad 6000;
BA_REL_ "GenSigTimeoutTime" BU_SG_REL_ TCM SG_ 1246 PusherAxleLoad 1500;
BA_REL_ "GenSigFirstTimeoutTime" BU_SG_REL_ TCM SG_ 1246 DriveAxleLoad 6000;
BA_REL_ "GenSigTimeoutTime" BU_SG_REL_ TCM SG_ 1246 DriveAxleLoad 1500;
BA_REL_ "GenSigFirstTimeoutTime" BU_SG_REL_ TCM SG_ 731 CCBTargetSpeedRequest 3000;
BA_REL_ "GenSigTimeoutTime" BU_SG_REL_ TCM SG_ 731 CCBTargetSpeedRequest 300;
BA_REL_ "GenSigFirstTimeoutTime" BU_SG_REL_ ECM SG_ 731 CCBTargetSpeedRequest 3000;
BA_REL_ "GenSigTimeoutTime" BU_SG_REL_ ECM SG_ 731 CCBTargetSpeedRequest 300;
BA_REL_ "GenSigFirstTimeoutTime" BU_SG_REL_ TCM SG_ 731 CCTargetSpeedRequest 3000;
BA_REL_ "GenSigTimeoutTime" BU_SG_REL_ TCM SG_ 731 CCTargetSpeedRequest 300;
BA_REL_ "GenSigFirstTimeoutTime" BU_SG_REL_ ECM SG_ 731 CCTargetSpeedRequest 3000;
BA_REL_ "GenSigTimeoutTime" BU_SG_REL_ ECM SG_ 731 CCTargetSpeedRequest 300;
BA_REL_ "GenSigFirstTimeoutTime" BU_SG_REL_ TCM SG_ 731 XRSLBTargetSpeedRequest 3000;
BA_REL_ "GenSigTimeoutTime" BU_SG_REL_ TCM SG_ 731 XRSLBTargetSpeedRequest 300;
BA_REL_ "GenSigFirstTimeoutTime" BU_SG_REL_ ECM SG_ 731 XRSLTargetSpeedRequest 3000;
BA_REL_ "GenSigTimeoutTime" BU_SG_REL_ ECM SG_ 731 XRSLTargetSpeedRequest 300;
BA_REL_ "GenSigFirstTimeoutTime" BU_SG_REL_ TCM SG_ 742 CCBSetSpeed 3000;
BA_REL_ "GenSigTimeoutTime" BU_SG_REL_ TCM SG_ 742 CCBSetSpeed 300;
BA_REL_ "GenSigFirstTimeoutTime" BU_SG_REL_ TCM SG_ 742 CCSetSpeed 3000;
BA_REL_ "GenSigTimeoutTime" BU_SG_REL_ TCM SG_ 742 CCSetSpeed 300;
BA_REL_ "GenSigFirstTimeoutTime" BU_SG_REL_ TCM SG_ 746 Pto1ConsentRequest 3000;
BA_REL_ "GenSigTimeoutTime" BU_SG_REL_ TCM SG_ 746 Pto1ConsentRequest 300;
BA_REL_ "GenSigFirstTimeoutTime" BU_SG_REL_ ECM SG_ 746 SecondThrottle 3000;
BA_REL_ "GenSigTimeoutTime" BU_SG_REL_ ECM SG_ 746 SecondThrottle 300;
BA_REL_ "GenSigFirstTimeoutTime" BU_SG_REL_ TCM SG_ 746 TransferCaseOrSplitboxPTOMode 3000;
BA_REL_ "GenSigTimeoutTime" BU_SG_REL_ TCM SG_ 746 TransferCaseOrSplitboxPTOMode 300;
BA_REL_ "GenSigFirstTimeoutTime" BU_SG_REL_ ECM SG_ 746 PtosStatus 3000;
BA_REL_ "GenSigTimeoutTime" BU_SG_REL_ ECM SG_ 746 PtosStatus 300;
BA_REL_ "GenSigFirstTimeoutTime" BU_SG_REL_ TCM SG_ 746 ConstructionSwitch_stat 3000;
BA_REL_ "GenSigTimeoutTime" BU_SG_REL_ TCM SG_ 746 ConstructionSwitch_stat 300;
BA_REL_ "GenSigFirstTimeoutTime" BU_SG_REL_ ECM SG_ 746 RegenInhibitVehicleHeight 3000;
BA_REL_ "GenSigTimeoutTime" BU_SG_REL_ ECM SG_ 746 RegenInhibitVehicleHeight 300;
BA_REL_ "GenSigFirstTimeoutTime" BU_SG_REL_ ECM SG_ 746 PtoRequest 3000;
BA_REL_ "GenSigTimeoutTime" BU_SG_REL_ ECM SG_ 746 PtoRequest 300;
BA_REL_ "GenSigFirstTimeoutTime" BU_SG_REL_ TCM SG_ 746 Pto2Status 3000;
BA_REL_ "GenSigTimeoutTime" BU_SG_REL_ TCM SG_ 746 Pto2Status 300;
BA_REL_ "GenSigFirstTimeoutTime" BU_SG_REL_ ECM SG_ 746 WarmUp_Request 3000;
BA_REL_ "GenSigTimeoutTime" BU_SG_REL_ ECM SG_ 746 WarmUp_Request 300;
BA_REL_ "GenSigFirstTimeoutTime" BU_SG_REL_ TCM SG_ 746 ParkBrakeReleasePossible_stat 3000;
BA_REL_ "GenSigTimeoutTime" BU_SG_REL_ TCM SG_ 746 ParkBrakeReleasePossible_stat 300;
BA_REL_ "GenSigFirstTimeoutTime" BU_SG_REL_ ECM SG_ 746 AC_CompressorClutchCmd 3000;
BA_REL_ "GenSigTimeoutTime" BU_SG_REL_ ECM SG_ 746 AC_CompressorClutchCmd 300;
BA_REL_ "GenSigFirstTimeoutTime" BU_SG_REL_ TCM SG_ 746 Pto1Status 3000;
BA_REL_ "GenSigTimeoutTime" BU_SG_REL_ TCM SG_ 746 Pto1Status 300;
BA_REL_ "GenSigFirstTimeoutTime" BU_SG_REL_ TCM SG_ 746 CtaGcAlternativeGearStarter 3000;
BA_REL_ "GenSigTimeoutTime" BU_SG_REL_ TCM SG_ 746 CtaGcAlternativeGearStarter 300;
BA_REL_ "GenSigFirstTimeoutTime" BU_SG_REL_ TCM SG_ 746 Pto2ConsentRequest 3000;
BA_REL_ "GenSigTimeoutTime" BU_SG_REL_ TCM SG_ 746 Pto2ConsentRequest 300;
BA_REL_ "GenSigFirstTimeoutTime" BU_SG_REL_ TCM SG_ 746 EngPtoConsumesTorque 3000;
BA_REL_ "GenSigTimeoutTime" BU_SG_REL_ TCM SG_ 746 EngPtoConsumesTorque 300;
BA_REL_ "GenSigFirstTimeoutTime" BU_SG_REL_ ECM SG_ 746 TrailerABSStatus 3000;
BA_REL_ "GenSigTimeoutTime" BU_SG_REL_ ECM SG_ 746 TrailerABSStatus 300;
BA_REL_ "GenSigFirstTimeoutTime" BU_SG_REL_ TCM SG_ 746 TrailerABSStatus 3000;
BA_REL_ "GenSigTimeoutTime" BU_SG_REL_ TCM SG_ 746 TrailerABSStatus 300;
BA_REL_ "GenSigFirstTimeoutTime" BU_SG_REL_ TCM SG_ 746 CtaGcInhibitGearEngaged 3000;
BA_REL_ "GenSigTimeoutTime" BU_SG_REL_ TCM SG_ 746 CtaGcInhibitGearEngaged 300;
BA_REL_ "GenSigFirstTimeoutTime" BU_SG_REL_ TCM SG_ 746 RearEndPositionStatus 3000;
BA_REL_ "GenSigTimeoutTime" BU_SG_REL_ TCM SG_ 746 RearEndPositionStatus 300;
BA_REL_ "GenSigFirstTimeoutTime" BU_SG_REL_ TCM SG_ 746 CtaGcReverseInhibit 3000;
BA_REL_ "GenSigTimeoutTime" BU_SG_REL_ TCM SG_ 746 CtaGcReverseInhibit 300;
BA_REL_ "GenSigFirstTimeoutTime" BU_SG_REL_ ECM SG_ 746 AirCompressorStatus 3000;
BA_REL_ "GenSigTimeoutTime" BU_SG_REL_ ECM SG_ 746 AirCompressorStatus 300;
BA_REL_ "GenSigFirstTimeoutTime" BU_SG_REL_ ECM SG_ 520 EnginePreheat_rqst 3000;
BA_REL_ "GenSigTimeoutTime" BU_SG_REL_ ECM SG_ 520 EnginePreheat_rqst 120;
BA_REL_ "GenSigFirstTimeoutTime" BU_SG_REL_ ECM SG_ 520 EngineCrankRequest 3000;
BA_REL_ "GenSigTimeoutTime" BU_SG_REL_ ECM SG_ 520 EngineCrankRequest 120;
BA_REL_ "GenSigFirstTimeoutTime" BU_SG_REL_ ECM SG_ 520 EngineStopRequest 3000;
BA_REL_ "GenSigTimeoutTime" BU_SG_REL_ ECM SG_ 520 EngineStopRequest 120;
BA_REL_ "GenSigFirstTimeoutTime" BU_SG_REL_ TCM SG_ 520 EngineOperationCtrl 3000;
BA_REL_ "GenSigTimeoutTime" BU_SG_REL_ TCM SG_ 520 EngineOperationCtrl 120;
BA_REL_ "GenSigFirstTimeoutTime" BU_SG_REL_ ECM SG_ 520 EngineOperationCtrl 3000;
BA_REL_ "GenSigTimeoutTime" BU_SG_REL_ ECM SG_ 520 EngineOperationCtrl 120;
BA_REL_ "GenSigFirstTimeoutTime" BU_SG_REL_ TCM SG_ 520 ParkBrakeActuationStatus 3000;
BA_REL_ "GenSigTimeoutTime" BU_SG_REL_ TCM SG_ 520 ParkBrakeActuationStatus 120;
BA_REL_ "GenSigFirstTimeoutTime" BU_SG_REL_ TCM SG_ 520 AcceleratorPedalPositionBackup 3000;
BA_REL_ "GenSigTimeoutTime" BU_SG_REL_ TCM SG_ 520 AcceleratorPedalPositionBackup 120;
BA_REL_ "GenSigFirstTimeoutTime" BU_SG_REL_ ECM SG_ 520 AcceleratorPedalPositionBackup 3000;
BA_REL_ "GenSigTimeoutTime" BU_SG_REL_ ECM SG_ 520 AcceleratorPedalPositionBackup 120;
BA_REL_ "GenSigFirstTimeoutTime" BU_SG_REL_ ECM SG_ 520 XARDACU_AccelDemand 3000;
BA_REL_ "GenSigTimeoutTime" BU_SG_REL_ ECM SG_ 520 XARDACU_AccelDemand 120;
BA_REL_ "GenSigFirstTimeoutTime" BU_SG_REL_ TCM SG_ 520 XARDACU_AccelDemand 3000;
BA_REL_ "GenSigTimeoutTime" BU_SG_REL_ TCM SG_ 520 XARDACU_AccelDemand 120;
BA_REL_ "GenSigFirstTimeoutTime" BU_SG_REL_ TCM SG_ 520 ParkingBrake_stat 3000;
BA_REL_ "GenSigTimeoutTime" BU_SG_REL_ TCM SG_ 520 ParkingBrake_stat 120;
BA_REL_ "GenSigFirstTimeoutTime" BU_SG_REL_ ECM SG_ 520 ParkingBrake_stat 3000;
BA_REL_ "GenSigTimeoutTime" BU_SG_REL_ ECM SG_ 520 ParkingBrake_stat 120;
BA_REL_ "GenSigFirstTimeoutTime" BU_SG_REL_ ECM SG_ 520 EngineSystemPowerDownRequest 3000;
BA_REL_ "GenSigTimeoutTime" BU_SG_REL_ ECM SG_ 520 EngineSystemPowerDownRequest 120;
BA_REL_ "GenSigFirstTimeoutTime" BU_SG_REL_ TCM SG_ 520 TransmSystemPowerDown_rqst 3000;
BA_REL_ "GenSigTimeoutTime" BU_SG_REL_ TCM SG_ 520 TransmSystemPowerDown_rqst 120;
BA_REL_ "GenSigFirstTimeoutTime" BU_SG_REL_ ECM SG_ 520 XARDACU_ControlMode 3000;
BA_REL_ "GenSigTimeoutTime" BU_SG_REL_ ECM SG_ 520 XARDACU_ControlMode 120;
BA_REL_ "GenSigFirstTimeoutTime" BU_SG_REL_ TCM SG_ 520 XARDACU_ControlMode 3000;
BA_REL_ "GenSigTimeoutTime" BU_SG_REL_ TCM SG_ 520 XARDACU_ControlMode 120;
BA_REL_ "GenSigFirstTimeoutTime" BU_SG_REL_ ECM SG_ 1306 DPF_ManualRegenerateRequest 12000;
BA_REL_ "GenSigTimeoutTime" BU_SG_REL_ ECM SG_ 1306 DPF_ManualRegenerateRequest 3000;
BA_REL_ "GenSigFirstTimeoutTime" BU_SG_REL_ ECM SG_ 1306 DPF_ManualRegenerateInhibit 12000;
BA_REL_ "GenSigTimeoutTime" BU_SG_REL_ ECM SG_ 1306 DPF_ManualRegenerateInhibit 3000;
BA_REL_ "GenSigFirstTimeoutTime" BU_SG_REL_ ECM SG_ 1306 WaterInFuelDrainRequest 12000;
BA_REL_ "GenSigTimeoutTime" BU_SG_REL_ ECM SG_ 1306 WaterInFuelDrainRequest 3000;
BA_REL_ "GenSigFirstTimeoutTime" BU_SG_REL_ TCM SG_ 1306 KFactor 12000;
BA_REL_ "GenSigTimeoutTime" BU_SG_REL_ TCM SG_ 1306 KFactor 3000;
BA_REL_ "GenSigFirstTimeoutTime" BU_SG_REL_ ECM SG_ 1306 KFactor 12000;
BA_REL_ "GenSigTimeoutTime" BU_SG_REL_ ECM SG_ 1306 KFactor 3000;
BA_REL_ "GenSigFirstTimeoutTime" BU_SG_REL_ ECM SG_ 930 AcCoolantPumpEngagementRequest 3000;
BA_REL_ "GenSigTimeoutTime" BU_SG_REL_ ECM SG_ 930 AcCoolantPumpEngagementRequest 600;
BA_REL_ "GenSigFirstTimeoutTime" BU_SG_REL_ ECM SG_ 930 ACCoolingFanSpeedRequest 3000;
BA_REL_ "GenSigTimeoutTime" BU_SG_REL_ ECM SG_ 930 ACCoolingFanSpeedRequest 600;
BA_REL_ "GenSigFirstTimeoutTime" BU_SG_REL_ ECM SG_ 930 AirDryerCoolingFanSpeed_rqst 3000;
BA_REL_ "GenSigTimeoutTime" BU_SG_REL_ ECM SG_ 930 AirDryerCoolingFanSpeed_rqst 600;
BA_REL_ "GenSigFirstTimeoutTime" BU_SG_REL_ ECM SG_ 929 SelectedEcoCruiseLevel 3000;
BA_REL_ "GenSigTimeoutTime" BU_SG_REL_ ECM SG_ 929 SelectedEcoCruiseLevel 600;
BA_REL_ "GenSigFirstTimeoutTime" BU_SG_REL_ TCM SG_ 929 SelectedEcoCruiseLevel 3000;
BA_REL_ "GenSigTimeoutTime" BU_SG_REL_ TCM SG_ 929 SelectedEcoCruiseLevel 600;
BA_REL_ "GenSigFirstTimeoutTime" BU_SG_REL_ TCM SG_ 929 ReqdDrvgMode 3000;
BA_REL_ "GenSigTimeoutTime" BU_SG_REL_ TCM SG_ 929 ReqdDrvgMode 600;
BA_REL_ "GenSigFirstTimeoutTime" BU_SG_REL_ ECM SG_ 929 MaintOilReset 3000;
BA_REL_ "GenSigTimeoutTime" BU_SG_REL_ ECM SG_ 929 MaintOilReset 600;
BA_REL_ "GenSigFirstTimeoutTime" BU_SG_REL_ ECM SG_ 929 VIN_rqst 3000;
BA_REL_ "GenSigTimeoutTime" BU_SG_REL_ ECM SG_ 929 VIN_rqst 600;
BA_REL_ "GenSigFirstTimeoutTime" BU_SG_REL_ TCM SG_ 929 VIN_rqst 3000;
BA_REL_ "GenSigTimeoutTime" BU_SG_REL_ TCM SG_ 929 VIN_rqst 600;
BA_REL_ "GenSigFirstTimeoutTime" BU_SG_REL_ ECM SG_ 929 MaintOilQuality 3000;
BA_REL_ "GenSigTimeoutTime" BU_SG_REL_ ECM SG_ 929 MaintOilQuality 600;
BA_REL_ "GenSigFirstTimeoutTime" BU_SG_REL_ TCM SG_ 929 EcoRollEnableRequest 3000;
BA_REL_ "GenSigTimeoutTime" BU_SG_REL_ TCM SG_ 929 EcoRollEnableRequest 600;
BA_REL_ "GenSigFirstTimeoutTime" BU_SG_REL_ TCM SG_ 929 ACCiRollInhibit 3000;
BA_REL_ "GenSigTimeoutTime" BU_SG_REL_ TCM SG_ 929 ACCiRollInhibit 600;
BA_REL_ "GenSigFirstTimeoutTime" BU_SG_REL_ TCM SG_ 929 SpeedAdaptationLevelRqst 3000;
BA_REL_ "GenSigTimeoutTime" BU_SG_REL_ TCM SG_ 929 SpeedAdaptationLevelRqst 600;
BA_REL_ "GenSigFirstTimeoutTime" BU_SG_REL_ ECM SG_ 929 SelfStartAssist_stat 3000;
BA_REL_ "GenSigTimeoutTime" BU_SG_REL_ ECM SG_ 929 SelfStartAssist_stat 600;
BA_REL_ "GenSigFirstTimeoutTime" BU_SG_REL_ TCM SG_ 929 VehGcvw 3000;
BA_REL_ "GenSigTimeoutTime" BU_SG_REL_ TCM SG_ 929 VehGcvw 600;
BA_REL_ "GenSigFirstTimeoutTime" BU_SG_REL_ ECM SG_ 929 VehGcvw 3000;
BA_REL_ "GenSigTimeoutTime" BU_SG_REL_ ECM SG_ 929 VehGcvw 600;
BA_REL_ "GenSigFirstTimeoutTime" BU_SG_REL_ TCM SG_ 929 ACCiSeeDistanceGap 3000;
BA_REL_ "GenSigTimeoutTime" BU_SG_REL_ TCM SG_ 929 ACCiSeeDistanceGap 600;
BA_REL_ "GenSigFirstTimeoutTime" BU_SG_REL_ TCM SG_ 929 RSLAssistStatus 3000;
BA_REL_ "GenSigTimeoutTime" BU_SG_REL_ TCM SG_ 929 RSLAssistStatus 600;
BA_REL_ "GenSigFirstTimeoutTime" BU_SG_REL_ TCM SG_ 391 RequestedUpshiftDownshiftSteps 3000;
BA_REL_ "GenSigTimeoutTime" BU_SG_REL_ TCM SG_ 391 RequestedUpshiftDownshiftSteps 120;
BA_REL_ "GenSigFirstTimeoutTime" BU_SG_REL_ TCM SG_ 391 LiftAxle1PositionStatus 3000;
BA_REL_ "GenSigTimeoutTime" BU_SG_REL_ TCM SG_ 391 LiftAxle1PositionStatus 120;
BA_REL_ "GenSigFirstTimeoutTime" BU_SG_REL_ TCM SG_ 391 LimpHomeSwitch_stat 3000;
BA_REL_ "GenSigTimeoutTime" BU_SG_REL_ TCM SG_ 391 LimpHomeSwitch_stat 120;
BA_REL_ "GenSigFirstTimeoutTime" BU_SG_REL_ TCM SG_ 391 EconomyPowerSwitch_stat 3000;
BA_REL_ "GenSigTimeoutTime" BU_SG_REL_ TCM SG_ 391 EconomyPowerSwitch_stat 120;
BA_REL_ "GenSigFirstTimeoutTime" BU_SG_REL_ ECM SG_ 391 UpShiftRequest 3000;
BA_REL_ "GenSigTimeoutTime" BU_SG_REL_ ECM SG_ 391 UpShiftRequest 120;
BA_REL_ "GenSigFirstTimeoutTime" BU_SG_REL_ TCM SG_ 391 UpShiftRequest 3000;
BA_REL_ "GenSigTimeoutTime" BU_SG_REL_ TCM SG_ 391 UpShiftRequest 120;
BA_REL_ "GenSigFirstTimeoutTime" BU_SG_REL_ TCM SG_ 391 ACCForwardVehicleDistance 3000;
BA_REL_ "GenSigTimeoutTime" BU_SG_REL_ TCM SG_ 391 ACCForwardVehicleDistance 120;
BA_REL_ "GenSigFirstTimeoutTime" BU_SG_REL_ ECM SG_ 391 DownShiftRequest 3000;
BA_REL_ "GenSigTimeoutTime" BU_SG_REL_ ECM SG_ 391 DownShiftRequest 120;
BA_REL_ "GenSigFirstTimeoutTime" BU_SG_REL_ TCM SG_ 391 DownShiftRequest 3000;
BA_REL_ "GenSigTimeoutTime" BU_SG_REL_ TCM SG_ 391 DownShiftRequest 120;
BA_REL_ "GenSigFirstTimeoutTime" BU_SG_REL_ TCM SG_ 391 CM_DisengageDrivelineRequest 3000;
BA_REL_ "GenSigTimeoutTime" BU_SG_REL_ TCM SG_ 391 CM_DisengageDrivelineRequest 120;
BA_REL_ "GenSigFirstTimeoutTime" BU_SG_REL_ TCM SG_ 391 ACC_Status 3000;
BA_REL_ "GenSigTimeoutTime" BU_SG_REL_ TCM SG_ 391 ACC_Status 120;
BA_REL_ "GenSigFirstTimeoutTime" BU_SG_REL_ ECM SG_ 391 SteeringValvePositionSetPoint 3000;
BA_REL_ "GenSigTimeoutTime" BU_SG_REL_ ECM SG_ 391 SteeringValvePositionSetPoint 120;
BA_REL_ "GenSigFirstTimeoutTime" BU_SG_REL_ ECM SG_ 391 GearLeverPosition 3000;
BA_REL_ "GenSigTimeoutTime" BU_SG_REL_ ECM SG_ 391 GearLeverPosition 500;
BA_REL_ "GenSigFirstTimeoutTime" BU_SG_REL_ TCM SG_ 391 GearLeverPosition 3000;
BA_REL_ "GenSigTimeoutTime" BU_SG_REL_ TCM SG_ 391 GearLeverPosition 120;
BA_REL_ "GenSigFirstTimeoutTime" BU_SG_REL_ TCM SG_ 391 RequestForHighestGearRatio 3000;
BA_REL_ "GenSigTimeoutTime" BU_SG_REL_ TCM SG_ 391 RequestForHighestGearRatio 120;
BA_REL_ "GenSigFirstTimeoutTime" BU_SG_REL_ TCM SG_ 391 ACCForwardVehicleSpeed 3000;
BA_REL_ "GenSigTimeoutTime" BU_SG_REL_ TCM SG_ 391 ACCForwardVehicleSpeed 120;
BA_REL_ "GenSigFirstTimeoutTime" BU_SG_REL_ ECM SG_ 1038 ReqdSGoMode_SqC 3000;
BA_REL_ "GenSigTimeoutTime" BU_SG_REL_ ECM SG_ 1038 ReqdSGoMode_SqC 600;
BA_REL_ "GenSigFirstTimeoutTime" BU_SG_REL_ TCM SG_ 1038 ReqdSGoMode_SqC 3000;
BA_REL_ "GenSigTimeoutTime" BU_SG_REL_ TCM SG_ 1038 ReqdSGoMode_SqC 600;
BA_REL_ "GenSigFirstTimeoutTime" BU_SG_REL_ ECM SG_ 1038 ReqdSGoMode_Mode 3000;
BA_REL_ "GenSigTimeoutTime" BU_SG_REL_ ECM SG_ 1038 ReqdSGoMode_Mode 600;
BA_REL_ "GenSigFirstTimeoutTime" BU_SG_REL_ TCM SG_ 1038 ReqdSGoMode_Mode 3000;
BA_REL_ "GenSigTimeoutTime" BU_SG_REL_ TCM SG_ 1038 ReqdSGoMode_Mode 600;
BA_REL_ "GenSigFirstTimeoutTime" BU_SG_REL_ ECM SG_ 1038 ReqdVehLongCtrlM_SqC 3000;
BA_REL_ "GenSigTimeoutTime" BU_SG_REL_ ECM SG_ 1038 ReqdVehLongCtrlM_SqC 600;
BA_REL_ "GenSigFirstTimeoutTime" BU_SG_REL_ TCM SG_ 1038 ReqdVehLongCtrlM_SqC 3000;
BA_REL_ "GenSigTimeoutTime" BU_SG_REL_ TCM SG_ 1038 ReqdVehLongCtrlM_SqC 600;
BA_REL_ "GenSigFirstTimeoutTime" BU_SG_REL_ TCM SG_ 1038 ReqdVehLongCtrlM_CRC 3000;
BA_REL_ "GenSigTimeoutTime" BU_SG_REL_ TCM SG_ 1038 ReqdVehLongCtrlM_CRC 600;
BA_REL_ "GenSigFirstTimeoutTime" BU_SG_REL_ ECM SG_ 1038 ReqdVehLongCtrlM_CRC 3000;
BA_REL_ "GenSigTimeoutTime" BU_SG_REL_ ECM SG_ 1038 ReqdVehLongCtrlM_CRC 600;
BA_REL_ "GenSigFirstTimeoutTime" BU_SG_REL_ TCM SG_ 1038 ReqdDrvgDir_CRC 3000;
BA_REL_ "GenSigTimeoutTime" BU_SG_REL_ TCM SG_ 1038 ReqdDrvgDir_CRC 600;
BA_REL_ "GenSigFirstTimeoutTime" BU_SG_REL_ TCM SG_ 1038 ReqdDrvgDir_SqC 3000;
BA_REL_ "GenSigTimeoutTime" BU_SG_REL_ TCM SG_ 1038 ReqdDrvgDir_SqC 600;
BA_REL_ "GenSigFirstTimeoutTime" BU_SG_REL_ TCM SG_ 1038 ReqdEcoRoll 3000;
BA_REL_ "GenSigTimeoutTime" BU_SG_REL_ TCM SG_ 1038 ReqdEcoRoll 600;
BA_REL_ "GenSigFirstTimeoutTime" BU_SG_REL_ ECM SG_ 1038 ReqdSGoMode_CRC 3000;
BA_REL_ "GenSigTimeoutTime" BU_SG_REL_ ECM SG_ 1038 ReqdSGoMode_CRC 600;
BA_REL_ "GenSigFirstTimeoutTime" BU_SG_REL_ TCM SG_ 1038 ReqdSGoMode_CRC 3000;
BA_REL_ "GenSigTimeoutTime" BU_SG_REL_ TCM SG_ 1038 ReqdSGoMode_CRC 600;
BA_REL_ "GenSigFirstTimeoutTime" BU_SG_REL_ TCM SG_ 1038 ReqdDrvgDir_Direction 3000;
BA_REL_ "GenSigTimeoutTime" BU_SG_REL_ TCM SG_ 1038 ReqdDrvgDir_Direction 600;
BA_REL_ "GenSigFirstTimeoutTime" BU_SG_REL_ TCM SG_ 1038 ReqdVehLongCtrlM_Mode 3000;
BA_REL_ "GenSigTimeoutTime" BU_SG_REL_ TCM SG_ 1038 ReqdVehLongCtrlM_Mode 600;
BA_REL_ "GenSigFirstTimeoutTime" BU_SG_REL_ ECM SG_ 1038 ReqdVehLongCtrlM_Mode 3000;
BA_REL_ "GenSigTimeoutTime" BU_SG_REL_ ECM SG_ 1038 ReqdVehLongCtrlM_Mode 600;
BA_REL_ "GenSigFirstTimeoutTime" BU_SG_REL_ TCM SG_ 1038 ReqdGear 3000;
BA_REL_ "GenSigTimeoutTime" BU_SG_REL_ TCM SG_ 1038 ReqdGear 600;
BA_REL_ "GenSigFirstTimeoutTime" BU_SG_REL_ VCM SG_ 1251 HillDataPkgTECU 12000;
BA_REL_ "GenSigTimeoutTime" BU_SG_REL_ VCM SG_ 1251 HillDataPkgTECU 3000;
BA_REL_ "GenSigFirstTimeoutTime" BU_SG_REL_ VCM SG_ 1250 HillDataCtrlTECU_State 12000;
BA_REL_ "GenSigTimeoutTime" BU_SG_REL_ VCM SG_ 1250 HillDataCtrlTECU_State 3000;
BA_REL_ "GenSigFirstTimeoutTime" BU_SG_REL_ VCM SG_ 1250 HillDataCtrlTECU_AckCnt 12000;
BA_REL_ "GenSigTimeoutTime" BU_SG_REL_ VCM SG_ 1250 HillDataCtrlTECU_AckCnt 3000;
BA_REL_ "GenSigFirstTimeoutTime" BU_SG_REL_ VCM SG_ 1046 DriveModeSwitchUserOverride 3000;
BA_REL_ "GenSigTimeoutTime" BU_SG_REL_ VCM SG_ 1046 DriveModeSwitchUserOverride 600;
VAL_ 567 DriveModeSwitchStat_Rqst 3 "OffOn_NotAvailable" 2 "OffOn_Error" 1 "OffOn_On" 0 "OffOn_Off" ;
VAL_ 567 UpDownShiftRqst_Rqst 15 "UpDownShiftRequest_NotAvailable" 14 "UpDownShiftRequest_Error" 13 "UpDownShiftRequest_Spare7" 12 "UpDownShiftRequest_Spare6" 11 "UpDownShiftRequest_Spare5" 10 "UpDownShiftRequest_Spare4" 9 "UpDownShiftRequest_Spare3" 8 "UpDownShiftRequest_Spare2" 7 "UpDownShiftRequest_Spare1" 6 "UpDownShiftRequest_DownShiftThreeSteps" 5 "UpDownShiftRequest_DownShiftTwoSteps" 4 "UpDownShiftRequest_DownShiftOneStep" 3 "UpDownShiftRequest_UpShiftThreeSteps" 2 "UpDownShiftRequest_UpShiftTwoSteps" 1 "UpDownShiftRequest_UpShiftOneStep" 0 "UpDownShiftRequest_NoRequest" ;
VAL_ 567 GearLeverPosition2_Rqst 15 "GearLeverPosition_NotAvailable" 14 "GearLeverPosition_Error" 13 "GearLeverPosition_SpareValue_06" 12 "GearLeverPosition_SpareValue_05" 11 "GearLeverPosition_SpareValue_04" 10 "GearLeverPosition_SpareValue_03" 9 "GearLeverPosition_SpareValue_02" 8 "GearLeverPosition_SpareValue_01" 7 "GearLeverPosition_SpareValue" 6 "GearLeverPosition_SEG6" 5 "GearLeverPosition_LowGear" 4 "GearLeverPosition_Manual" 3 "GearLeverPosition_Automatic" 2 "GearLeverPosition_Neutral" 1 "GearLeverPosition_Reverse" 0 "GearLeverPosition_GearFoldedAway" ;
VAL_ 725 ESCReqEMS_CtrlTrimStat 7 "CtrlTrimStat_NotAvailable" 6 "CtrlTrimStat_Error" 5 "CtrlTrimStat_Spare_02" 4 "CtrlTrimStat_Spare_01" 3 "CtrlTrimStat_Spare" 2 "CtrlTrimStat_TrimActive" 1 "CtrlTrimStat_ControlActive" 0 "CtrlTrimStat_NoRequestActive" ;
VAL_ 725 StoreIdleValue 3 "StoreIdleValue_NotAvailable" 2 "StoreIdleValue_Error" 1 "StoreIdleValue_StoreSetValue" 0 "StoreIdleValue_DoNOTStoreValue" ;
VAL_ 725 ESCReqEMS_CtrlTrimMode 15 "CtrlTrimMode_NotAvailable" 14 "CtrlTrimMode_Error" 13 "CtrlTrimMode_Spare_08" 12 "CtrlTrimMode_Spare_07" 11 "CtrlTrimMode_Spare_06" 10 "CtrlTrimMode_Spare_05" 9 "CtrlTrimMode_Spare_04" 8 "CtrlTrimMode_Spare_03" 7 "CtrlTrimMode_Spare_02" 6 "CtrlTrimMode_Spare_01" 5 "CtrlTrimMode_Spare" 4 "CtrlTrimMode_MuddySiteEngineSpeedControl" 3 "CtrlTrimMode_AirManagementEngineSpeedControl" 2 "CtrlTrimMode_IdleAdjust" 1 "CtrlTrimMode_PTOEngineSpeedControl" 0 "CtrlTrimMode_NoRequest" ;
VAL_ 725 TrailerConnected 3 "NoYes_NotAvailable" 2 "NoYes_Error" 1 "NoYes_Yes" 0 "NoYes_No" ;
VAL_ 725 ESCReqEMS_CtrlTrimReq 7 "CtrlTrimReq_NotAvailable" 6 "CtrlTrimReq_Error" 5 "CtrlTrimReq_Spare_02" 4 "CtrlTrimReq_Spare_01" 3 "CtrlTrimReq_Spare" 2 "CtrlTrimReq_TrimRampDown" 1 "CtrlTrimReq_TrimRampUp" 0 "CtrlTrimReq_NoRamp" ;
VAL_ 298 ReqTSC_CtrlMode 3 "TSC1EngOverrideCtrlMode_SpeedTorqueLimitControl" 2 "TSC1EngOverrideCtrlMode_TorqueControl" 1 "TSC1EngOverrideCtrlMode_SpeedControl" 0 "TSC1EngOverrideCtrlMode_OverrideDisabled" ;
VAL_ 299 AccPedal_Qlty 3 "PrimaryAcceleratorPedalQuality_NotAvailable" 2 "PrimaryAcceleratorPedalQuality_ErrorMode" 1 "PrimaryAcceleratorPedalQuality_DowngradedMode" 0 "PrimaryAcceleratorPedalQuality_NormalMode" ;
VAL_ 569 ReverseGearEngaged 3 "ReverseGearEngaged_NotAvailable" 2 "ReverseGearEngaged_Error" 1 "ReverseGearEngaged_ReverseGearEngaged" 0 "ReverseGearEngaged_ReverseGearNotEngaged" ;
VAL_ 569 SecuredNeutralPosition 3 "SecuredNeutralPosition_NotAvailable" 2 "SecuredNeutralPosition_Error" 1 "SecuredNeutralPosition_SecuredNeutralPosition" 0 "SecuredNeutralPosition_NotInSecuredNeutralPosition" ;
VAL_ 569 TransmissionNeutralSwitch 3 "TransmissionNeutralSwitch_NotAvailable" 2 "TransmissionNeutralSwitch_Error" 1 "TransmissionNeutralSwitch_TransmissionInNeutral" 0 "TransmissionNeutralSwitch_TransmissionNotInNeutral" ;
VAL_ 569 LevelControlInformation 15 "LevelControlInformation_NotAvailable" 14 "LevelControlInformation_Error" 13 "LevelControlInformation_Reserved_06" 12 "LevelControlInformation_Reserved_05" 11 "LevelControlInformation_Reserved_04" 10 "LevelControlInformation_Reserved_03" 9 "LevelControlInformation_Reserved_02" 8 "LevelControlInformation_Reserved_01" 7 "LevelControlInformation_Reserved" 6 "LevelControlInformation_LimpHome" 5 "LevelControlInformation_FerryFunction" 4 "LevelControlInformation_KneelingHeight" 3 "LevelControlInformation_DriveHeight" 2 "LevelControlInformation_DockingHeight" 1 "LevelControlInformation_HeightAdjustment" 0 "LevelControlInformation_Prohibit" ;
VAL_ 569 TransmLowRangeSenseSwitch 3 "OffOn_NotAvailable" 2 "OffOn_Error" 1 "OffOn_On" 0 "OffOn_Off" ;
VAL_ 568 EngSystPwrDwn_Rqst 3 "InactiveActive_NotAvailable" 2 "InactiveActive_Error" 1 "InactiveActive_Active" 0 "InactiveActive_Inactive" ;
VAL_ 568 EngCrnk_Rqst 3 "EngineCrankRequest_NotAvailable" 2 "EngineCrankRequest_Error" 1 "EngineCrankRequest_StartRequest" 0 "EngineCrankRequest_NoRequest" ;
VAL_ 568 TrnsmSystPwrDwn_Rqst 3 "TransmSystemPowerDown_rqst_DontCare" 2 "TransmSystemPowerDown_rqst_NotDefined" 1 "TransmSystemPowerDown_rqst_PowerDownRequestActive" 0 "TransmSystemPowerDown_rqst_PowerDownRequestInactive" ;
VAL_ 568 EcnmyPwrSwt_Sts 3 "OffOn_NotAvailable" 2 "OffOn_Error" 1 "OffOn_On" 0 "OffOn_Off" ;
VAL_ 1563 MIStatusExtVMCU 3 "MIStatusExt_NotAvailable" 2 "MIStatusExt_Error" 1 "MIStatusExt_Ready" 0 "MIStatusExt_NotReady5Flash" ;
VAL_ 1563 MIStatusVMCU 3 "OffOn_NotAvailable" 2 "OffOn_Error" 1 "OffOn_On" 0 "OffOn_Off" ;
VAL_ 1563 MIDistinctWarningExtVMCU 15 "MIDistinctWarningExt_NotAvailable" 14 "MIDistinctWarningExt_Error" 3 "MIDistinctWarningExt_ContinuousMISteady" 2 "MIDistinctWarningExt_ShortMI3Flash" 1 "MIDistinctWarningExt_OnDemandMI2Flash" 0 "MIDistinctWarningExt_Off1Flash" ;
VAL_ 1563 MIDistinctWarningVMCU 3 "OffOn_NotAvailable" 2 "OffOn_Error" 1 "OffOn_On" 0 "OffOn_Off" ;
VAL_ 1308 ExhManifAirInjectionInhibit 3 "InhibitedStatus_NotAvailable" 2 "InhibitedStatus_Error" 1 "InhibitedStatus_Inhibited" 0 "InhibitedStatus_NotInhibited" ;
VAL_ 1308 HillDataCtrlTGW_State 7 "HillDataState_NotAvailable" 6 "HillDataState_Error" 5 "HillDataState_Spare_03" 4 "HillDataState_Spare_02" 3 "HillDataState_Spare_01" 2 "HillDataState_Receive" 1 "HillDataState_Request" 0 "HillDataState_Idle" ;
VAL_ 1308 DPF_ManualRegenerateTimeReq 3 "NotRequested_NotAvailable" 2 "NotRequested_Error" 1 "NotRequested_Requested" 0 "NotRequested_NotRequested" ;
VAL_ 1241 StarterMotorReset_rqst 3 "Request_NotAvailable" 2 "Request_Error" 1 "Request_RequestActive" 0 "Request_NotRequested" ;
VAL_ 1185 SavedHeightControlMode 3 "SavedHeightControlMode_NotAvailable" 2 "SavedHeightControlMode_Error" 1 "SavedHeightControlMode_Drive" 0 "SavedHeightControlMode_Manual" ;
VAL_ 1185 SpeedAdaptEnableRqst_SpeedLimit 3 "Selected_NotAvailable" 2 "Selected_Error" 1 "Selected_Selected" 0 "Selected_NotSelected" ;
VAL_ 1185 SpeedAdaptEnableRqst_Curve 3 "Selected_NotAvailable" 2 "Selected_Error" 1 "Selected_Selected" 0 "Selected_NotSelected" ;
VAL_ 1185 SpeedAdaptEnableRqst_SlowTraffic 3 "Selected_NotAvailable" 2 "Selected_Error" 1 "Selected_Selected" 0 "Selected_NotSelected" ;
VAL_ 1060 EngOvrrideCtrlStat_FireTruckMode 3 "FireTruckMode_Spare4" 2 "FireTruckMode_Spare3" 1 "FireTruckMode_Spare2" 0 "FireTruckMode_Spare1" ;
VAL_ 1060 EngOvrrideCtrlStat_ProtOvrrMode 3 "InactiveActive_NotAvailable" 2 "InactiveActive_Error" 1 "InactiveActive_Active" 0 "InactiveActive_Inactive" ;
VAL_ 1060 EngOvrrideCtrlStat_StartOvrrMode 3 "InactiveActive_NotAvailable" 2 "InactiveActive_Error" 1 "InactiveActive_Active" 0 "InactiveActive_Inactive" ;
VAL_ 1060 EngineAirShutOffCommandStatus 3 "NotActiveActive_NotAvailable" 2 "NotActiveActive_Error" 1 "NotActiveActive_Active" 0 "NotActiveActive_NotActive" ;
VAL_ 932 ParkBrake_OBDState 3 "ParkBrakeState_NotAvailable" 2 "ParkBrakeState_Error" 1 "ParkBrakeState_Parked" 0 "ParkBrakeState_Released" ;
VAL_ 932 AltParallelOperation 3 "DisableEnable_NotAvailable" 2 "DisableEnable_Error" 1 "DisableEnable_Enable" 0 "DisableEnable_Disable" ;
VAL_ 932 AltLR_cut_offSpeed 31 "AltLR_cut_offSpeed5bit_NotAvailable" 30 "AltLR_cut_offSpeed5bit_Error" 29 "AltLR_cut_offSpeed5bit_Spare14" 28 "AltLR_cut_offSpeed5bit_Spare13" 27 "AltLR_cut_offSpeed5bit_Spare12" 26 "AltLR_cut_offSpeed5bit_Spare11" 25 "AltLR_cut_offSpeed5bit_Spare10" 24 "AltLR_cut_offSpeed5bit_Spare09" 23 "AltLR_cut_offSpeed5bit_Spare08" 22 "AltLR_cut_offSpeed5bit_Spare07" 21 "AltLR_cut_offSpeed5bit_Spare06" 20 "AltLR_cut_offSpeed5bit_Spare05" 19 "AltLR_cut_offSpeed5bit_Spare04" 18 "AltLR_cut_offSpeed5bit_Spare03" 17 "AltLR_cut_offSpeed5bit_Spare02" 16 "AltLR_cut_offSpeed5bit_Spare01" 15 "AltLR_cut_offSpeed5bit_AlwaysActive" 14 "AltLR_cut_offSpeed5bit_6000rpm" 13 "AltLR_cut_offSpeed5bit_4800rpm" 12 "AltLR_cut_offSpeed5bit_4000rpm" 11 "AltLR_cut_offSpeed5bit_3690rpm" 10 "AltLR_cut_offSpeed5bit_3430rpm" 9 "AltLR_cut_offSpeed5bit_3200rpm" 8 "AltLR_cut_offSpeed5bit_3000rpm" 7 "AltLR_cut_offSpeed5bit_2820rpm" 6 "AltLR_cut_offSpeed5bit_2670rpm" 5 "AltLR_cut_offSpeed5bit_2530rpm" 4 "AltLR_cut_offSpeed5bit_2400rpm" 3 "AltLR_cut_offSpeed5bit_2290rpm" 2 "AltLR_cut_offSpeed5bit_2180rpm" 1 "AltLR_cut_offSpeed5bit_2090rpm" 0 "AltLR_cut_offSpeed5bit_2000rpm" ;
VAL_ 932 CruiseControlStates 7 "CruiseControlStates_NotAvailable" 6 "CruiseControlStates_AcceleratorOverride" 5 "CruiseControlStates_Set" 4 "CruiseControlStates_Resume" 3 "CruiseControlStates_Decelerate" 2 "CruiseControlStates_Accelerate" 1 "CruiseControlStates_Hold" 0 "CruiseControlStates_OffDisabled" ;
VAL_ 932 AltDataSelectionWordRx 15 "AltMultiplexSelectedInfo_NotAvailable" 14 "AltMultiplexSelectedInfo_Error" 13 "AltMultiplexSelectedInfo_Spare6" 12 "AltMultiplexSelectedInfo_Spare5" 11 "AltMultiplexSelectedInfo_Spare4" 10 "AltMultiplexSelectedInfo_Spare3" 9 "AltMultiplexSelectedInfo_Spare2" 8 "AltMultiplexSelectedInfo_Spare1" 7 "AltMultiplexSelectedInfo_0x00_3" 6 "AltMultiplexSelectedInfo_ReservedForManufacturer" 5 "AltMultiplexSelectedInfo_0x00_2" 4 "AltMultiplexSelectedInfo_NGen" 3 "AltMultiplexSelectedInfo_IC_temperature" 2 "AltMultiplexSelectedInfo_VoltageMeasured" 1 "AltMultiplexSelectedInfo_VoltageSet" 0 "AltMultiplexSelectedInfo_0x00_1" ;
VAL_ 932 ClutchSwitch 3 "ClutchSwitch_NotAvailable" 2 "ClutchSwitch_Error" 1 "ClutchSwitch_ClutchPedalDepressed" 0 "ClutchSwitch_ClutchPedalReleased" ;
VAL_ 932 AltLR_RampTime 31 "AltLR_RampTime5bit_NotAvailable" 30 "AltLR_RampTime5bit_Error" 29 "AltLR_RampTime5bit_Spare14" 28 "AltLR_RampTime5bit_Spare13" 27 "AltLR_RampTime5bit_Spare12" 26 "AltLR_RampTime5bit_Spare11" 25 "AltLR_RampTime5bit_Spare10" 24 "AltLR_RampTime5bit_Spare09" 23 "AltLR_RampTime5bit_Spare08" 22 "AltLR_RampTime5bit_Spare07" 21 "AltLR_RampTime5bit_Spare06" 20 "AltLR_RampTime5bit_Spare05" 19 "AltLR_RampTime5bit_Spare04" 18 "AltLR_RampTime5bit_Spare03" 17 "AltLR_RampTime5bit_Spare02" 16 "AltLR_RampTime5bit_Spare01" 15 "AltLR_RampTime5bit_15s" 14 "AltLR_RampTime5bit_12s" 13 "AltLR_RampTime5bit_10s" 12 "AltLR_RampTime5bit_9s" 11 "AltLR_RampTime5bit_8s" 10 "AltLR_RampTime5bit_7s" 9 "AltLR_RampTime5bit_6s" 8 "AltLR_RampTime5bit_5s" 7 "AltLR_RampTime5bit_4s" 6 "AltLR_RampTime5bit_3s" 5 "AltLR_RampTime5bit_2s" 4 "AltLR_RampTime5bit_1s" 3 "AltLR_RampTime5bit_0_75s" 2 "AltLR_RampTime5bit_0_5s" 1 "AltLR_RampTime5bit_0_25s" 0 "AltLR_RampTime5bit_Off_0" ;
VAL_ 932 CACCStatus 7 "CACCStatus_NotAvailable" 6 "CACCStatus_Error" 5 "CACCStatus_Spare3" 4 "CACCStatus_Spare2" 3 "CACCStatus_Spare1" 2 "CACCStatus_Active" 1 "CACCStatus_Available" 0 "CACCStatus_Unavailable" ;
VAL_ 570 FrontAxleInBumperRange 3 "AxleInBumperRange_NotAvailable" 2 "AxleInBumperRange_ErrorIndicator" 1 "AxleInBumperRange_ActualLevelWithinBumperRange" 0 "AxleInBumperRange_ActualLevelOutOfBumperRange" ;
VAL_ 570 RollerBenchModeRequest 3 "OffOn_NotAvailable" 2 "OffOn_Error" 1 "OffOn_On" 0 "OffOn_Off" ;
VAL_ 570 RearAxleInBumperRange 3 "AxleInBumperRange_NotAvailable" 2 "AxleInBumperRange_ErrorIndicator" 1 "AxleInBumperRange_ActualLevelWithinBumperRange" 0 "AxleInBumperRange_ActualLevelOutOfBumperRange" ;
VAL_ 570 TractionControlDriverRqst 7 "TractionControlDriverRqst_NotAvailable" 6 "TractionControlDriverRqst_Error" 5 "TractionControlDriverRqst_Spare_01" 4 "TractionControlDriverRqst_Spare" 3 "TractionControlDriverRqst_TractionOFFROAD" 2 "TractionControlDriverRqst_TractionOFF" 1 "TractionControlDriverRqst_TractionON" 0 "TractionControlDriverRqst_NoAction" ;
VAL_ 558 ReqdLongAccel_CtrlMode 3 "XARControlMode_NotDefined" 2 "XARControlMode_CoastingModeRequest" 1 "XARControlMode_AccelerationControlWithMaximumMode" 0 "XARControlMode_OverrideDisabled" ;
VAL_ 746 Pto1ConsentRequest 3 "PtoConsentRequest_NotAvailable" 2 "PtoConsentRequest_Error" 1 "PtoConsentRequest_PTOOperationDesired" 0 "PtoConsentRequest_PTOOperationNotDesired" ;
VAL_ 746 SecondThrottle 3 "InactiveActive_NotAvailable" 2 "InactiveActive_Error" 1 "InactiveActive_Active" 0 "InactiveActive_Inactive" ;
VAL_ 746 TransferCaseOrSplitboxPTOMode 3 "InactiveActive_NotAvailable" 2 "InactiveActive_Error" 1 "InactiveActive_Active" 0 "InactiveActive_Inactive" ;
VAL_ 746 PtosStatus 3 "PtosStatus_NotAvailable" 2 "PtosStatus_Error" 1 "PtosStatus_OneOrMorePTOEngaged" 0 "PtosStatus_NoPTOEngaged" ;
VAL_ 746 ConstructionSwitch_stat 3 "OffOn_NotAvailable" 2 "OffOn_Error" 1 "OffOn_On" 0 "OffOn_Off" ;
VAL_ 746 RegenInhibitVehicleHeight 3 "ActiveStatus_NotAvailable" 2 "ActiveStatus_Error" 1 "ActiveStatus_Active" 0 "ActiveStatus_NotActive" ;
VAL_ 746 PtoRequest 3 "InactiveActive_NotAvailable" 2 "InactiveActive_Error" 1 "InactiveActive_Active" 0 "InactiveActive_Inactive" ;
VAL_ 746 Pto2Status 3 "InactiveActive_NotAvailable" 2 "InactiveActive_Error" 1 "InactiveActive_Active" 0 "InactiveActive_Inactive" ;
VAL_ 746 WarmUp_Request 3 "DisableEnable_NotAvailable" 2 "DisableEnable_Error" 1 "DisableEnable_Enable" 0 "DisableEnable_Disable" ;
VAL_ 746 ParkBrakeReleasePossible_stat 3 "ParkBrakeReleasePossible_stat_NotAvailable" 2 "ParkBrakeReleasePossible_stat_Error" 1 "ParkBrakeReleasePossible_stat_Possible_PressureOK" 0 "ParkBrakeReleasePossible_stat_NotPossible_LowerPressure" ;
VAL_ 746 AC_CompressorClutchCmd 3 "DisengageEngage_NotAvailable" 2 "DisengageEngage_Error" 1 "DisengageEngage_Engage" 0 "DisengageEngage_Disengage" ;
VAL_ 746 Pto1Status 3 "InactiveActive_NotAvailable" 2 "InactiveActive_Error" 1 "InactiveActive_Active" 0 "InactiveActive_Inactive" ;
VAL_ 746 CtaGcAlternativeGearStarter 3 "Request_NotAvailable" 2 "Request_Error" 1 "Request_RequestActive" 0 "Request_NotRequested" ;
VAL_ 746 Pto2ConsentRequest 3 "PtoConsentRequest_NotAvailable" 2 "PtoConsentRequest_Error" 1 "PtoConsentRequest_PTOOperationDesired" 0 "PtoConsentRequest_PTOOperationNotDesired" ;
VAL_ 746 EngPtoConsumesTorque 3 "PtoTorqueRequest_NotAvailable" 2 "PtoTorqueRequest_Error" 1 "PtoTorqueRequest_PtoIsRequestingHighTorque" 0 "PtoTorqueRequest_PtoIsNotRequestingHighTorque" ;
VAL_ 746 TrailerABSStatus 3 "TrailerABSStatus_NotAvailable" 2 "TrailerABSStatus_ErrorIndicator" 1 "TrailerABSStatus_OK" 0 "TrailerABSStatus_Error" ;
VAL_ 746 CtaGcInhibitGearEngaged 3 "Inhibit_NotAvailable" 2 "Inhibit_Error" 1 "Inhibit_InhibitActive" 0 "Inhibit_NoInhibit" ;
VAL_ 746 RearEndPositionStatus 7 "EndPositionStatus_NotAvailable" 6 "EndPositionStatus_Error" 5 "EndPositionStatus_Reserved_01" 4 "EndPositionStatus_Reserved" 3 "EndPositionStatus_LiftingAndLoweringNotAllowed" 2 "EndPositionStatus_MinEndLevelReached" 1 "EndPositionStatus_MaxEndLevelReached" 0 "EndPositionStatus_NoEndLevelReached" ;
VAL_ 746 CtaGcReverseInhibit 3 "Inhibit_NotAvailable" 2 "Inhibit_Error" 1 "Inhibit_InhibitActive" 0 "Inhibit_NoInhibit" ;
VAL_ 746 AirCompressorStatus 3 "InactiveActive_NotAvailable" 2 "InactiveActive_Error" 1 "InactiveActive_Active" 0 "InactiveActive_Inactive" ;
VAL_ 520 EnginePreheat_rqst 3 "Request_NotAvailable" 2 "Request_Error" 1 "Request_RequestActive" 0 "Request_NotRequested" ;
VAL_ 520 EngineCrankRequest 3 "Request_NotAvailable" 2 "Request_Error" 1 "Request_RequestActive" 0 "Request_NotRequested" ;
VAL_ 520 EngineStopRequest 3 "Request_NotAvailable" 2 "Request_Error" 1 "Request_RequestActive" 0 "Request_NotRequested" ;
VAL_ 520 EngineOperationCtrl 7 "EngineOperationCtrl_NotAvailable" 6 "EngineOperationCtrl_Error" 5 "EngineOperationCtrl_Spare3" 4 "EngineOperationCtrl_Spare2" 3 "EngineOperationCtrl_Spare1" 2 "EngineOperationCtrl_DoNotCare" 1 "EngineOperationCtrl_RqstTempEngStopAtStandstill" 0 "EngineOperationCtrl_InhibitTempEngineStop" ;
VAL_ 520 ParkBrakeActuationStatus 7 "ParkBrakeActuationStatus_NotAvailable" 6 "ParkBrakeActuationStatus_Error" 5 "ParkBrakeActuationStatus_SpareValue_01" 4 "ParkBrakeActuationStatus_SpareValue" 3 "ParkBrakeActuationStatus_AntiCompound" 2 "ParkBrakeActuationStatus_Parked" 1 "ParkBrakeActuationStatus_PartiallyParked" 0 "ParkBrakeActuationStatus_Released" ;
VAL_ 520 ParkingBrake_stat 3 "ParkingBrake_stat_NotAvailable" 2 "ParkingBrake_stat_Error" 1 "ParkingBrake_stat_ParkingBrakeActivated" 0 "ParkingBrake_stat_ParkingBrakeReleased" ;
VAL_ 520 EngineSystemPowerDownRequest 3 "Request_NotAvailable" 2 "Request_Error" 1 "Request_RequestActive" 0 "Request_NotRequested" ;
VAL_ 520 TransmSystemPowerDown_rqst 3 "TransmSystemPowerDown_rqst_DontCare" 2 "TransmSystemPowerDown_rqst_NotDefined" 1 "TransmSystemPowerDown_rqst_PowerDownRequestActive" 0 "TransmSystemPowerDown_rqst_PowerDownRequestInactive" ;
VAL_ 520 XARDACU_ControlMode 3 "XARControlMode_NotDefined" 2 "XARControlMode_CoastingModeRequest" 1 "XARControlMode_AccelerationControlWithMaximumMode" 0 "XARControlMode_OverrideDisabled" ;
VAL_ 1306 DPF_ManualRegenerateRequest 3 "Request_NotAvailable" 2 "Request_Error" 1 "Request_RequestActive" 0 "Request_NotRequested" ;
VAL_ 1306 DPF_ManualRegenerateInhibit 3 "InactiveActive_NotAvailable" 2 "InactiveActive_Error" 1 "InactiveActive_Active" 0 "InactiveActive_Inactive" ;
VAL_ 1306 WaterInFuelDrainRequest 3 "Request_NotAvailable" 2 "Request_Error" 1 "Request_RequestActive" 0 "Request_NotRequested" ;
VAL_ 929 SelectedEcoCruiseLevel 7 "SelectedEcoCruiseLevel_NotAvailable" 6 "SelectedEcoCruiseLevel_Error" 5 "SelectedEcoCruiseLevel_Spare01" 4 "SelectedEcoCruiseLevel_Spare" 3 "SelectedEcoCruiseLevel_Level3" 2 "SelectedEcoCruiseLevel_Level2" 1 "SelectedEcoCruiseLevel_Level1" 0 "SelectedEcoCruiseLevel_Off" ;
VAL_ 929 ReqdDrvgMode 15 "ReqdDrvgMode_NotAvailable" 14 "ReqdDrvgMode_Error" 13 "ReqdDrvgMode_Spare7" 12 "ReqdDrvgMode_Spare6" 11 "ReqdDrvgMode_Spare5" 10 "ReqdDrvgMode_Spare4" 9 "ReqdDrvgMode_Spare3" 8 "ReqdDrvgMode_Spare2" 7 "ReqdDrvgMode_Spare1" 6 "ReqdDrvgMode_KickDown" 5 "ReqdDrvgMode_HeavyDuty" 4 "ReqdDrvgMode_OffRoad" 3 "ReqdDrvgMode_Performance" 2 "ReqdDrvgMode_Balanced" 1 "ReqdDrvgMode_EconomyExtra" 0 "ReqdDrvgMode_None" ;
VAL_ 929 MaintOilReset 3 "Request_NotAvailable" 2 "Request_Error" 1 "Request_RequestActive" 0 "Request_NotRequested" ;
VAL_ 929 MaintOilQuality 7 "OilQuality_NotAvailable" 6 "OilQuality_Error" 5 "OilQuality_NoSelectionMade" 4 "OilQuality_VDS4" 3 "OilQuality_VDS3" 2 "OilQuality_VDS5" 1 "OilQuality_VDSVDS3WithFixedInterval" 0 "OilQuality_NonVDS_VDS4WithFixedInterval" ;
VAL_ 929 EcoRollEnableRequest 3 "InactiveActive_NotAvailable" 2 "InactiveActive_Error" 1 "InactiveActive_Active" 0 "InactiveActive_Inactive" ;
VAL_ 929 ACCiRollInhibit 3 "Inhibit_NotAvailable" 2 "Inhibit_Error" 1 "Inhibit_InhibitActive" 0 "Inhibit_NoInhibit" ;
VAL_ 929 SpeedAdaptationLevelRqst 7 "LowMidHigh_NotAvailable" 6 "LowMidHigh_Error" 5 "LowMidHigh_Spare3" 4 "LowMidHigh_Spare2" 3 "LowMidHigh_Spare1" 2 "LowMidHigh_High" 1 "LowMidHigh_Mid" 0 "LowMidHigh_Low" ;
VAL_ 929 SelfStartAssist_stat 3 "SelfStartAssist_stat_NotAvailable" 2 "SelfStartAssist_stat_Requested_Initiated" 1 "SelfStartAssist_stat_Ready" 0 "SelfStartAssist_stat_NotRequested" ;
VAL_ 929 RSLAssistStatus 7 "RSLAssistStatus_NotAvailable" 6 "RSLAssistStatus_Error" 5 "RSLAssistStatus_Spare2" 4 "RSLAssistStatus_Spare1" 3 "RSLAssistStatus_PreActive" 2 "RSLAssistStatus_Active" 1 "RSLAssistStatus_Enable" 0 "RSLAssistStatus_Disable" ;
VAL_ 391 RequestedUpshiftDownshiftSteps 7 "RequestedUpshiftDownshiftSteps_NotAvailable" 6 "RequestedUpshiftDownshiftSteps_Error" 5 "RequestedUpshiftDownshiftSteps_NotDefined_01" 4 "RequestedUpshiftDownshiftSteps_NotDefined" 3 "RequestedUpshiftDownshiftSteps_ThreeSteps" 2 "RequestedUpshiftDownshiftSteps_TwoSteps" 1 "RequestedUpshiftDownshiftSteps_OneStep" 0 "RequestedUpshiftDownshiftSteps_NoRequest" ;
VAL_ 391 LiftAxle1PositionStatus 7 "LiftAxlePositionStatus_NotAvailable" 6 "LiftAxlePositionStatus_Error" 5 "LiftAxlePositionStatus_Reserved_01" 4 "LiftAxlePositionStatus_Reserved" 3 "LiftAxlePositionStatus_Lifting" 2 "LiftAxlePositionStatus_Lowering" 1 "LiftAxlePositionStatus_Lifted" 0 "LiftAxlePositionStatus_Lowered" ;
VAL_ 391 LimpHomeSwitch_stat 3 "OffOn_NotAvailable" 2 "OffOn_Error" 1 "OffOn_On" 0 "OffOn_Off" ;
VAL_ 391 EconomyPowerSwitch_stat 3 "OffOn_NotAvailable" 2 "OffOn_Error" 1 "OffOn_On" 0 "OffOn_Off" ;
VAL_ 391 UpShiftRequest 3 "UpShiftRequest_NotAvailable" 2 "UpShiftRequest_Error" 1 "UpShiftRequest_RequestToDoUpshiftOneStep" 0 "UpShiftRequest_NoRequest" ;
VAL_ 391 DownShiftRequest 3 "DownShiftRequest_NotAvailable" 2 "DownShiftRequest_Error" 1 "DownShiftRequest_RequestToDownshiftOneGear" 0 "DownShiftRequest_NoRequest" ;
VAL_ 391 CM_DisengageDrivelineRequest 3 "CM_DisengageDrivelineRequest_TakeNoAction" 2 "CM_DisengageDrivelineRequest_Reserved" 1 "CM_DisengageDrivelineRequest_DisengageDriveline" 0 "CM_DisengageDrivelineRequest_AllowDrivelineEngagement" ;
VAL_ 391 ACC_Status 7 "ACC_Status_NotAvailable" 6 "ACC_Status_Error" 5 "ACC_Status_ACCFailureAndInactive" 4 "ACC_Status_Reserved" 3 "ACC_Status_ActiveWithLimitedBrakeCapacity" 2 "ACC_Status_ActiveECONOMYMODE" 1 "ACC_Status_ActiveSTANDARDMODE" 0 "ACC_Status_Inactive" ;
VAL_ 391 GearLeverPosition 15 "GearLeverPosition_NotAvailable" 14 "GearLeverPosition_Error" 13 "GearLeverPosition_SpareValue_06" 12 "GearLeverPosition_SpareValue_05" 11 "GearLeverPosition_SpareValue_04" 10 "GearLeverPosition_SpareValue_03" 9 "GearLeverPosition_SpareValue_02" 8 "GearLeverPosition_SpareValue_01" 7 "GearLeverPosition_SpareValue" 6 "GearLeverPosition_SEG6" 5 "GearLeverPosition_LowGear" 4 "GearLeverPosition_Manual" 3 "GearLeverPosition_Automatic" 2 "GearLeverPosition_Neutral" 1 "GearLeverPosition_Reverse" 0 "GearLeverPosition_GearFoldedAway" ;
VAL_ 391 RequestForHighestGearRatio 3 "Request_NotAvailable" 2 "Request_Error" 1 "Request_RequestActive" 0 "Request_NotRequested" ;
VAL_ 1038 ReqdSGoMode_Mode 15 "ACC_SGO_Status_NotAvailable" 14 "ACC_SGO_Status_Error" 13 "ACC_SGO_Status_Spare7" 12 "ACC_SGO_Status_Spare6" 11 "ACC_SGO_Status_Spare5" 10 "ACC_SGO_Status_Spare4" 9 "ACC_SGO_Status_Spare3" 8 "ACC_SGO_Status_Spare2" 7 "ACC_SGO_Status_Spare1" 6 "ACC_SGO_Status_ACC_SGO_Active_TakeOffRequest" 5 "ACC_SGO_Status_ACC_SGO_Active_Hold" 4 "ACC_SGO_Status_ACC_SGO_Active_Stationary" 3 "ACC_SGO_Status_ACC_SGO_Stopping" 2 "ACC_SGO_Status_ACC_SGO_Active_Driving" 1 "ACC_SGO_Status_ACC_SGO_Inactive" 0 "ACC_SGO_Status_ACC_SGO_OFF" ;
VAL_ 1038 ReqdEcoRoll 3 "OffOn_NotAvailable" 2 "OffOn_Error" 1 "OffOn_On" 0 "OffOn_Off" ;
VAL_ 1038 ReqdDrvgDir_Direction 7 "RequestedDrivingDirection_NotAvailable" 6 "RequestedDrivingDirection_Error" 5 "RequestedDrivingDirection_Spare2" 4 "RequestedDrivingDirection_Spare1" 3 "RequestedDrivingDirection_Forward" 2 "RequestedDrivingDirection_Neutral" 1 "RequestedDrivingDirection_Reverse" 0 "RequestedDrivingDirection_Parked" ;
VAL_ 1038 ReqdVehLongCtrlM_Mode 7 "ReqdVehLongCtrlMode_NotAvailable" 6 "ReqdVehLongCtrlMode_Error" 5 "ReqdVehLongCtrlMode_Spare2" 4 "ReqdVehLongCtrlMode_Spare1" 3 "ReqdVehLongCtrlMode_Distance" 2 "ReqdVehLongCtrlMode_Speed" 1 "ReqdVehLongCtrlMode_Acceleration" 0 "ReqdVehLongCtrlMode_Off" ;
VAL_ 1250 HillDataCtrlTECU_State 7 "HillDataState_NotAvailable" 6 "HillDataState_Error" 5 "HillDataState_Spare_03" 4 "HillDataState_Spare_02" 3 "HillDataState_Spare_01" 2 "HillDataState_Receive" 1 "HillDataState_Request" 0 "HillDataState_Idle" ;
VAL_ 1046 DriveModeSwitchUserOverride 7 "DriveModeSwitchUserOverride_NotAvailable" 6 "DriveModeSwitchUserOverride_Error" 5 "DriveModeSwitchUserOverride_Spare" 4 "DriveModeSwitchUserOverride_OverrideStandard" 3 "DriveModeSwitchUserOverride_RequestRange" 2 "DriveModeSwitchUserOverride_OverridePerformance" 1 "DriveModeSwitchUserOverride_AutoSwitch" 0 "DriveModeSwitchUserOverride_None" ;
SIG_GROUP_ 567 GearLeverPosition2_sg 1 : GearLeverPosition2_SqC GearLeverPosition2_Rqst GearLeverPosition2_CRC;
SIG_GROUP_ 567 UpDownShiftRqst_sg 1 : UpDownShiftRqst_Rqst UpDownShiftRqst_SqC UpDownShiftRqst_CRC;
SIG_GROUP_ 567 DriveModeSwitchStat_sg 1 : DriveModeSwitchStat_Rqst DriveModeSwitchStat_CRC DriveModeSwitchStat_SqC;
SIG_GROUP_ 725 ESCReqEMS_sg 1 : ESCReqEMS_CtrlTrimStat ESCReqEMS_CtrlTrimValue ESCReqEMS_CtrlTrimMode ESCReqEMS_CtrlTrimReq;
SIG_GROUP_ 298 ReqTSC_sg 1 : ReqTSC_Tq ReqTSC_CtrlMode ReqTSC_CRC ReqTSC_SqC ReqTSC_Spd;
SIG_GROUP_ 299 AccPedal_sg 1 : AccPedal_CRC AccPedal_SqC AccPedal_Qlty AccPedal_Pos;
SIG_GROUP_ 568 EngSystPwrDwn_sg 1 : EngSystPwrDwn_Rqst EngSystPwrDwn_CRC EngSystPwrDwn_SqC;
SIG_GROUP_ 568 TrnsmSystPwrDwn_sg 1 : TrnsmSystPwrDwn_SqC TrnsmSystPwrDwn_Rqst TrnsmSystPwrDwn_CRC;
SIG_GROUP_ 568 EcnmyPwrSwt_sg 1 : EcnmyPwrSwt_Sts EcnmyPwrSwt_CRC EcnmyPwrSwt_SqC;
SIG_GROUP_ 568 EngCrnk_sg 1 : EngCrnk_Rqst EngCrnk_SqC EngCrnk_CRC;
SIG_GROUP_ 1308 OBDUTCTime_sg 1 : OBDUTCTime_Hours OBDUTCTime_Day OBDUTCTime_Year OBDUTCTime_Month OBDUTCTime_Seconds OBDUTCTime_Minutes;
SIG_GROUP_ 1308 HillDataCtrlTGW_sg 1 : HillDataCtrlTGW_AckCnt HillDataCtrlTGW_State;
SIG_GROUP_ 1185 SpeedAdaptEnableRqst_sg 1 : SpeedAdaptEnableRqst_SpeedLimit SpeedAdaptEnableRqst_Curve SpeedAdaptEnableRqst_SlowTraffic;
SIG_GROUP_ 1060 EngOvrrideCtrlStat_sg 1 : EngOvrrideCtrlStat_FireTruckMode EngOvrrideCtrlStat_ProtOvrrMode EngOvrrideCtrlStat_StartOvrrMode;
SIG_GROUP_ 931 CCTrgtSpd_sg 1 : CCTrgtSpd_SqC CCTrgtSpd_Rqst CCTrgtSpd_CRC;
SIG_GROUP_ 931 CCBTrgtSpd_sg 1 : CCBTrgtSpd_CRC CCBTrgtSpd_SqC CCBTrgtSpd_Rqst;
SIG_GROUP_ 300 XRSLTrgtSpd_sg 1 : XRSLTrgtSpd_CRC XRSLTrgtSpd_SqC XRSLTrgtSpd_Rqst;
SIG_GROUP_ 300 XRSLBTrgtSpd_sg 1 : XRSLBTrgtSpd_CRC XRSLBTrgtSpd_SqC XRSLBTrgtSpd_Rqst;
SIG_GROUP_ 558 ReqdLongAccel_sg 1 : ReqdLongAccel_CRC ReqdLongAccel_CtrlMode ReqdLongAccel_Accel ReqdLongAccel_SqC;
SIG_GROUP_ 556 ReqdLongDist_sg 1 : ReqdLongDist_CRC ReqdLongDist_Distance ReqdLongDist_AllwdBndLowr ReqdLongDist_AllwdBndUppr ReqdLongDist_SqC;
SIG_GROUP_ 554 ReqdLongSpd_sg 1 : ReqdLongSpd_AllwdBndUppr ReqdLongSpd_CRC ReqdLongSpd_SqC ReqdLongSpd_Spd ReqdLongSpd_AllwdBndLowr;
SIG_GROUP_ 520 XARDACU_sg 1 : XARDACU_AccelDemand XARDACU_ControlMode;
SIG_GROUP_ 1038 ReqdDrvgDir_sg 1 : ReqdDrvgDir_CRC ReqdDrvgDir_SqC ReqdDrvgDir_Direction;
SIG_GROUP_ 1038 ReqdSGoMode_sg 1 : ReqdSGoMode_SqC ReqdSGoMode_Mode ReqdSGoMode_CRC;
SIG_GROUP_ 1038 ReqdVehLongCtrlM_sg 1 : ReqdVehLongCtrlM_SqC ReqdVehLongCtrlM_CRC ReqdVehLongCtrlM_Mode;
SIG_GROUP_ 1250 HillDataCtrlTECU_sg 1 : HillDataCtrlTECU_State HillDataCtrlTECU_AckCnt;
